VERSION ""

NS_ :

BS_:

BU_: IHU

BO_ 1537 NMm_Others: 8 Vector__XXX
 SG_ Nwmcommand1 : 7|1@0+ (1,0) [0|1] ""  IHU

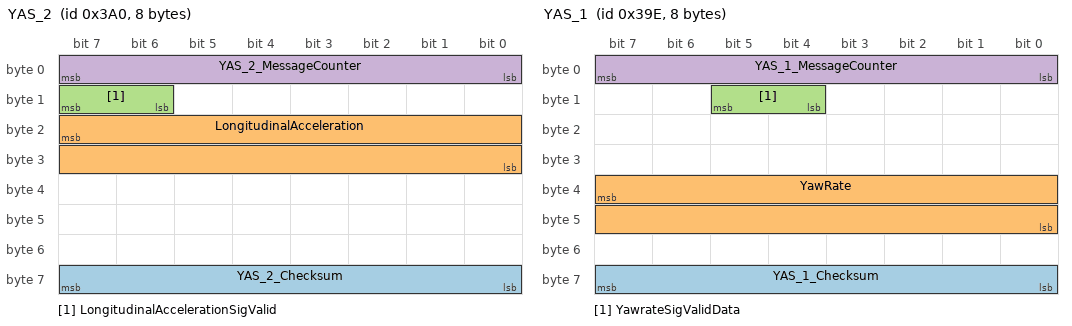
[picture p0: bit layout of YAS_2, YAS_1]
BO_ 928 YAS_2: 8 Vector__XXX
 SG_ YAS_2_Checksum : 63|8@0+ (1,0) [0|255] ""  IHU
 SG_ LongitudinalAcceleration : 23|16@0+ (0.001,-2) [-2|2] "g"  IHU
 SG_ LongitudinalAccelerationSigValid : 15|2@0+ (1,0) [0|3] ""  IHU
 SG_ YAS_2_MessageCounter : 7|8@0+ (1,0) [0|255] ""  IHU

BO_ 926 YAS_1: 8 Vector__XXX
 SG_ YAS_1_Checksum : 63|8@0+ (1,0) [0|255] ""  IHU
 SG_ YawRate : 39|16@0+ (0.01,-180) [-180|180] "deg/sec"  IHU
 SG_ YawrateSigValidData : 13|2@0+ (1,0) [0|3] ""  IHU
 SG_ YAS_1_MessageCounter : 7|8@0+ (1,0) [0|255] ""  IHU

BO_ 1206 SHU2R_1: 8 Vector__XXX
 SG_ SHU2R_RSeatVentnSts : 5|3@0+ (1,0) [0|7] ""  IHU
 SG_ SHU2R_RSeatHeatSts : 2|3@0+ (1,0) [0|7] ""  IHU

BO_ 1202 SHU2M_1: 8 Vector__XXX
 SG_ SHU2M_MSeatVentnSts : 5|3@0+ (1,0) [0|7] ""  IHU
 SG_ SHU2M_MSeatHeatSts : 2|3@0+ (1,0) [0|7] ""  IHU

BO_ 1194 SHU2L_1: 8 Vector__XXX
 SG_ SHU2L_LSeatVentnSts : 5|3@0+ (1,0) [0|7] ""  IHU
 SG_ SHU2L_LSeatHeatSts : 2|3@0+ (1,0) [0|7] ""  IHU

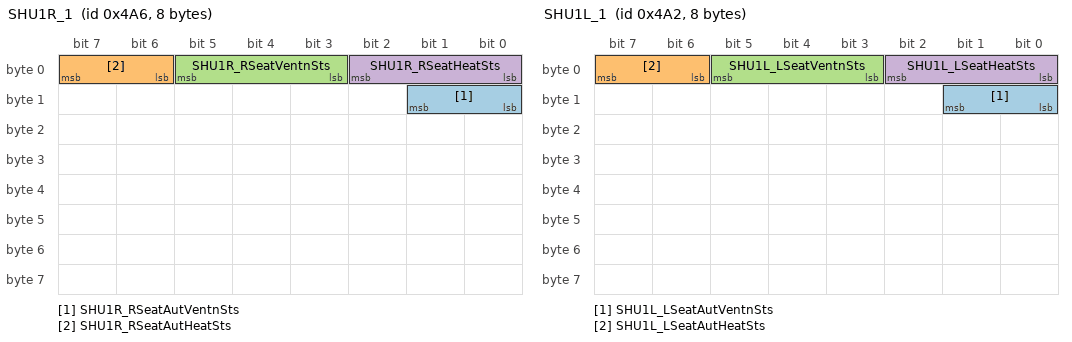
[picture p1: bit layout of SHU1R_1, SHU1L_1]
BO_ 1190 SHU1R_1: 8 Vector__XXX
 SG_ SHU1R_RSeatAutVentnSts : 9|2@0+ (1,0) [0|3] ""  IHU
 SG_ SHU1R_RSeatAutHeatSts : 7|2@0+ (1,0) [0|3] ""  IHU
 SG_ SHU1R_RSeatVentnSts : 5|3@0+ (1,0) [0|7] ""  IHU
 SG_ SHU1R_RSeatHeatSts : 2|3@0+ (1,0) [0|7] ""  IHU

BO_ 1186 SHU1L_1: 8 Vector__XXX
 SG_ SHU1L_LSeatAutVentnSts : 9|2@0+ (1,0) [0|3] ""  IHU
 SG_ SHU1L_LSeatAutHeatSts : 7|2@0+ (1,0) [0|3] ""  IHU
 SG_ SHU1L_LSeatVentnSts : 5|3@0+ (1,0) [0|7] ""  IHU
 SG_ SHU1L_LSeatHeatSts : 2|3@0+ (1,0) [0|7] ""  IHU

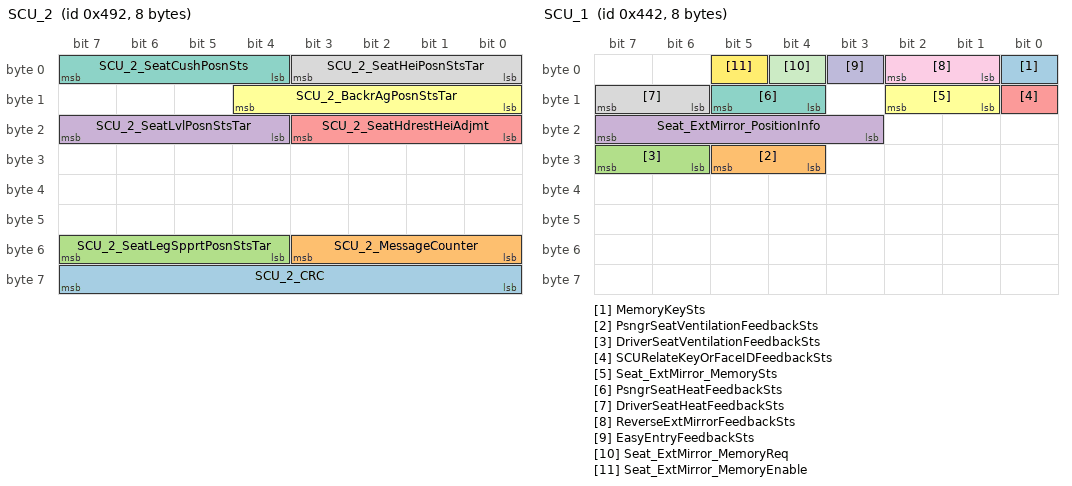
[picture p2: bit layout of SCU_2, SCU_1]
BO_ 1170 SCU_2: 8 Vector__XXX
 SG_ SCU_2_CRC : 63|8@0+ (1,0) [0|255] ""  IHU
 SG_ SCU_2_MessageCounter : 51|4@0+ (1,0) [0|15] ""  IHU
 SG_ SCU_2_SeatLegSpprtPosnStsTar : 55|4@0+ (10,0) [0|100] "%"  IHU
 SG_ SCU_2_SeatLvlPosnStsTar : 23|4@0+ (10,0) [0|100] "%"  IHU
 SG_ SCU_2_SeatHdrestHeiAdjmt : 19|4@0+ (10,0) [0|100] "%"  IHU
 SG_ SCU_2_BackrAgPosnStsTar : 12|5@0+ (5,0) [0|100] "%"  IHU
 SG_ SCU_2_SeatCushPosnSts : 7|4@0+ (10,0) [0|100] "%"  IHU
 SG_ SCU_2_SeatHeiPosnStsTar : 3|4@0+ (10,0) [0|100] "%"  IHU

BO_ 1090 SCU_1: 8 Vector__XXX
 SG_ MemoryKeySts : 0|1@0+ (1,0) [0|1] ""  IHU
 SG_ PsngrSeatVentilationFeedbackSts : 29|2@0+ (1,0) [0|3] ""  IHU
 SG_ DriverSeatVentilationFeedbackSts : 31|2@0+ (1,0) [0|3] ""  IHU
 SG_ Seat_ExtMirror_PositionInfo : 23|5@0+ (1,0) [0|31] ""  IHU
 SG_ SCURelateKeyOrFaceIDFeedbackSts : 8|1@0+ (1,0) [0|1] ""  IHU
 SG_ Seat_ExtMirror_MemorySts : 10|2@0+ (1,0) [0|3] ""  IHU
 SG_ PsngrSeatHeatFeedbackSts : 13|2@0+ (1,0) [0|3] ""  IHU
 SG_ DriverSeatHeatFeedbackSts : 15|2@0+ (1,0) [0|3] ""  IHU
 SG_ ReverseExtMirrorFeedbackSts : 2|2@0+ (1,0) [0|3] ""  IHU
 SG_ EasyEntryFeedbackSts : 3|1@0+ (1,0) [0|1] ""  IHU
 SG_ Seat_ExtMirror_MemoryReq : 4|1@0+ (1,0) [0|1] ""  IHU
 SG_ Seat_ExtMirror_MemoryEnable : 5|1@0+ (1,0) [0|1] ""  IHU

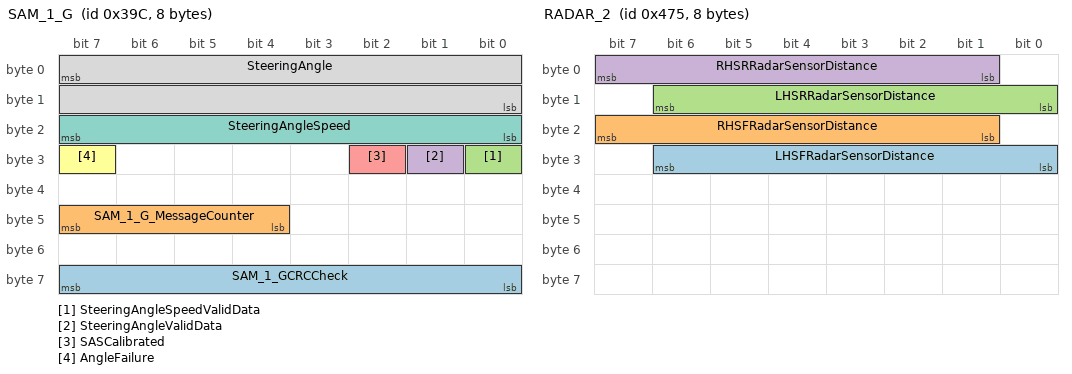
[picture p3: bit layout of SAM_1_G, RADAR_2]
BO_ 924 SAM_1_G: 8 Vector__XXX
 SG_ SAM_1_GCRCCheck : 63|8@0+ (1,0) [0|255] ""  IHU
 SG_ SAM_1_G_MessageCounter : 47|4@0+ (1,0) [0|15] ""  IHU
 SG_ SteeringAngleSpeedValidData : 24|1@0+ (1,0) [0|1] ""  IHU
 SG_ SteeringAngleValidData : 25|1@0+ (1,0) [0|1] ""  IHU
 SG_ SASCalibrated : 26|1@0+ (1,0) [0|1] ""  IHU
 SG_ AngleFailure : 31|1@0+ (1,0) [0|1] ""  IHU
 SG_ SteeringAngleSpeed : 23|8@0+ (4,0) [0|1016] "deg/Sec"  IHU
 SG_ SteeringAngle : 7|16@0+ (0.0625,-2048) [-2048|2047.875] "deg"  IHU

BO_ 498 RLCR_2: 8 Vector__XXX
 SG_ RLCR_2_RCTBONOFFSts : 5|2@0+ (1,0) [0|3] ""  IHU
 SG_ RLCR_2_RAEBONOFFSts : 3|2@0+ (1,0) [0|3] ""  IHU

BO_ 1141 RADAR_2: 8 Vector__XXX
 SG_ LHSFRadarSensorDistance : 30|7@0+ (5,30) [30|500] "cm"  IHU
 SG_ RHSFRadarSensorDistance : 23|7@0+ (5,30) [30|500] "cm"  IHU
 SG_ LHSRRadarSensorDistance : 14|7@0+ (5,30) [30|500] "cm"  IHU
 SG_ RHSRRadarSensorDistance : 7|7@0+ (5,30) [30|500] "cm"  IHU

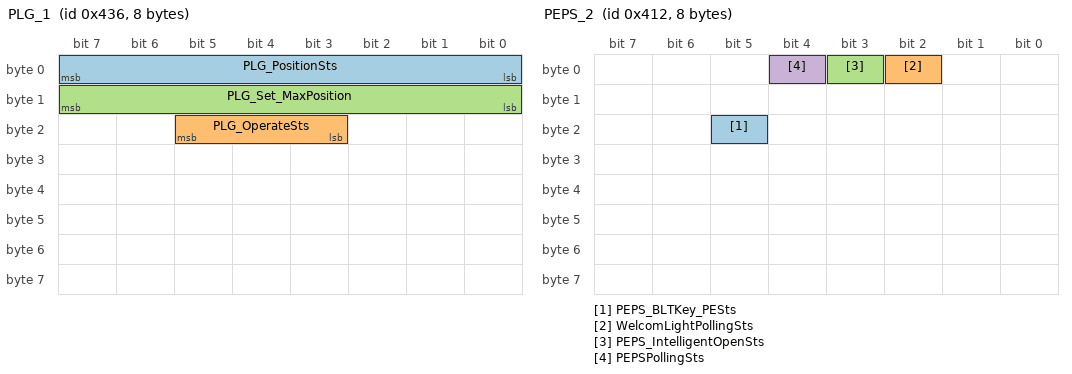
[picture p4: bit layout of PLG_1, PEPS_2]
BO_ 1078 PLG_1: 8 Vector__XXX
 SG_ PLG_PositionSts : 7|8@0+ (1,0) [0|100] "%"  IHU
 SG_ PLG_OperateSts : 21|3@0+ (1,0) [0|7] ""  IHU
 SG_ PLG_Set_MaxPosition : 15|8@0+ (1,0) [0|100] "%"  IHU

BO_ 1042 PEPS_2: 8 Vector__XXX
 SG_ PEPS_BLTKey_PESts : 21|1@0+ (1,0) [0|1] ""  IHU
 SG_ WelcomLightPollingSts : 2|1@0+ (1,0) [0|1] ""  IHU
 SG_ PEPS_IntelligentOpenSts : 3|1@0+ (1,0) [0|1] ""  IHU
 SG_ PEPSPollingSts : 4|1@0+ (1,0) [0|1] ""  IHU

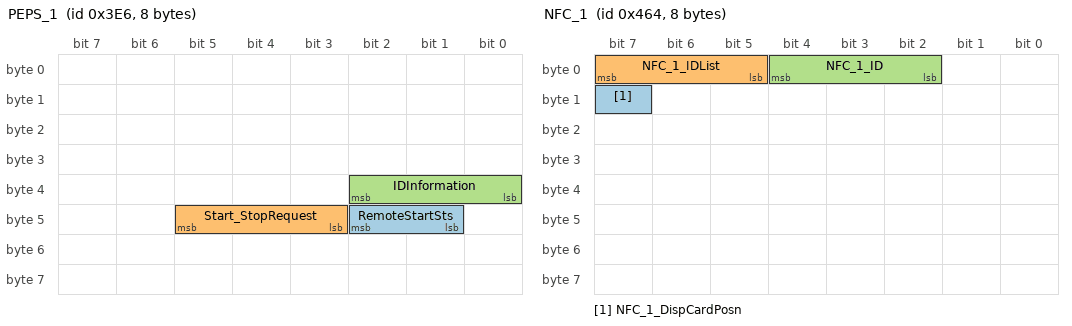
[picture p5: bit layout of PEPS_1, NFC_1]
BO_ 998 PEPS_1: 8 Vector__XXX
 SG_ RemoteStartSts : 42|2@0+ (1,0) [0|3] ""  IHU
 SG_ Start_StopRequest : 45|3@0+ (1,0) [0|7] ""  IHU
 SG_ IDInformation : 34|3@0+ (1,0) [0|7] ""  IHU

BO_ 1124 NFC_1: 8 Vector__XXX
 SG_ NFC_1_DispCardPosn : 15|1@0+ (1,0) [0|1] ""  IHU
 SG_ NFC_1_IDList : 7|3@0+ (1,0) [0|7] ""  IHU
 SG_ NFC_1_ID : 4|3@0+ (1,0) [0|7] ""  IHU

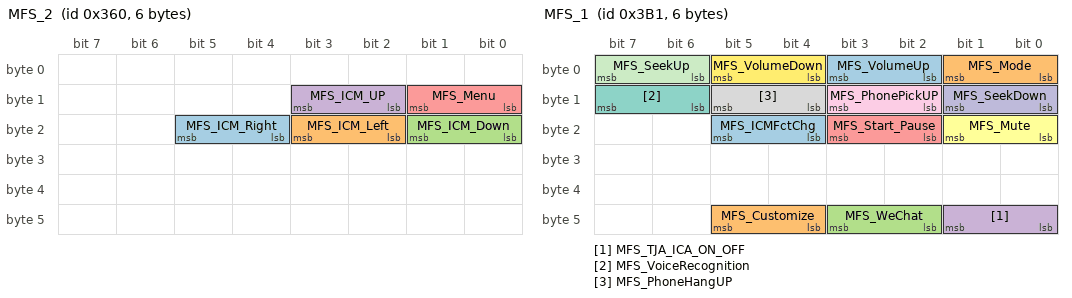
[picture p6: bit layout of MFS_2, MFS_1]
BO_ 864 MFS_2: 6 Vector__XXX
 SG_ MFS_ICM_Right : 21|2@0+ (1,0) [0|3] ""  IHU
 SG_ MFS_ICM_Left : 19|2@0+ (1,0) [0|3] ""  IHU
 SG_ MFS_ICM_Down : 17|2@0+ (1,0) [0|3] ""  IHU
 SG_ MFS_ICM_UP : 11|2@0+ (1,0) [0|3] ""  IHU
 SG_ MFS_Menu : 9|2@0+ (1,0) [0|3] ""  IHU

BO_ 945 MFS_1: 6 Vector__XXX
 SG_ MFS_ICMFctChg : 21|2@0+ (1,0) [0|3] "" Vector__XXX
 SG_ MFS_Customize : 45|2@0+ (1,0) [0|3] ""  IHU
 SG_ MFS_WeChat : 43|2@0+ (1,0) [0|3] ""  IHU
 SG_ MFS_TJA_ICA_ON_OFF : 41|2@0+ (1,0) [0|3] ""  IHU
 SG_ MFS_Start_Pause : 19|2@0+ (1,0) [0|3] ""  IHU
 SG_ MFS_Mute : 17|2@0+ (1,0) [0|3] ""  IHU
 SG_ MFS_VoiceRecognition : 15|2@0+ (1,0) [0|3] ""  IHU
 SG_ MFS_PhoneHangUP : 13|2@0+ (1,0) [0|3] ""  IHU
 SG_ MFS_PhonePickUP : 11|2@0+ (1,0) [0|3] ""  IHU
 SG_ MFS_SeekDown : 9|2@0+ (1,0) [0|3] ""  IHU
 SG_ MFS_SeekUp : 7|2@0+ (1,0) [0|3] ""  IHU
 SG_ MFS_VolumeDown : 5|2@0+ (1,0) [0|3] ""  IHU
 SG_ MFS_VolumeUp : 3|2@0+ (1,0) [0|3] ""  IHU
 SG_ MFS_Mode : 1|2@0+ (1,0) [0|3] ""  IHU

BO_ 1149 IMMO_12: 8 Vector__XXX
 SG_ IMMO_Teach : 7|64@0+ (1,0) [0|0] ""  IHU

BO_ 1110 IMMO_11: 8 Vector__XXX
 SG_ IMMO_Chall : 7|64@0+ (1,0) [0|0] ""  IHU

BO_ 1508 ICM_IHU_Interaction: 8 Vector__XXX
 SG_ ICM_4_InteractiveDisplayInfo : 7|64@0+ (1,0) [0|0] ""  IHU

BO_ 1248 IDCU_11: 8 Vector__XXX
 SG_ IDCU_11_DrvAssiStylests : 8|2@0+ (1,0) [0|3] ""  IHU
 SG_ IDCU_11_DCLCONOFFsts : 10|2@0+ (1,0) [0|3] ""  IHU

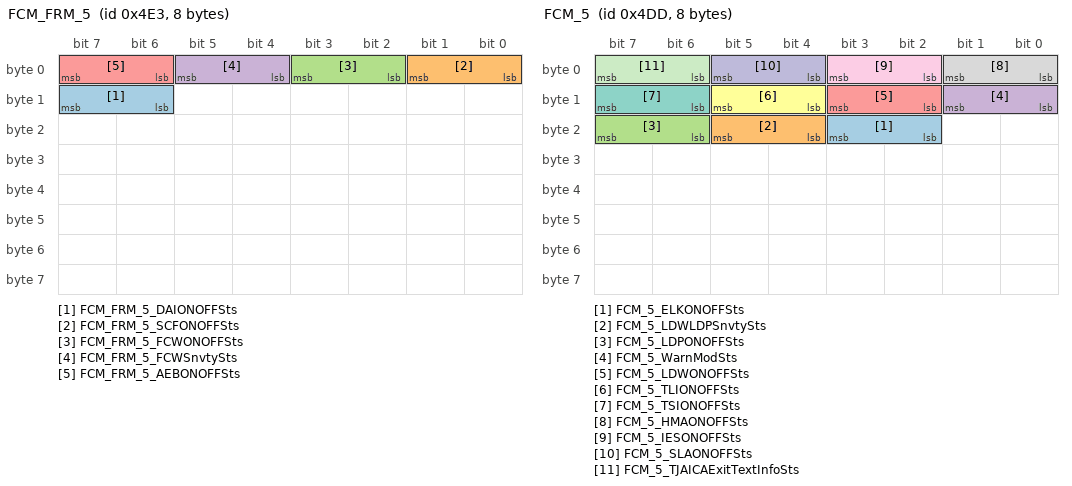
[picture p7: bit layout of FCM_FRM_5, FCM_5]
BO_ 1251 FCM_FRM_5: 8 Vector__XXX
 SG_ FCM_FRM_5_DAIONOFFSts : 15|2@0+ (1,0) [0|3] ""  IHU
 SG_ FCM_FRM_5_SCFONOFFSts : 1|2@0+ (1,0) [0|3] ""  IHU
 SG_ FCM_FRM_5_FCWONOFFSts : 3|2@0+ (1,0) [0|3] ""  IHU
 SG_ FCM_FRM_5_FCWSnvtySts : 5|2@0+ (1,0) [0|3] ""  IHU
 SG_ FCM_FRM_5_AEBONOFFSts : 7|2@0+ (1,0) [0|3] ""  IHU

BO_ 1245 FCM_5: 8 Vector__XXX
 SG_ FCM_5_ELKONOFFSts : 19|2@0+ (1,0) [0|3] ""  IHU
 SG_ FCM_5_LDWLDPSnvtySts : 21|2@0+ (1,0) [0|3] ""  IHU
 SG_ FCM_5_LDPONOFFSts : 23|2@0+ (1,0) [0|3] ""  IHU
 SG_ FCM_5_WarnModSts : 9|2@0+ (1,0) [0|3] ""  IHU
 SG_ FCM_5_LDWONOFFSts : 11|2@0+ (1,0) [0|3] ""  IHU
 SG_ FCM_5_TLIONOFFSts : 13|2@0+ (1,0) [0|3] ""  IHU
 SG_ FCM_5_TSIONOFFSts : 15|2@0+ (1,0) [0|3] ""  IHU
 SG_ FCM_5_HMAONOFFSts : 1|2@0+ (1,0) [0|3] ""  IHU
 SG_ FCM_5_IESONOFFSts : 3|2@0+ (1,0) [0|3] ""  IHU
 SG_ FCM_5_SLAONOFFSts : 5|2@0+ (1,0) [0|3] ""  IHU
 SG_ FCM_5_TJAICAExitTextInfoSts : 7|2@0+ (1,0) [0|3] ""  IHU

BO_ 1240 EMS_3_G: 8 Vector__XXX
 SG_ EMS_BoostP : 39|16@0+ (0.078125,0) [0|5119] "hPa"  IHU

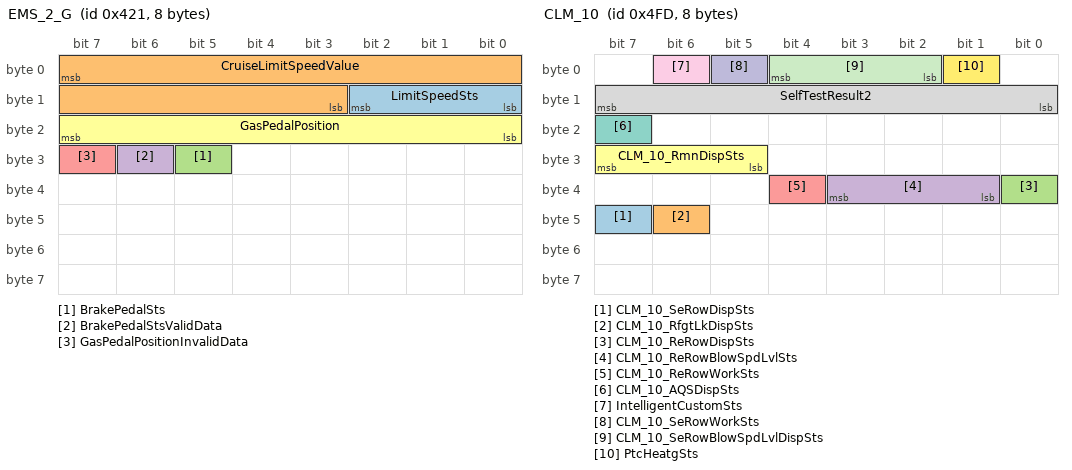
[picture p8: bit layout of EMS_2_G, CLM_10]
BO_ 1057 EMS_2_G: 8 Vector__XXX
 SG_ LimitSpeedSts : 10|3@0+ (1,0) [0|7] ""  IHU
 SG_ CruiseLimitSpeedValue : 7|13@0+ (0.0625,0) [0|511.875] "km/h"  IHU
 SG_ BrakePedalSts : 29|1@0+ (1,0) [0|1] ""  IHU
 SG_ BrakePedalStsValidData : 30|1@0+ (1,0) [0|1] ""  IHU
 SG_ GasPedalPositionInvalidData : 31|1@0+ (1,0) [0|1] ""  IHU
 SG_ GasPedalPosition : 23|8@0+ (0.392,0) [0|99.568] "%"  IHU

BO_ 1277 CLM_10: 8 Vector__XXX
 SG_ CLM_10_SeRowDispSts : 47|1@0+ (1,0) [0|1] ""  IHU
 SG_ CLM_10_RfgtLkDispSts : 46|1@0+ (1,0) [0|1] ""  IHU
 SG_ CLM_10_ReRowDispSts : 32|1@0+ (1,0) [0|1] ""  IHU
 SG_ CLM_10_ReRowBlowSpdLvlSts : 35|3@0+ (1,0) [0|7] ""  IHU
 SG_ CLM_10_ReRowWorkSts : 36|1@0+ (1,0) [0|1] ""  IHU
 SG_ CLM_10_RmnDispSts : 31|3@0+ (1,0) [0|7] ""  IHU
 SG_ CLM_10_AQSDispSts : 23|1@0+ (1,0) [0|1] ""  IHU
 SG_ SelfTestResult2 : 15|8@0+ (1,0) [0|255] ""  IHU
 SG_ IntelligentCustomSts : 6|1@0+ (1,0) [0|1] ""  IHU
 SG_ CLM_10_SeRowWorkSts : 5|1@0+ (1,0) [0|1] ""  IHU
 SG_ CLM_10_SeRowBlowSpdLvlDispSts : 4|3@0+ (1,0) [0|7] ""  IHU
 SG_ PtcHeatgSts : 1|1@0+ (1,0) [0|1] ""  IHU

BO_ 1334 CLM_3: 8 Vector__XXX
 SG_ FragranCeconsistenceLevelSts : 58|3@0+ (1,0) [0|7] ""  IHU
 SG_ Pos3_FragranceTypesSts : 49|3@0+ (1,0) [0|7] ""  IHU
 SG_ Pos2_FragranceTypesSts : 62|3@0+ (1,0) [0|7] ""  IHU
 SG_ PM2_5AutoRunSetSts : 59|1@0+ (1,0) [0|1] ""  IHU
 SG_ PM2_5_Incar_Level : 52|3@0+ (1,0) [0|7] ""  IHU
 SG_ PM2_5_Outcar_Level : 55|3@0+ (1,0) [0|7] ""  IHU
 SG_ FragranceDisplaysts : 40|1@0+ (1,0) [0|1] ""  IHU
 SG_ FragrancePositionSwt : 24|2@0+ (1,0) [0|3] ""  IHU
 SG_ ACModeCustomSts : 42|2@0+ (1,0) [0|3] ""  IHU
 SG_ FragranceWelcomeModeSts : 44|1@0+ (1,0) [0|1] ""  IHU
 SG_ RefreshFunctionSts : 43|1@0+ (1,0) [0|1] ""  IHU
 SG_ Pos1_FragranceTypesSts : 47|3@0+ (1,0) [0|7] ""  IHU
 SG_ PM2_5AutoRunSts : 33|1@0+ (1,0) [0|1] ""  IHU
 SG_ FragranceSWSts : 36|2@0+ (1,0) [0|3] ""  IHU
 SG_ AutoBltCalllowBlowSpeedSts : 37|1@0+ (1,0) [0|1] ""  IHU
 SG_ AutoParkInnerCirculationSts : 38|1@0+ (1,0) [0|1] ""  IHU
 SG_ PM2_5_IncarSts : 26|1@0+ (1,0) [0|1] ""  IHU
 SG_ PM2_5_ExtSts : 27|1@0+ (1,0) [0|1] ""  IHU
 SG_ PM2_5_ext : 23|10@0+ (1,0) [0|1000] "ug/m3"  IHU
 SG_ FragranceShortageWarning : 6|3@0+ (1,0) [0|7] ""  IHU
 SG_ ION_Function_Sts : 3|2@0+ (1,0) [0|3] ""  IHU
 SG_ PM2_5_incar : 1|10@0+ (1,0) [0|1000] "ug/m3"  IHU

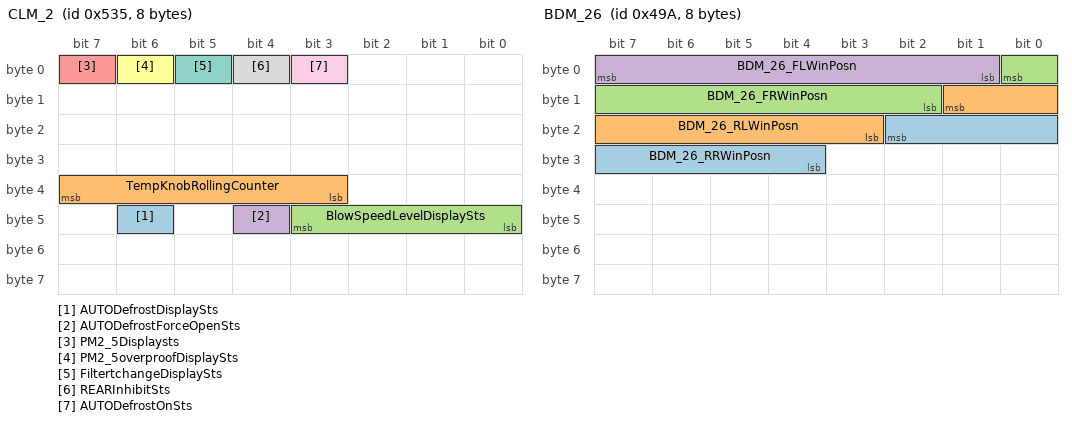
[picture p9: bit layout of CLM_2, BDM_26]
BO_ 1333 CLM_2: 8 Vector__XXX
 SG_ AUTODefrostDisplaySts : 46|1@0+ (1,0) [0|1] ""  IHU
 SG_ TempKnobRollingCounter : 39|5@0+ (1,0) [0|31] ""  IHU
 SG_ BlowSpeedLevelDisplaySts : 43|4@0+ (1,0) [0|15] ""  IHU
 SG_ AUTODefrostForceOpenSts : 44|1@0+ (1,0) [0|1] ""  IHU
 SG_ PM2_5Displaysts : 7|1@0+ (1,0) [0|1] ""  IHU
 SG_ PM2_5overproofDisplaySts : 6|1@0+ (1,0) [0|1] ""  IHU
 SG_ FiltertchangeDisplaySts : 5|1@0+ (1,0) [0|1] ""  IHU
 SG_ REARInhibitSts : 4|1@0+ (1,0) [0|1] ""  IHU
 SG_ AUTODefrostOnSts : 3|1@0+ (1,0) [0|1] ""  IHU

BO_ 1306 CLM_1: 8 Vector__XXX
 SG_ SetTemperature_R_F : 61|5@0+ (2,58) [58|90] "℉"  IHU
 SG_ SetTemperature_L_F : 50|5@0+ (2,58) [58|90] "℉"  IHU
 SG_ SelfTestResult : 55|5@0+ (1,0) [0|31] ""  IHU
 SG_ TemperatureUnit : 40|1@0+ (1,0) [0|1] ""  IHU
 SG_ ZoneSelectionDisplaySts : 41|1@0+ (1,0) [0|1] ""  IHU
 SG_ CirculationModeDisplaySts : 42|1@0+ (1,0) [0|1] ""  IHU
 SG_ SetTemperature_R_C : 47|5@0+ (1,15) [15|31] "℃"  IHU
 SG_ SetTemperature_L_C : 39|5@0+ (1,15) [15|31] "℃"  IHU
 SG_ BlowDelayOffSts : 34|1@0+ (1,0) [0|1] ""  IHU
 SG_ BlowAdvanceOnSts : 33|1@0+ (1,0) [0|1] ""  IHU
 SG_ DisplayActive : 32|1@0+ (1,0) [0|1] ""  IHU
 SG_ SelfTestActive : 27|1@0+ (1,0) [0|1] ""  IHU
 SG_ PM2_5Sts : 26|1@0+ (1,0) [0|1] ""  IHU
 SG_ WorkingSts : 25|1@0+ (1,0) [0|1] ""  IHU
 SG_ ModeAdjustDisplaySts : 30|3@0+ (1,0) [0|7] ""  IHU
 SG_ FrontDeforest_MaxDisplaySts : 31|1@0+ (1,0) [0|1] ""  IHU
 SG_ ACRequestDisplaySts : 19|1@0+ (1,0) [0|1] ""  IHU
 SG_ AutoDisplaySts : 20|1@0+ (1,0) [0|1] ""  IHU
 SG_ Reserved_AC_MaxSts : 22|1@0+ (1,0) [0|1] ""  IHU
 SG_ ExternalTemperatureFailSts : 23|1@0+ (1,0) [0|1] ""  IHU
 SG_ ExternalTemperature_C : 15|8@0+ (0.5,-55) [-55|70] "°C"  IHU
 SG_ ExternalTemperature_F : 7|8@0+ (1,-67) [-67|158] "°F"  IHU

BO_ 1104 CGW_1: 8 Vector__XXX
 SG_ OBDDiagnosisReqInd : 7|1@0+ (1,0) [0|1] ""  IHU

BO_ 1178 BDM_26: 8 Vector__XXX
 SG_ BDM_26_RRWinPosn : 18|7@0+ (1,0) [0|100] "%"  IHU
 SG_ BDM_26_RLWinPosn : 9|7@0+ (1,0) [0|100] "%"  IHU
 SG_ BDM_26_FRWinPosn : 0|7@0+ (1,0) [0|100] "%"  IHU
 SG_ BDM_26_FLWinPosn : 7|7@0+ (1,0) [0|100] "%"  IHU

BO_ 1007 BDM_25: 8 Vector__XXX
 SG_ BDM_25_AmbBrightness : 23|12@0+ (20,0) [0|81880] "Lux"  IHU
 SG_ BDM_25_FWBrightness : 1|10@0+ (6,0) [0|6126] "Lux"  IHU

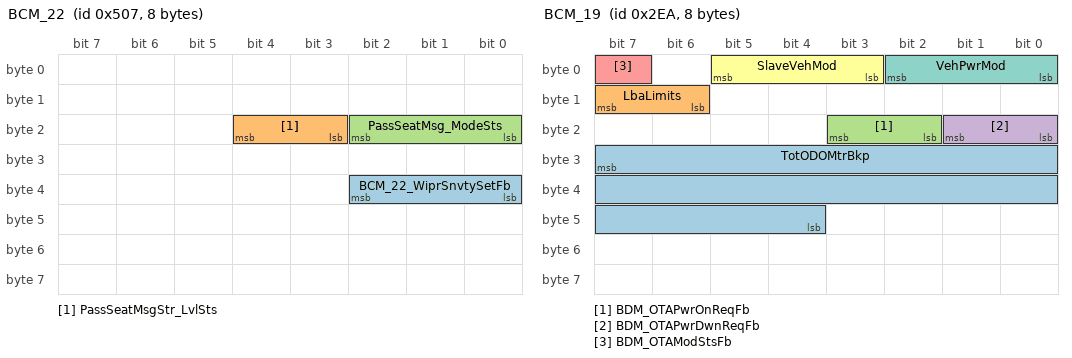
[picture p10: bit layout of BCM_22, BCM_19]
BO_ 1287 BCM_22: 8 Vector__XXX
 SG_ BCM_22_WiprSnvtySetFb : 34|3@0+ (1,0) [0|7] ""  IHU
 SG_ PassSeatMsgStr_LvlSts : 20|2@0+ (1,0) [0|3] ""  IHU
 SG_ PassSeatMsg_ModeSts : 18|3@0+ (1,0) [0|7] ""  IHU

BO_ 746 BCM_19: 8 Vector__XXX
 SG_ TotODOMtrBkp : 31|20@0+ (1,0) [0|999999] "km"  IHU
 SG_ LbaLimits : 15|2@0+ (1,0) [0|3] ""  IHU
 SG_ BDM_OTAPwrOnReqFb : 19|2@0+ (1,0) [0|3] ""  IHU
 SG_ BDM_OTAPwrDwnReqFb : 17|2@0+ (1,0) [0|3] ""  IHU
 SG_ BDM_OTAModStsFb : 7|1@0+ (1,0) [0|1] ""  IHU
 SG_ SlaveVehMod : 5|3@0+ (1,0) [0|7] ""  IHU
 SG_ VehPwrMod : 2|3@0+ (1,0) [0|7] ""  IHU

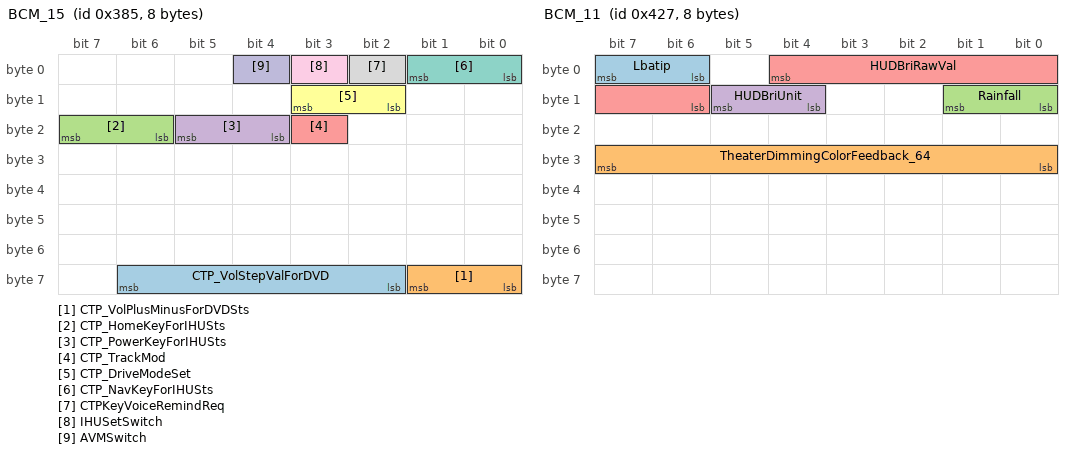
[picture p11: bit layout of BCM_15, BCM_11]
BO_ 901 BCM_15: 8 Vector__XXX
 SG_ CTP_VolStepValForDVD : 62|5@0+ (1,0) [0|31] "Grid"  IHU
 SG_ CTP_VolPlusMinusForDVDSts : 57|2@0+ (1,0) [0|3] ""  IHU
 SG_ CTP_HomeKeyForIHUSts : 23|2@0+ (1,0) [0|3] ""  IHU
 SG_ CTP_PowerKeyForIHUSts : 21|2@0+ (1,0) [0|3] ""  IHU
 SG_ CTP_TrackMod : 19|1@0+ (1,0) [0|1] ""  IHU
 SG_ CTP_DriveModeSet : 11|2@0+ (1,0) [0|3] ""  IHU
 SG_ CTP_NavKeyForIHUSts : 1|2@0+ (1,0) [0|3] ""  IHU
 SG_ CTPKeyVoiceRemindReq : 2|1@0+ (1,0) [0|1] ""  IHU
 SG_ IHUSetSwitch : 3|1@0+ (1,0) [0|1] ""  IHU
 SG_ AVMSwitch : 4|1@0+ (1,0) [0|1] ""  IHU

BO_ 936 BCM_13: 8 Vector__XXX
 SG_ IBS_SOH : 55|8@0+ (1,0) [0|255] "%"  IHU
 SG_ IBS_SOC : 23|8@0+ (1,0) [0|255] "%"  IHU

BO_ 934 BCM_12: 8 Vector__XXX
 SG_ IBS_Current : 39|16@0+ (1,0) [0|0] "A"  IHU
 SG_ IBS_Voltage : 21|14@0+ (0.000976563,3) [3|18] "V"  IHU

BO_ 1063 BCM_11: 8 Vector__XXX
 SG_ Lbatip : 7|2@0+ (1,0) [0|3] ""  IHU
 SG_ TheaterDimmingColorFeedback_64 : 31|8@0+ (1,0) [0|255] ""  IHU
 SG_ Rainfall : 9|2@0+ (1,0) [0|3] ""  IHU
 SG_ HUDBriUnit : 13|2@0+ (1,0) [0|3] ""  IHU
 SG_ HUDBriRawVal : 4|7@0+ (1,0) [0|126] ""  IHU

BO_ 1520 BCM_10: 8 Vector__XXX
 SG_ MessageCounter10 m10 : 59|4@0+ (1,0) [0|15] ""  IHU
 SG_ MessageCounter9 m9 : 59|4@0+ (1,0) [0|15] ""  IHU
 SG_ MessageCounter8 m8 : 59|4@0+ (1,0) [0|15] ""  IHU
 SG_ Secondintervalmaintainmileage3 m9 : 29|3@0+ (1,0) [0|7] ""  IHU
 SG_ MaintainMileage3 m9 : 26|3@0+ (1,0) [0|7] ""  IHU
 SG_ Brand m9 : 23|4@0+ (1,0) [0|15] ""  IHU
 SG_ MessageCounter7 m7 : 59|4@0+ (1,0) [0|15] ""  IHU
 SG_ InitialFuelConsumption2 m8 : 15|8@0+ (1,0) [0|127] ""  IHU
 SG_ MessageCounter6 m6 : 59|4@0+ (1,0) [0|15] ""  IHU
 SG_ RRCR m6 : 62|1@0+ (1,0) [0|1] ""  IHU
 SG_ RLCR m6 : 61|1@0+ (1,0) [0|1] ""  IHU
 SG_ TrafficJamAssist m6 : 50|1@0+ (1,0) [0|1] ""  IHU
 SG_ LaneDeparturePrevention m6 : 49|1@0+ (1,0) [0|1] ""  IHU
 SG_ EmergencyLaneKeeping m6 : 48|1@0+ (1,0) [0|1] ""  IHU
 SG_ fueltankcapacity m6 : 10|3@0+ (1,0) [0|7] ""  IHU
 SG_ MessageCounter5 m5 : 59|4@0+ (1,0) [0|15] ""  IHU
 SG_ ModelCode m5 : 12|5@0+ (1,0) [0|31] ""  IHU
 SG_ MessageCounter4 m4 : 59|4@0+ (1,0) [0|15] ""  IHU
 SG_ NumberofDriveMode2_IHU_TIHU_ m4 : 51|3@0+ (1,0) [0|7] ""  IHU
 SG_ Facestyle m4 : 40|1@0+ (1,0) [0|1] ""  IHU
 SG_ SpeedLimit m4 : 33|1@0+ (1,0) [0|1] ""  IHU
 SG_ Secondintervalmaintainmileage2 m4 : 31|2@0+ (1,0) [0|3] ""  IHU
 SG_ MaintainMileage2 m4 : 29|2@0+ (1,0) [0|3] ""  IHU
 SG_ Defaultdrivemode m4 : 27|2@0+ (1,0) [0|3] ""  IHU
 SG_ NumberofDriveMode m4 : 25|2@0+ (1,0) [0|3] ""  IHU
 SG_ ICMVehicleType m4 : 15|4@0+ (1,0) [0|15] ""  IHU
 SG_ MessageCounter3 m3 : 59|4@0+ (1,0) [0|15] ""  IHU
 SG_ RearRadarsNumber m3 : 63|2@0+ (1,0) [0|3] ""  IHU
 SG_ EPBWorkLogic m3 : 55|1@0+ (1,0) [0|1] ""  IHU
 SG_ EGSType m3 : 53|1@0+ (1,0) [0|1] ""  IHU
 SG_ ThrdRowSBRandBucSwt m3 : 43|1@0+ (1,0) [0|1] ""  IHU
 SG_ SecRowSBRandBucSwt m3 : 41|1@0+ (1,0) [0|1] ""  IHU
 SG_ APA m3 : 8|1@0+ (1,0) [0|1] ""  IHU
 SG_ MessageCounter2 m2 : 59|4@0+ (1,0) [0|15] ""  IHU
 SG_ LKA m2 : 47|1@0+ (1,0) [0|1] ""  IHU
 SG_ MessageCounter1 m1 : 59|4@0+ (1,0) [0|15] ""  IHU
 SG_ EBS m1 : 23|1@0+ (1,0) [0|1] ""  IHU
 SG_ EGS m1 : 8|1@0+ (1,0) [0|1] ""  IHU
 SG_ SN M : 3|4@0+ (1,0) [0|15] ""  IHU

BO_ 1077 BCM_9: 8 Vector__XXX
 SG_ RvsExtMirrFbSts : 57|2@0+ (1,0) [0|3] ""  IHU
 SG_ Reserved_RainingWarning : 49|1@0+ (1,0) [0|0] ""  IHU
 SG_ SRF_Hall2SensorError : 47|1@0+ (1,0) [0|1] ""  IHU
 SG_ SRF_Hall1SensorError : 46|1@0+ (1,0) [0|1] ""  IHU
 SG_ SRF_SunroofOverVolt : 45|1@0+ (1,0) [0|1] ""  IHU
 SG_ SRF_SunroofUnderVolt : 44|1@0+ (1,0) [0|1] ""  IHU
 SG_ SRF_LINCommunicationERROR : 43|1@0+ (1,0) [0|1] ""  IHU
 SG_ SRF_SwitchError : 42|1@0+ (1,0) [0|1] ""  IHU
 SG_ SRF_OverHeatProtect : 41|1@0+ (1,0) [0|1] ""  IHU
 SG_ SRF_MotorRelayError : 40|1@0+ (1,0) [0|1] ""  IHU
 SG_ AssociatedWithDriverModeFeedback : 32|1@0+ (1,0) [0|1] ""  IHU
 SG_ TheaterDimmingBrightnessFeedback : 35|3@0+ (1,0) [0|7] ""  IHU
 SG_ TheaterDimmingColorFeedback : 38|3@0+ (1,0) [0|7] ""  IHU
 SG_ SRF_Sunshade_OperateSts : 25|3@0+ (1,0) [0|7] ""  IHU
 SG_ RRWindowSts : 28|3@0+ (1,0) [0|7] ""  IHU
 SG_ RLWindowSts : 31|3@0+ (1,0) [0|7] ""  IHU
 SG_ WindowInhibitSts : 17|1@0+ (1,0) [0|1] ""  IHU
 SG_ FRWindow_Sts : 20|3@0+ (1,0) [0|7] ""  IHU
 SG_ FLWindow_Sts : 23|3@0+ (1,0) [0|7] ""  IHU
 SG_ Window_OperateSts : 11|2@0+ (1,0) [0|3] ""  IHU
 SG_ Reserved_SRF_Error : 15|4@0+ (1,0) [0|15] ""  IHU
 SG_ SRF_InitStatus : 7|1@0+ (1,0) [0|1] ""  IHU
 SG_ AssociatedWithMusicModeFeedback : 9|1@0+ (1,0) [0|1] ""  IHU
 SG_ TheaterDimmingStatusFeedback : 8|1@0+ (1,0) [0|1] ""  IHU
 SG_ SRF_PositionSts : 6|4@0+ (1,0) [0|15] ""  IHU
 SG_ SRF_OperateSts : 2|3@0+ (1,0) [0|7] ""  IHU

BO_ 1505 BCM_6: 8 Vector__XXX
 SG_ ESCL_CAN : 35|1@0+ (1,0) [0|1] ""  IHU
 SG_ BMS : 23|1@0+ (1,0) [0|1] ""  IHU
 SG_ RRM : 13|1@0+ (1,0) [0|1] ""  IHU
 SG_ PEPSType : 61|2@0+ (1,0) [0|3] ""  IHU
 SG_ EmissionType : 52|1@0+ (1,0) [0|1] ""  IHU
 SG_ TCU3_CVT25_CVT18 : 39|1@0+ (1,0) [0|1] ""  IHU
 SG_ CGW : 38|1@0+ (1,0) [0|1] ""  IHU
 SG_ MFS_LIN : 36|1@0+ (1,0) [0|1] ""  IHU
 SG_ PLG : 34|1@0+ (1,0) [0|1] ""  IHU
 SG_ FRM : 33|1@0+ (1,0) [0|1] ""  IHU
 SG_ FCM : 32|1@0+ (1,0) [0|1] ""  IHU
 SG_ TCU4_7DCT_DHT : 31|1@0+ (1,0) [0|1] ""  IHU
 SG_ EIPM_ONCAN : 30|1@0+ (1,0) [0|1] ""  IHU
 SG_ BSD : 29|1@0+ (1,0) [0|1] ""  IHU
 SG_ EPB : 28|1@0+ (1,0) [0|1] ""  IHU
 SG_ AVM : 25|1@0+ (1,0) [0|1] ""  IHU
 SG_ RADAR : 24|1@0+ (1,0) [0|1] ""  IHU
 SG_ SAS : 17|1@0+ (1,0) [0|1] ""  IHU
 SG_ TPMS : 16|1@0+ (1,0) [0|1] ""  IHU
 SG_ APM : 15|1@0+ (1,0) [0|1] ""  IHU
 SG_ PEPS : 12|1@0+ (1,0) [0|1] ""  IHU
 SG_ EPS : 11|1@0+ (1,0) [0|1] ""  IHU
 SG_ CLM : 10|1@0+ (1,0) [0|1] ""  IHU
 SG_ TCU2_6DCT : 9|1@0+ (1,0) [0|1] ""  IHU
 SG_ TCU1_CVT19 : 8|1@0+ (1,0) [0|1] ""  IHU
 SG_ IMMO : 7|2@0+ (1,0) [0|3] ""  IHU
 SG_ ESP : 5|1@0+ (1,0) [0|1] ""  IHU
 SG_ ABS : 4|1@0+ (1,0) [0|1] ""  IHU
 SG_ ABM : 3|1@0+ (1,0) [0|1] ""  IHU
 SG_ ICM : 2|1@0+ (1,0) [0|1] ""  IHU
 SG_ BCM : 1|1@0+ (1,0) [0|1] ""  IHU
 SG_ EMS : 0|1@0+ (1,0) [0|1] ""  IHU

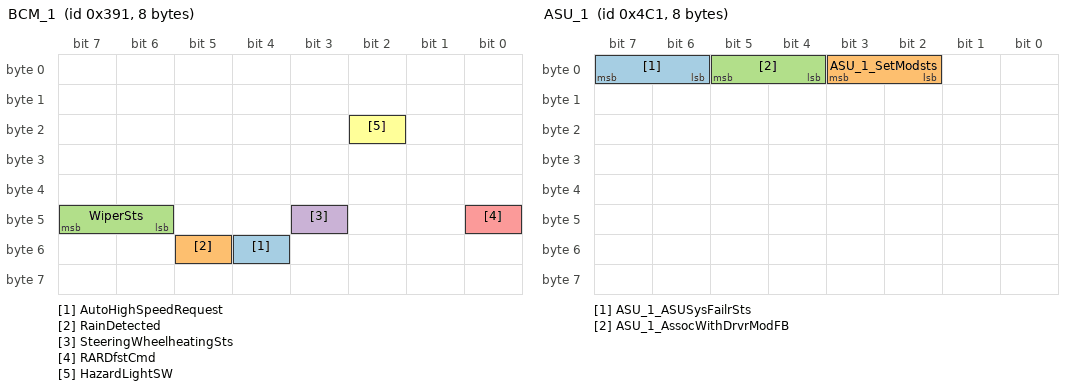
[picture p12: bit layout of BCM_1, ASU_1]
BO_ 913 BCM_1: 8 Vector__XXX
 SG_ AutoHighSpeedRequest : 52|1@0+ (1,0) [0|1] ""  IHU
 SG_ RainDetected : 53|1@0+ (1,0) [0|1] ""  IHU
 SG_ WiperSts : 47|2@0+ (1,0) [0|3] ""  IHU
 SG_ SteeringWheelheatingSts : 43|1@0+ (1,0) [0|1] ""  IHU
 SG_ RARDfstCmd : 40|1@0+ (1,0) [0|1] ""  IHU
 SG_ HazardLightSW : 18|1@0+ (1,0) [0|1] ""  IHU

BO_ 1217 ASU_1: 8 Vector__XXX
 SG_ ASU_1_ASUSysFailrSts : 7|2@0+ (1,0) [0|3] ""  IHU
 SG_ ASU_1_SetModsts : 3|2@0+ (1,0) [0|3] ""  IHU
 SG_ ASU_1_AssocWithDrvrModFB : 5|2@0+ (1,0) [0|3] ""  IHU

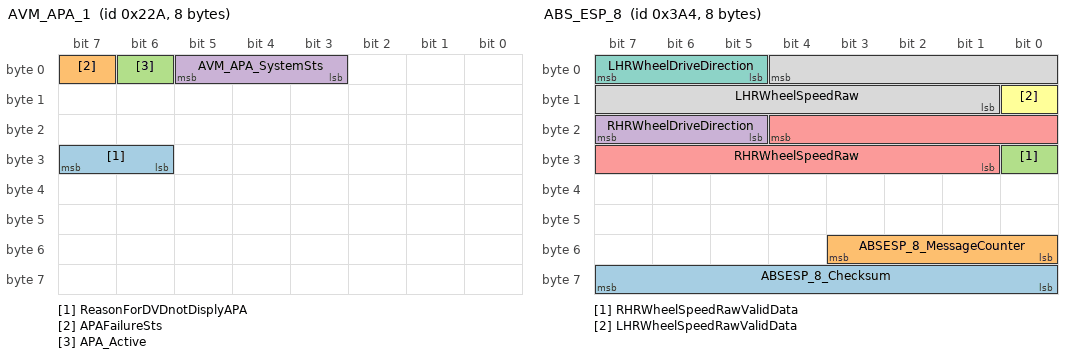
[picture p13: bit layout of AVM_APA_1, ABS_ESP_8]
BO_ 554 AVM_APA_1: 8 Vector__XXX
 SG_ ReasonForDVDnotDisplyAPA : 31|2@0+ (1,0) [0|3] ""  IHU
 SG_ APAFailureSts : 7|1@0+ (1,0) [0|1] ""  IHU
 SG_ APA_Active : 6|1@0+ (1,0) [0|1] ""  IHU
 SG_ AVM_APA_SystemSts : 5|3@0+ (1,0) [0|7] ""  IHU

BO_ 1267 AIPM_2: 8 Vector__XXX
 SG_ AIPM_2_DriveModeSet : 35|2@0+ (1,0) [0|3] ""  IHU

BO_ 1265 AIPM_1: 8 Vector__XXX
 SG_ PanelKeyVoiceRemindReq : 8|1@0+ (1,0) [0|1] ""  IHU

BO_ 932 ABS_ESP_8: 8 Vector__XXX
 SG_ ABSESP_8_Checksum : 63|8@0+ (1,0) [0|255] ""  IHU
 SG_ ABSESP_8_MessageCounter : 51|4@0+ (1,0) [0|15] ""  IHU
 SG_ RHRWheelSpeedRawValidData : 24|1@0+ (1,0) [0|1] ""  IHU
 SG_ RHRWheelDriveDirection : 23|3@0+ (1,0) [0|7] ""  IHU
 SG_ RHRWheelSpeedRaw : 20|12@0+ (0.05,-30) [-30|80] "m/s"  IHU
 SG_ LHRWheelSpeedRawValidData : 8|1@0+ (1,0) [0|1] ""  IHU
 SG_ LHRWheelDriveDirection : 7|3@0+ (1,0) [0|7] ""  IHU
 SG_ LHRWheelSpeedRaw : 4|12@0+ (0.05,-30) [-30|80] "m/s"  IHU

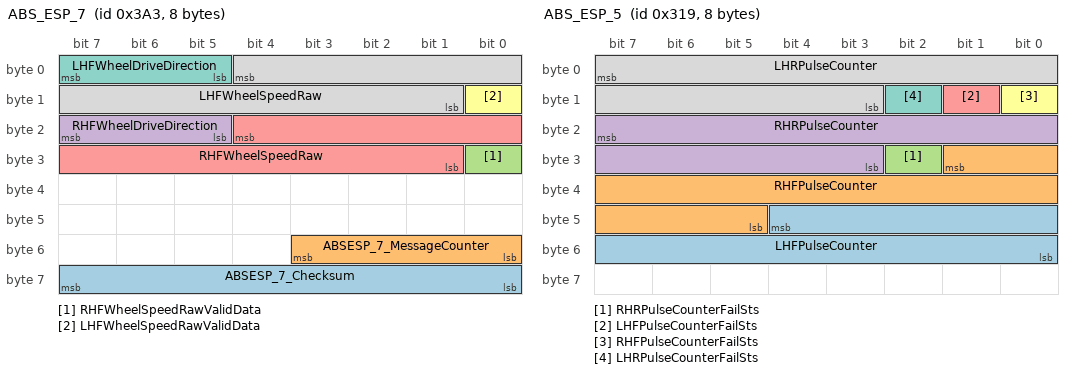
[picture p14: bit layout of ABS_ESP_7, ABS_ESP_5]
BO_ 931 ABS_ESP_7: 8 Vector__XXX
 SG_ ABSESP_7_Checksum : 63|8@0+ (1,0) [0|255] ""  IHU
 SG_ ABSESP_7_MessageCounter : 51|4@0+ (1,0) [0|15] ""  IHU
 SG_ RHFWheelSpeedRawValidData : 24|1@0+ (1,0) [0|1] ""  IHU
 SG_ RHFWheelDriveDirection : 23|3@0+ (1,0) [0|7] ""  IHU
 SG_ RHFWheelSpeedRaw : 20|12@0+ (0.05,-30) [-30|80] "m/s"  IHU
 SG_ LHFWheelSpeedRawValidData : 8|1@0+ (1,0) [0|1] ""  IHU
 SG_ LHFWheelDriveDirection : 7|3@0+ (1,0) [0|7] ""  IHU
 SG_ LHFWheelSpeedRaw : 4|12@0+ (0.05,-30) [-30|80] "m/s"  IHU

BO_ 793 ABS_ESP_5: 8 Vector__XXX
 SG_ LHFPulseCounter : 44|13@0+ (1,0) [0|8191] "pulse"  IHU
 SG_ RHFPulseCounter : 25|13@0+ (1,0) [0|8191] "pulse"  IHU
 SG_ RHRPulseCounterFailSts : 26|1@0+ (1,0) [0|1] ""  IHU
 SG_ RHRPulseCounter : 23|13@0+ (1,0) [0|8191] "pulse"  IHU
 SG_ LHFPulseCounterFailSts : 9|1@0+ (1,0) [0|1] ""  IHU
 SG_ RHFPulseCounterFailSts : 8|1@0+ (1,0) [0|1] ""  IHU
 SG_ LHRPulseCounterFailSts : 10|1@0+ (1,0) [0|1] ""  IHU
 SG_ LHRPulseCounter : 7|13@0+ (1,0) [0|8191] "pulse"  IHU

BO_ 787 ABS_ESP_3: 8 Vector__XXX
 SG_ ABS_ESP_3_AVHSts : 53|2@0+ (1,0) [0|3] ""  IHU
 SG_ ABS_ESP_3_AVHFailSts : 39|1@0+ (1,0) [0|1] ""  IHU

BO_ 1913 DMC_BCM_EBS_RES: 8 Vector__XXX
 SG_ DMC_BCM_EBS_RES : 7|64@0+ (1,0) [0|0] ""  IHU

BO_ 2041 DMC_ACU_RES_EDR: 8 Vector__XXX
 SG_ DMC_ACU_RES_EDR : 7|64@0+ (1,0) [0|0] ""  IHU

BO_ 2030 DMC_DCDC_RES: 8 Vector__XXX
 SG_ DMC_DCDC_RES : 7|64@0+ (1,0) [0|0] ""  IHU

BO_ 2029 DMC_BMS_RES: 8 Vector__XXX
 SG_ DMC_BMS_RES : 7|64@0+ (1,0) [0|0] ""  IHU

BO_ 2027 DMC_BSGF_RES: 8 Vector__XXX
 SG_ DMC_BSG1_RES : 7|64@0+ (1,0) [0|0] ""  IHU

BO_ 2025 DMC_OBD_RES_TCU: 8 Vector__XXX
 SG_ DMC_OBD_RESP_TCU : 7|64@0+ (1,0) [0|0] ""  IHU

BO_ 2024 DMC_OBD_EMS_RES: 8 Vector__XXX
 SG_ DMC_OBD_EMS_RES : 7|64@0+ (1,0) [0|0] ""  IHU

BO_ 2014 DMC_SHU3L_RES: 8 Vector__XXX
 SG_ DMC_SHU3L_RES : 7|64@0+ (1,0) [0|0] ""  IHU

BO_ 2009 DMC_SHU2R_RES: 8 Vector__XXX
 SG_ DMC_SHU2R_RES : 7|64@0+ (1,0) [0|0] ""  IHU

BO_ 2008 DMC_SHU2M_RES: 8 Vector__XXX
 SG_ DMC_SHU2M_RES : 7|64@0+ (1,0) [0|0] ""  IHU

BO_ 2007 DMC_SHU2L_RES: 8 Vector__XXX
 SG_ DMC_SHU2L_RES : 7|64@0+ (1,0) [0|0] ""  IHU

BO_ 2006 DMC_SHU3R_RES: 8 Vector__XXX
 SG_ DMC_SHU3R_RES : 7|64@0+ (1,0) [0|0] ""  IHU

BO_ 1982 DMC_SRFR_RES: 8 Vector__XXX
 SG_ DMC_SRFR_RES : 7|64@0+ (1,0) [0|0] ""  IHU

BO_ 1981 DMC_SRFG_RES: 8 Vector__XXX
 SG_ DMC_SRFG_RES : 7|64@0+ (1,0) [0|0] ""  IHU

BO_ 1980 DMC_SAUR_RES: 8 Vector__XXX
 SG_ DMC_SAUR_RES : 7|64@0+ (1,0) [0|0] ""  IHU

BO_ 1979 DMC_RRPLM_RES: 8 Vector__XXX
 SG_ DMC_RRPLM_RES : 7|64@0+ (1,0) [0|0] ""  IHU

BO_ 1978 DMC_RRFLM_RES: 8 Vector__XXX
 SG_ DMC_RRFLM_RES : 7|64@0+ (1,0) [0|0] ""  IHU

BO_ 1977 DMC_RLPLM_RES: 8 Vector__XXX
 SG_ DMC_RLPLM_RES : 7|64@0+ (1,0) [0|0] ""  IHU

BO_ 1976 DMC_RLFLM_RES: 8 Vector__XXX
 SG_ DMC_RLFLM_RES : 7|64@0+ (1,0) [0|0] ""  IHU

BO_ 1975 DMC_SAUP_RES: 8 Vector__XXX
 SG_ DMC_SAUP_RES : 7|64@0+ (1,0) [0|0] ""  IHU

BO_ 1974 DMC_SHU1P_RES: 8 Vector__XXX
 SG_ DMC_SHU1P_RES : 7|64@0+ (1,0) [0|0] ""  IHU

BO_ 1951 DMC_SAUD_RES: 8 Vector__XXX
 SG_ DMC_SAUD_RES : 7|64@0+ (1,0) [0|0] ""  IHU

BO_ 1949 DMC_NFC_RES: 8 Vector__XXX
 SG_ DMC_NFC_RES : 7|64@0+ (1,0) [0|0] ""  IHU

BO_ 1946 DMC_AIPMR_RES: 8 Vector__XXX
 SG_ DMC__AIPMR_RES : 7|64@0+ (1,0) [0|0] ""  IHU

BO_ 1945 DMC_AIPM_RES: 8 Vector__XXX
 SG_ DMC__AIPM_RES : 7|64@0+ (1,0) [0|0] ""  IHU

BO_ 1938 DMC_SHU1D_RES: 8 Vector__XXX
 SG_ DMC_SHU1D_RES : 7|64@0+ (1,0) [0|0] ""  IHU

BO_ 1936 DMC_SCU_RES: 8 Vector__XXX
 SG_ DMC_SCU_RES : 7|64@0+ (1,0) [0|0] ""  IHU

BO_ 1919 DMC_RHM_RES: 8 Vector__XXX
 SG_ DMC_RHM_RES : 7|64@0+ (1,0) [0|0] ""  IHU

BO_ 1918 DMC_LHM_RES: 8 Vector__XXX
 SG_ DMC_LHM_RES : 7|64@0+ (1,0) [0|0] ""  IHU

BO_ 1917 DMC_ESCL_RES: 8 Vector__XXX
 SG_ DMC_ESCL_RES : 7|64@0+ (1,0) [0|0] ""  IHU

BO_ 1916 DMC_PLG_RES: 8 Vector__XXX
 SG_ DMC_PLG_RES : 7|64@0+ (1,0) [0|0] ""  IHU

BO_ 1910 DMC_AVM_RES: 8 Vector__XXX
 SG_ DMC_AVM_RES : 7|64@0+ (1,0) [0|0] ""  IHU

BO_ 1907 DMC_RADAR_RES: 8 Vector__XXX
 SG_ DMC_RADAR_RES : 7|64@0+ (1,0) [0|0] ""  IHU

BO_ 1906 DMC_CGW_RES: 8 Vector__XXX
 SG_ DMC_CGW_RES : 7|64@0+ (1,0) [0|0] ""  IHU

BO_ 1904 DMC_BDM_RES: 8 Vector__XXX
 SG_ DMC_BDM_RES : 7|64@0+ (1,0) [0|0] ""  IHU

BO_ 1885 DMC_IMMO_RES: 8 Vector__XXX
 SG_ DMC_IMMO_RES : 7|64@0+ (1,0) [0|0] ""  IHU

BO_ 1883 DMC_CLM_RES: 8 Vector__XXX
 SG_ DMC_CLM_RES : 7|64@0+ (1,0) [0|0] ""  IHU

BO_ 1880 DMC_DBL_RES: 8 Vector__XXX
 SG_ DMC_DBL_RES : 7|64@0+ (1,0) [0|0] ""  IHU

BO_ 1879 DMC_ICM_RES: 8 Vector__XXX
 SG_ DMC_ICM_RES : 7|64@0+ (1,0) [0|0] ""  IHU

BO_ 1878 DMC_ACU_RES: 8 Vector__XXX
 SG_ DMC_ACU_RES : 7|64@0+ (1,0) [0|0] ""  IHU

BO_ 1855 DMC_FRM_RES: 8 Vector__XXX
 SG_ DMC_FRM_RES : 7|64@0+ (1,0) [0|0] ""  IHU

BO_ 1854 DMC_FCM_RES: 8 Vector__XXX
 SG_ DMC_FCM_RES : 7|64@0+ (1,0) [0|0] ""  IHU

BO_ 1851 DMC_EGS_RES: 8 Vector__XXX
 SG_ DMC_EGS_RES : 7|64@0+ (1,0) [0|0] ""  IHU

BO_ 1848 DMC_TPMS_RES: 8 Vector__XXX
 SG_ DMC_TPMS_RES : 7|64@0+ (1,0) [0|0] ""  IHU

BO_ 1844 DMC_EPS_RES: 8 Vector__XXX
 SG_ DMC_EPS_RES : 7|64@0+ (1,0) [0|0] ""  IHU

BO_ 1840 DMC_ESP_RES: 8 Vector__XXX
 SG_ DMC_ESP_RES : 7|64@0+ (1,0) [0|0] ""  IHU

BO_ 1823 DMC_GSI_RES: 8 Vector__XXX
 SG_ DMC_GSI_RES : 7|64@0+ (1,0) [0|0] ""  IHU

BO_ 1811 DMC_TCU_RES: 8 Vector__XXX
 SG_ DMC_TCU_RES : 7|64@0+ (1,0) [0|0] ""  IHU

BO_ 1810 DMC_AWD_RES: 8 Vector__XXX
 SG_ DMC_AWD_RES : 7|64@0+ (1,0) [0|0] ""  IHU

BO_ 1809 DMC_FPC_RES: 8 Vector__XXX
 SG_ DMC_FPC_RES : 7|64@0+ (1,0) [0|0] ""  IHU

BO_ 1808 DMC_EMS_RES: 8 Vector__XXX
 SG_ DMC_EMS_RES : 7|64@0+ (1,0) [0|0] ""  IHU

BO_ 2005 DMC_CVBOX_RES: 8 Vector__XXX
 SG_ DMC_CVBOX_RES : 7|64@0+ (1,0) [0|0] ""  IHU

BO_ 1948 DMC_HUD_RES: 8 Vector__XXX
 SG_ DMC_HUD_RES : 7|64@0+ (1,0) [0|0] ""  IHU

BO_ 1874 DMC_DCM_RES: 8 Vector__XXX
 SG_ DMC_DCM_RES : 7|64@0+ (1,0) [0|0] ""  IHU

BO_ 1843 DMC_PPMI_RES: 8 Vector__XXX
 SG_ DMC_PPMI_RES : 7|64@0+ (1,0) [0|0] ""  IHU

BO_ 1905 DMC_SAM_RES: 8 Vector__XXX
 SG_ DMC_SAM_RES : 7|64@0+ (1,0) [0|0] ""  IHU

BO_ 2028 DMC_MCUR_RES: 8 Vector__XXX
 SG_ DMC_MCUR_RES : 7|64@0+ (1,0) [0|0] ""  IHU

BO_ 2026 DMC_HCU_RES: 8 Vector__XXX
 SG_ DMC_HCU_RES : 7|64@0+ (1,0) [0|0] ""  IHU

BO_ 1847 DMC_ASU_RES: 8 Vector__XXX
 SG_ DMC_ASU_RES : 7|64@0+ (1,0) [0|0] ""  IHU

BO_ 2004 DMC_RRCR_RES: 8 Vector__XXX
 SG_ DMC_RRCR_RES : 7|64@0+ (1,0) [0|0] ""  IHU

BO_ 2003 DMC_RLCR_RES: 8 Vector__XXX
 SG_ DMC_RLCR_RES : 7|64@0+ (1,0) [0|0] ""  IHU

BO_ 2002 DMC_FRCR_RES: 8 Vector__XXX
 SG_ DMC_FRCR_RES : 7|64@0+ (1,0) [0|0] ""  IHU

BO_ 2001 DMC_FLCR_RES: 8 Vector__XXX
 SG_ DMC_FLCR_RES : 7|64@0+ (1,0) [0|0] ""  IHU

BO_ 2000 DMC_IDCU_RES: 8 Vector__XXX
 SG_ DMC_IDCU_RES : 7|64@0+ (1,0) [0|0] ""  IHU

BO_ 1897 DMC_BCM_EBS_REQ: 8 IHU
 SG_ DMC_BCM_EBS_REQ : 7|64@0+ (1,0) [0|0] "" Vector__XXX

BO_ 1999 DMC_REQ_Broadcast: 8 IHU
 SG_ DMC_REQ_Broadcast : 7|64@0+ (1,0) [0|0] "" Vector__XXX

BO_ 2033 DMC_ACU_REQ_EDR: 8 IHU
 SG_ DMC_ACU_REQ_EDR : 7|64@0+ (1,0) [0|0] "" Vector__XXX

BO_ 2019 DMC_BSGF_REQ: 8 IHU
 SG_ DMC_BSG1_REQ : 7|64@0+ (1,0) [0|0] "" Vector__XXX

BO_ 2017 DMC_OBD_REQ_TCU: 8 IHU
 SG_ DMC_OBD_REQ_TCU : 7|64@0+ (1,0) [0|0] "" Vector__XXX

BO_ 2016 DMC_OBD_EMS_REQ: 8 IHU
 SG_ DMC_OBD_EMS_REQ : 7|64@0+ (1,0) [0|0] "" Vector__XXX

BO_ 1998 DMC_SHU3L_REQ: 8 IHU
 SG_ DMC_SHU3L_REQ : 7|64@0+ (1,0) [0|0] "" Vector__XXX

BO_ 1993 DMC_SHU2R_REQ: 8 IHU
 SG_ DMC_SHU2R_REQ : 7|64@0+ (1,0) [0|0] "" Vector__XXX

BO_ 1992 DMC_SHU2M_REQ: 8 IHU
 SG_ DMC_SHU2M_REQ : 7|64@0+ (1,0) [0|0] "" Vector__XXX

BO_ 1991 DMC_SHU2L_REQ: 8 IHU
 SG_ DMC_SHU2L_REQ : 7|64@0+ (1,0) [0|0] "" Vector__XXX

BO_ 1990 DMC_SHU3R_REQ: 8 IHU
 SG_ DMC_SHU3R_REQ : 7|64@0+ (1,0) [0|0] "" Vector__XXX

BO_ 1966 DMC_SRFR_REQ: 8 IHU
 SG_ DMC_SRFR_REQ : 7|64@0+ (1,0) [0|0] "" Vector__XXX

BO_ 1965 DMC_SRFG_REQ: 8 IHU
 SG_ DMC_SRFG_REQ : 7|64@0+ (1,0) [0|0] "" Vector__XXX

BO_ 1964 DMC_SAUR_REQ: 8 IHU
 SG_ DMC_SAUR_REQ : 7|64@0+ (1,0) [0|0] "" Vector__XXX

BO_ 1963 DMC_RRPLM_REQ: 8 IHU
 SG_ DMC_RRPLM_REQ : 7|64@0+ (1,0) [0|0] "" Vector__XXX

BO_ 1962 DMC_RRFLM_REQ: 8 IHU
 SG_ DMC_RRFLM_REQ : 7|64@0+ (1,0) [0|0] "" Vector__XXX

BO_ 1961 DMC_RLPLM_REQ: 8 IHU
 SG_ DMC_RLPLM_REQ : 7|64@0+ (1,0) [0|0] "" Vector__XXX

BO_ 1960 DMC_RLFLM_REQ: 8 IHU
 SG_ DMC_RLFLM_REQ : 7|64@0+ (1,0) [0|0] "" Vector__XXX

BO_ 1959 DMC_SAUP_REQ: 8 IHU
 SG_ DMC_SAUP_REQ : 7|64@0+ (1,0) [0|0] "" Vector__XXX

BO_ 1958 DMC_SHU1P_REQ: 8 IHU
 SG_ DMC_SHU1P_REQ : 7|64@0+ (1,0) [0|0] "" Vector__XXX

BO_ 1943 DMC_EAMP_RES: 8 Vector__XXX
 SG_ DMC_EAMP_RES : 7|64@0+ (1,0) [0|0] ""  IHU

BO_ 1942 DMC_ACP_RES: 8 Vector__XXX
 SG_ DMC__ACP_RES : 7|64@0+ (1,0) [0|0] ""  IHU

BO_ 1941 DMC_DVR_RES: 8 Vector__XXX
 SG_ DMC_DVR_RES : 7|64@0+ (1,0) [0|0] ""  IHU

BO_ 1939 DMC_CWC_RES: 8 Vector__XXX
 SG_ DMC_CWC_RES : 7|64@0+ (1,0) [0|0] ""  IHU

BO_ 1935 DMC_SAUD_REQ: 8 IHU
 SG_ DMC_SAUD_REQ : 7|64@0+ (1,0) [0|0] "" Vector__XXX

BO_ 1933 DMC_NFC_REQ: 8 IHU
 SG_ DMC_NFC_REQ : 7|64@0+ (1,0) [0|0] "" Vector__XXX

BO_ 1930 DMC_AIPMR_REQ: 8 IHU
 SG_ DMC_AIPMR_REQ : 7|64@0+ (1,0) [0|0] "" Vector__XXX

BO_ 1929 DMC_AIPM_REQ: 8 IHU
 SG_ DMC_AIPM_REQ : 7|64@0+ (1,0) [0|0] "" Vector__XXX

BO_ 1927 DMC_EAMP_REQ: 8 IHU
 SG_ DMC_EAMP_REQ : 7|64@0+ (1,0) [0|0] "" Vector__XXX

BO_ 1926 DMC_ACP_REQ: 8 IHU
 SG_ DMC__ACP_REQ : 7|64@0+ (1,0) [0|0] "" Vector__XXX

BO_ 1925 DMC_DVR_REQ: 8 IHU
 SG_ DMC_DVR_REQ : 7|64@0+ (1,0) [0|0] "" Vector__XXX

BO_ 1923 DMC_CWC_REQ: 8 IHU
 SG_ DMC_CWC_REQ : 7|64@0+ (1,0) [0|0] "" Vector__XXX

BO_ 1922 DMC_SHU1D_REQ: 8 IHU
 SG_ DMC_SHU1D_REQ : 7|64@0+ (1,0) [0|0] "" Vector__XXX

BO_ 1920 DMC_SCU_REQ: 8 IHU
 SG_ DMC_SCU_REQ : 7|64@0+ (1,0) [0|0] "" Vector__XXX

BO_ 1903 DMC_RHM_REQ: 8 IHU
 SG_ DMC_RHM_REQ : 7|64@0+ (1,0) [0|0] "" Vector__XXX

BO_ 1902 DMC_LHM_REQ: 8 IHU
 SG_ DMC_LHM_REQ : 7|64@0+ (1,0) [0|0] "" Vector__XXX

BO_ 1901 DMC_ESCL_REQ: 8 IHU
 SG_ DMC_ESCL_REQ : 7|64@0+ (1,0) [0|0] "" Vector__XXX

BO_ 1900 DMC_PLG_REQ: 8 IHU
 SG_ DMC_PLG_REQ : 7|64@0+ (1,0) [0|0] "" Vector__XXX

BO_ 1894 DMC_AVM_REQ: 8 IHU
 SG_ DMC_AVM_REQ : 7|64@0+ (1,0) [0|0] "" Vector__XXX

BO_ 1891 DMC_RADAR_REQ: 8 IHU
 SG_ DMC_RADAR_REQ : 7|64@0+ (1,0) [0|0] "" Vector__XXX

BO_ 1890 DMC_CGW_REQ: 8 IHU
 SG_ DMC_CGW_REQ : 7|64@0+ (1,0) [0|0] "" Vector__XXX

BO_ 1888 DMC_BDM_REQ: 8 IHU
 SG_ DMC_BDM_REQ : 7|64@0+ (1,0) [0|0] "" Vector__XXX

BO_ 1869 DMC_IMMO_REQ: 8 IHU
 SG_ DMC_IMMO_REQ : 7|64@0+ (1,0) [0|0] "" Vector__XXX

BO_ 1867 DMC_CLM_REQ: 8 IHU
 SG_ DMC_CLM_REQ : 7|64@0+ (1,0) [0|0] "" Vector__XXX

BO_ 1864 DMC_DBL_REQ: 8 IHU
 SG_ DMC_DBL_REQ : 7|64@0+ (1,0) [0|0] "" Vector__XXX

BO_ 1863 DMC_ICM_REQ: 8 IHU
 SG_ DMC_ICM_REQ : 7|64@0+ (1,0) [0|0] "" Vector__XXX

BO_ 1862 DMC_ACU_REQ: 8 IHU
 SG_ DMC_ACU_REQ : 7|64@0+ (1,0) [0|0] "" Vector__XXX

BO_ 1839 DMC_FRM_REQ: 8 IHU
 SG_ DMC_FRM_REQ : 7|64@0+ (1,0) [0|0] "" Vector__XXX

BO_ 1838 DMC_FCM_REQ: 8 IHU
 SG_ DMC_FCM_REQ : 7|64@0+ (1,0) [0|0] "" Vector__XXX

BO_ 1835 DMC_EGS_REQ: 8 IHU
 SG_ DMC_EGS_REQ : 7|64@0+ (1,0) [0|0] "" Vector__XXX

BO_ 1832 DMC_TPMS_REQ: 8 IHU
 SG_ DMC_TPMS_REQ : 7|64@0+ (1,0) [0|0] "" Vector__XXX

BO_ 1828 DMC_EPS_REQ: 8 IHU
 SG_ DMC_EPS_REQ : 7|64@0+ (1,0) [0|0] "" Vector__XXX

BO_ 1824 DMC_ESP_REQ: 8 IHU
 SG_ DMC_ESP_REQ : 7|64@0+ (1,0) [0|0] "" Vector__XXX

BO_ 1807 DMC_GSI_REQ: 8 IHU
 SG_ DMC_GSI_REQ : 7|64@0+ (1,0) [0|0] "" Vector__XXX

BO_ 1795 DMC_TCU_REQ: 8 IHU
 SG_ DMC_TCU_REQ : 7|64@0+ (1,0) [0|0] "" Vector__XXX

BO_ 1794 DMC_AWD_REQ: 8 IHU
 SG_ DMC_AWD_REQ : 7|64@0+ (1,0) [0|0] "" Vector__XXX

BO_ 1793 DMC_FPC_REQ: 8 IHU
 SG_ DMC_FPC_REQ : 7|64@0+ (1,0) [0|0] "" Vector__XXX

BO_ 1792 DMC_EMS_REQ: 8 IHU
 SG_ DMC_EMS_REQ : 7|64@0+ (1,0) [0|0] "" Vector__XXX

BO_ 1989 DMC_CVBOX_REQ: 8 IHU
 SG_ DMC_CVBOX_REQ : 7|64@0+ (1,0) [0|0] "" Vector__XXX

BO_ 1932 DMC_HUD_REQ: 8 IHU
 SG_ DMC_HUD_REQ : 7|64@0+ (1,0) [0|0] "" Vector__XXX

BO_ 1858 DMC_DCM_REQ: 8 IHU
 SG_ DMC_DCM_REQ : 7|64@0+ (1,0) [0|0] "" Vector__XXX

BO_ 1827 DMC_PPMI_REQ: 8 IHU
 SG_ DMC_PPMI_REQ : 7|64@0+ (1,0) [0|0] "" Vector__XXX

BO_ 1889 DMC_SAM_REQ: 8 IHU
 SG_ DMC_SAM_REQ : 7|64@0+ (1,0) [0|0] "" Vector__XXX

BO_ 2020 DMC_MCUR_REQ: 8 IHU
 SG_ DMC_MCUR_REQ : 7|64@0+ (1,0) [0|0] "" Vector__XXX

BO_ 2022 DMC_DCDC_REQ: 8 IHU
 SG_ DMC_DCDC_REQ : 7|64@0+ (1,0) [0|0] "" Vector__XXX

BO_ 2021 DMC_BMS_REQ: 8 IHU
 SG_ DMC_BMS_REQ : 7|64@0+ (1,0) [0|0] "" Vector__XXX

BO_ 2018 DMC_HCU_REQ: 8 IHU
 SG_ DMC_HCU_REQ : 7|64@0+ (1,0) [0|0] "" Vector__XXX

BO_ 1831 DMC_ASU_REQ: 8 IHU
 SG_ DMC_ASU_REQ : 7|64@0+ (1,0) [0|0] "" Vector__XXX

BO_ 1988 DMC_RRCR_REQ: 8 IHU
 SG_ DMC_RRCR_REQ : 7|64@0+ (1,0) [0|0] "" Vector__XXX

BO_ 1987 DMC_RLCR_REQ: 8 IHU
 SG_ DMC_RLCR_REQ : 7|64@0+ (1,0) [0|0] "" Vector__XXX

BO_ 1986 DMC_FRCR_REQ: 8 IHU
 SG_ DMC_FRCR_REQ : 7|64@0+ (1,0) [0|0] "" Vector__XXX

BO_ 1985 DMC_FLCR_REQ: 8 IHU
 SG_ DMC_FLCR_REQ : 7|64@0+ (1,0) [0|0] "" Vector__XXX

BO_ 1984 DMC_IDCU_REQ: 8 IHU
 SG_ DMC_IDCU_REQ : 7|64@0+ (1,0) [0|0] "" Vector__XXX

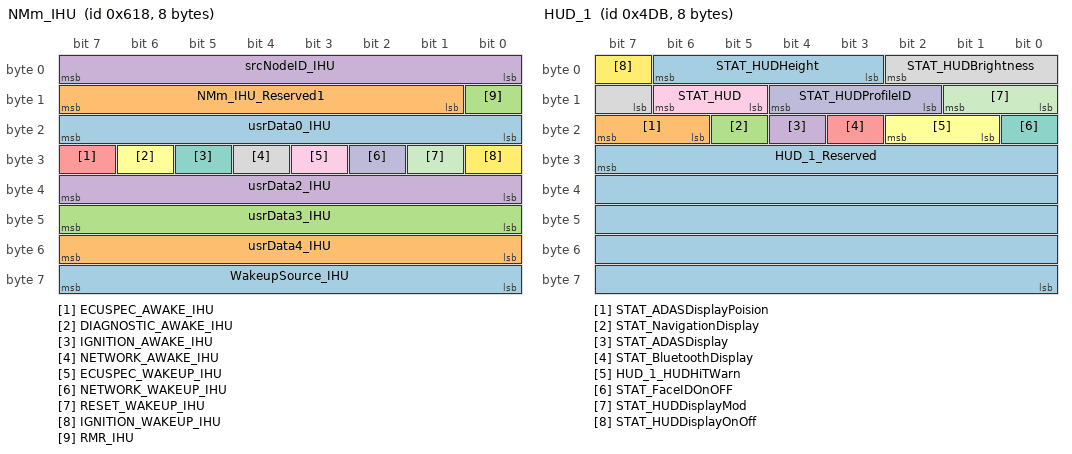
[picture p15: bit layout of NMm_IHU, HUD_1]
BO_ 1560 NMm_IHU: 8 IHU
 SG_ WakeupSource_IHU : 63|8@0+ (1,0) [0|255] "" Vector__XXX
 SG_ usrData4_IHU : 55|8@0+ (1,0) [0|255] "" Vector__XXX
 SG_ usrData3_IHU : 47|8@0+ (1,0) [0|255] "" Vector__XXX
 SG_ usrData2_IHU : 39|8@0+ (1,0) [0|255] "" Vector__XXX
 SG_ ECUSPEC_AWAKE_IHU : 31|1@0+ (1,0) [0|1] "" Vector__XXX
 SG_ DIAGNOSTIC_AWAKE_IHU : 30|1@0+ (1,0) [0|1] "" Vector__XXX
 SG_ IGNITION_AWAKE_IHU : 29|1@0+ (1,0) [0|1] "" Vector__XXX
 SG_ NETWORK_AWAKE_IHU : 28|1@0+ (1,0) [0|1] "" Vector__XXX
 SG_ ECUSPEC_WAKEUP_IHU : 27|1@0+ (1,0) [0|1] "" Vector__XXX
 SG_ NETWORK_WAKEUP_IHU : 26|1@0+ (1,0) [0|1] "" Vector__XXX
 SG_ RESET_WAKEUP_IHU : 25|1@0+ (1,0) [0|1] "" Vector__XXX
 SG_ IGNITION_WAKEUP_IHU : 24|1@0+ (1,0) [0|1] "" Vector__XXX
 SG_ usrData0_IHU : 23|8@0+ (1,0) [0|255] "" Vector__XXX
 SG_ NMm_IHU_Reserved1 : 15|7@0+ (1,0) [0|127] "" Vector__XXX
 SG_ RMR_IHU : 8|1@0+ (1,0) [0|1] "" Vector__XXX
 SG_ srcNodeID_IHU : 7|8@0+ (1,0) [0|255] "" Vector__XXX

BO_ 1266 TBOX_2: 8 Vector__XXX
 SG_ TBOX_SetAVMVeiw : 34|3@0+ (1,0) [0|7] ""  IHU
 SG_ TBOX_SetAVMOnReq : 36|2@0+ (1,0) [0|3] ""  IHU

BO_ 1312 TBOX_1: 4 Vector__XXX
 SG_ TBOX_1_RemDiagSts : 23|2@0+ (1,0) [0|3] ""  IHU

BO_ 1243 HUD_1: 8 Vector__XXX
 SG_ HUD_1_Reserved : 31|40@0+ (1,0) [0|0] ""  IHU
 SG_ STAT_ADASDisplayPoision : 23|2@0+ (1,0) [0|3] ""  IHU
 SG_ STAT_NavigationDisplay : 21|1@0+ (1,0) [0|1] ""  IHU
 SG_ STAT_ADASDisplay : 20|1@0+ (1,0) [0|1] ""  IHU
 SG_ STAT_BluetoothDisplay : 19|1@0+ (1,0) [0|1] ""  IHU
 SG_ HUD_1_HUDHiTWarn : 18|2@0+ (1,0) [0|3] ""  IHU
 SG_ STAT_FaceIDOnOFF : 16|1@0+ (1,0) [0|1] ""  IHU
 SG_ STAT_HUDBrightness : 2|4@0+ (1,0) [0|15] ""  IHU
 SG_ STAT_HUD : 14|2@0+ (1,0) [0|3] ""  IHU
 SG_ STAT_HUDProfileID : 12|3@0+ (1,0) [0|7] ""  IHU
 SG_ STAT_HUDDisplayMod : 9|2@0+ (1,0) [0|3] ""  IHU
 SG_ STAT_HUDDisplayOnOff : 7|1@0+ (1,0) [0|1] ""  IHU
 SG_ STAT_HUDHeight : 6|4@0+ (1,0) [0|15] ""  IHU

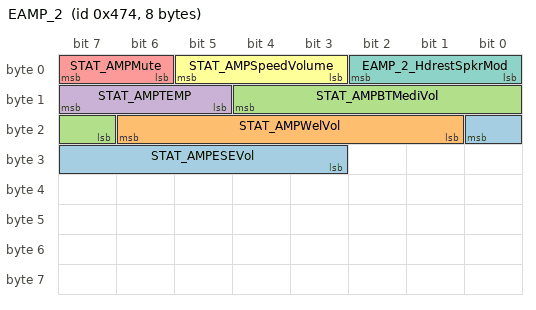
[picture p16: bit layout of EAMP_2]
BO_ 1140 EAMP_2: 8 Vector__XXX
 SG_ STAT_AMPESEVol : 16|6@0+ (1,0) [0|63] ""  IHU
 SG_ STAT_AMPWelVol : 22|6@0+ (1,0) [0|63] ""  IHU
 SG_ STAT_AMPBTMediVol : 12|6@0+ (1,0) [0|63] ""  IHU
 SG_ STAT_AMPTEMP : 15|3@0+ (1,0) [0|7] ""  IHU
 SG_ STAT_AMPMute : 7|2@0+ (1,0) [0|3] ""  IHU
 SG_ STAT_AMPSpeedVolume : 5|3@0+ (1,0) [0|7] ""  IHU
 SG_ EAMP_2_HdrestSpkrMod : 2|3@0+ (1,0) [0|7] ""  IHU

BO_ 1121 EAMP_1: 8 Vector__XXX
 SG_ STAT_AMPAlarmVolume : 63|4@0+ (1,0) [1|15] ""  IHU
 SG_ STAT_AMPLoudness : 59|2@0+ (1,0) [0|3] ""  IHU
 SG_ STAT_AMPLiveAcoustics : 57|2@0+ (1,0) [0|3] ""  IHU
 SG_ STAT_AMPSoundFieldFader : 55|4@0+ (1,0) [0|15] ""  IHU
 SG_ STAT_AMPSoundFieldBalance : 51|4@0+ (1,0) [0|15] ""  IHU
 SG_ STAT_AMPSoundEffectTreble : 47|4@0+ (1,0) [0|15] ""  IHU
 SG_ STAT_AMPSoundEffectMidrange : 43|4@0+ (1,0) [0|15] ""  IHU
 SG_ STAT_AMPSoundEffectBass : 39|4@0+ (1,0) [0|15] ""  IHU
 SG_ STAT_AMPSoundEffect : 35|4@0+ (1,0) [0|15] ""  IHU
 SG_ STAT_AMPRestoreDefaults : 31|2@0+ (1,0) [0|3] ""  IHU
 SG_ STAT_AMPDefaultVolume : 29|6@0+ (1,0) [0|63] ""  IHU
 SG_ STAT_AMPSoundFocus : 23|3@0+ (1,0) [0|15] ""  IHU
 SG_ STAT_AMPPhoneVolume : 20|5@0+ (1,0) [0|31] ""  IHU
 SG_ STAT_AMPMediaVolume : 15|6@0+ (1,0) [0|63] ""  IHU
 SG_ STAT_AMPKeyTone : 9|2@0+ (1,0) [0|3] ""  IHU
 SG_ STAT_AMPVRVolume : 7|4@0+ (1,0) [0|15] ""  IHU
 SG_ STAT_AMPNaviVolume : 3|4@0+ (1,0) [0|15] ""  IHU

BO_ 1517 HUD_IHU_Interaction: 8 Vector__XXX
 SG_ HUD_IHU_Interaction : 7|64@0+ (1,0) [0|0] ""  IHU

BO_ 1515 IHU_HUD_Interaction: 8 IHU
 SG_ IHU_HUD_Interaction : 7|64@0+ (1,0) [0|0] "" Vector__XXX

BO_ 1298 IHU_CVBOX_Interaction: 8 IHU
 SG_ IHU_CVBOX_Interaction : 7|64@0+ (1,0) [0|0] "" Vector__XXX

BO_ 1289 CVBOX_IHU_Interaction: 8 Vector__XXX
 SG_ CVBOX_IHU_Interaction : 7|64@0+ (1,0) [0|0] ""  IHU

BO_ 759 DVR_TIHU_Interaction: 8 Vector__XXX
 SG_ DVR_TIHU_Interaction : 7|64@0+ (1,0) [0|0] ""  IHU

BO_ 755 TIHU_DVR_Interaction: 8 IHU
 SG_ IHU_DVR_Interaction : 7|64@0+ (1,0) [0|0] "" Vector__XXX

BO_ 1151 TIHU_IMMO_12: 8 IHU
 SG_ TIHU_Teach_IMMO : 7|64@0+ (1,0) [0|0] "" Vector__XXX

BO_ 1116 TIHU_IMMO_11: 8 IHU
 SG_ TIHU_Auth : 7|64@0+ (1,0) [0|0] "" Vector__XXX

BO_ 1177 IHU_26: 8 IHU
 SG_ IHU_26_RRWinCmd : 62|7@0+ (1,0) [0|127] "" Vector__XXX
 SG_ IHU_26_Reserved2 : 48|2@0+ (1,0) [0|0] "" Vector__XXX
 SG_ IHU_26_WiprSnvty : 51|3@0+ (1,0) [0|7] "" Vector__XXX
 SG_ IHU_26_SeatLegSpprtPosnCmd : 55|4@0+ (1,0) [0|15] "" Vector__XXX
 SG_ IHU_26_RLWinCmd : 46|7@0+ (1,0) [0|127] "" Vector__XXX
 SG_ IHU_26_FRWinCmd : 37|7@0+ (1,0) [0|127] "" Vector__XXX
 SG_ IHU_26_FLWinCmd : 28|7@0+ (1,0) [0|127] "" Vector__XXX
 SG_ IHU_26_Reserved1 : 29|1@0+ (1,0) [0|0] "" Vector__XXX
 SG_ IHU_26_CenterLockSwt : 31|2@0+ (1,0) [0|3] "" Vector__XXX
 SG_ IHU_26_SeatLvlPosnCmd : 23|4@0+ (1,0) [0|15] "" Vector__XXX
 SG_ IHU_26_SeatHdrestHeiAdjmtCmd : 19|4@0+ (1,0) [0|15] "" Vector__XXX
 SG_ IHU_26_WinInhbSwt : 15|1@0+ (1,0) [0|1] "" Vector__XXX
 SG_ IHU_26_ReWinDefrstSwt : 14|1@0+ (1,0) [0|1] "" Vector__XXX
 SG_ IHU_26_SteerWhlHeatgSwt : 13|1@0+ (1,0) [0|1] "" Vector__XXX
 SG_ IHU_26_BackrAgPosnCmd : 12|5@0+ (1,0) [0|31] "" Vector__XXX
 SG_ IHU_26_SeatCushPosnCmd : 7|4@0+ (1,0) [0|15] "" Vector__XXX
 SG_ IHU_26_SeatHeiPosnCmd : 3|4@0+ (1,0) [0|15] "" Vector__XXX

CM_ BO_ 928 "Source network message is \"Cyclic, 20ms\".
If no messages are received on source network, no messages are sent on the destination network.";
CM_ SG_ 928 YAS_2_Checksum "0x01 XOR 0x28 XOR Byte0 XOR Byte1 XOR Byte2 XOR Byte3 XOR Byte4 XOR Byte5 XOR Byte6";
CM_ SG_ 928 LongitudinalAcceleration "???????????
??????????!mao!0.0027680342857143 g";
CM_ SG_ 928 LongitudinalAccelerationSigValid "If hasn??t been calibrated, after initialization, this signal ??s value is always10(invalid)";
CM_ BO_ 926 "Source network message is \"Cyclic, 20ms\".
If no messages are received on source network, no messages are sent on the destination network.";
CM_ SG_ 926 YAS_1_Checksum "0x01 XOR 0x27 XOR Byte0 XOR Byte1 XOR Byte2 XOR Byte3 XOR Byte4 XOR Byte5 XOR Byte6";
CM_ SG_ 926 YawRate "???????????                ??????????：0.122189236 deg/s";
CM_ SG_ 926 YawrateSigValidData "Signal state for yawrate";
CM_ BO_ 1206 "Source network message is \"Cyclic, 100ms\".
If no messages are received on source network, no messages are sent on the destination network.";
CM_ SG_ 1206 SHU2R_RSeatVentnSts "Seat Ventilation Status
????????????????";
CM_ SG_ 1206 SHU2R_RSeatHeatSts "Seat Heat Status
??????????μ?????";
CM_ BO_ 1202 "Source network message is \"Cyclic, 100ms\".
If no messages are received on source network, no messages are sent on the destination network.";
CM_ SG_ 1202 SHU2M_MSeatVentnSts "Seat Ventilation Status
?????м??????????";
CM_ SG_ 1202 SHU2M_MSeatHeatSts "Seat Heat Status
?????м????μ?????";
CM_ BO_ 1194 "Source network message is \"Cyclic, 100ms\".
If no messages are received on source network, no messages are sent on the destination network.";
CM_ SG_ 1194 SHU2L_LSeatVentnSts "Seat Ventilation Status
????????????????";
CM_ SG_ 1194 SHU2L_LSeatHeatSts "Seat Heat Status
??????????μ?????";
CM_ BO_ 1190 "Source network message is \"Cyclic, 100ms\".
If no messages are received on source network, no messages are sent on the destination network.";
CM_ SG_ 1190 SHU1R_RSeatAutVentnSts "Passenger Seat Automatic Ventilation Status";
CM_ SG_ 1190 SHU1R_RSeatAutHeatSts "Passenger Seat Automatic Heat Status";
CM_ SG_ 1190 SHU1R_RSeatVentnSts "Passenger Seat Ventilation Status
???????????????";
CM_ SG_ 1190 SHU1R_RSeatHeatSts "Passenger Seat Heat Status
?????????μ?????";
CM_ BO_ 1186 "Source network message is \"Cyclic, 100ms\".
If no messages are received on source network, no messages are sent on the destination network.";
CM_ SG_ 1186 SHU1L_LSeatAutVentnSts "Driver Seat Automatic Ventilation Status";
CM_ SG_ 1186 SHU1L_LSeatAutHeatSts "Driver Seat Automatic Heat Status";
CM_ SG_ 1186 SHU1L_LSeatVentnSts "Driver Seat Ventilation Status
????????????????";
CM_ SG_ 1186 SHU1L_LSeatHeatSts "Driver Seat Heat Status
??????????μ?????";
CM_ SG_ 1170 SCU_2_CRC "CRC (SAE J1850 CRC-8)
Note: Details Please refer to specification??Standard Specification for CAN Data Link Layer_v1.1??section 2.3.2";
CM_ SG_ 1170 SCU_2_MessageCounter "Rolling message counter(the maximum value of Alive counter is 15)
Note: Details Please refer to specification??Standard Specification for CAN Data Link Layer_v1.1??section 2.3.1";
CM_ SG_ 1170 SCU_2_SeatLegSpprtPosnStsTar "Seat leg support position status";
CM_ SG_ 1170 SCU_2_SeatLvlPosnStsTar "Seat level position status";
CM_ SG_ 1170 SCU_2_SeatHdrestHeiAdjmt "Seat headrest height adjustment";
CM_ SG_ 1170 SCU_2_BackrAgPosnStsTar "Seat back angle position status";
CM_ SG_ 1170 SCU_2_SeatCushPosnSts "Seat cushion position status";
CM_ SG_ 1170 SCU_2_SeatHeiPosnStsTar "Seat height position status";
CM_ BO_ 1090 "Source network message is \"Cyclic, 100ms\".
If no messages are received on source network, no messages are sent on the destination network.";
CM_ SG_ 1090 PsngrSeatVentilationFeedbackSts "0x3: Seat Ventilation Level3 is only for EEA4.0 project
?????????????";
CM_ SG_ 1090 DriverSeatVentilationFeedbackSts "0x3: Seat Ventilation Level3 is only for EEA4.0 project
?????????????";
CM_ SG_ 1090 Seat_ExtMirror_PositionInfo "???η?????DVD??????λ????????";
CM_ SG_ 1090 SCURelateKeyOrFaceIDFeedbackSts "???μ??书???????????ID?????????????
??????????????!mao!?????????μ??书????????????????????
????????????????!mao!?????????μ??书???????????ID????????";
CM_ SG_ 1090 Seat_ExtMirror_MemorySts "????/????????????
0x0!mao!??д???????/??????λ?ü??书???!dou!??????0x0
0x1!mao!??????
0x2!mao!???????
???????!dou!???????????0x1!mao!success!dou!???0x0!mao!Not active";
CM_ SG_ 1090 PsngrSeatHeatFeedbackSts "0x3: Seat heating Level3 is only for EEA4.0 project
???????μ?????";
CM_ SG_ 1090 DriverSeatHeatFeedbackSts "0x3: Seat heating Level3 is only for EEA4.0 project
???????μ?????";
CM_ SG_ 1090 ReverseExtMirrorFeedbackSts "???????????·???????";
CM_ SG_ 1090 EasyEntryFeedbackSts "EasyEntry??????";
CM_ SG_ 1090 Seat_ExtMirror_MemoryReq "???μ???/??????????????
Note:???????????????????λ???????!dou!???????????3s????в??????????,???????????????????????!dou!????????????0x1!mao!Reuqest!dou!???0x0!mao!Not Request";
CM_ SG_ 1090 Seat_ExtMirror_MemoryEnable "???μ???/????????????????????
Note!mao!??????????????!dou!????????0x1??";
CM_ BO_ 924 "Source network message is \"Cyclic, 10ms\".
If no messages are received on source network, no messages are sent on the destination network.";
CM_ SG_ 924 SAM_1_GCRCCheck "CRC (SAE J1850 CRC-8)
Note: Details Please refer to specification??Standard Specification for CAN Data Link Layer_v1.1??section 2.3.2";
CM_ SG_ 924 SAM_1_G_MessageCounter "Rolling message counter(the maximum value of Alive counter is 15)
Note: Details Please refer to specification??Standard Specification for CAN Data Link Layer_v1.1??section 2.3.1";
CM_ SG_ 924 AngleFailure "????????????????SAS????????????
SASδ????б?????????????Χ???1-failure";
CM_ SG_ 924 SteeringAngle "The actual range is from -720 deg to +720 deg.";
CM_ BO_ 498 "Source network message is \"Cyclic, 10ms\".
If no messages are received on source network, no messages are sent on the destination network.";
CM_ SG_ 498 RLCR_2_RCTBONOFFSts "RCTB Switch status";
CM_ SG_ 498 RLCR_2_RAEBONOFFSts "RAEB Switch status";
CM_ BO_ 1141 "Source network message is \"Cyclic, 100ms\".
If no messages are received on source network, no messages are sent on the destination network.";
CM_ SG_ 1141 LHSFRadarSensorDistance "??????????
??????Sensor err!mao!????0x7F
???????????????!mao!????0x7E

???????!mao!????=(D)*5+30
???????!mao!????0x7E
0x5F~0x7D!mao!??Ч????";
CM_ SG_ 1141 RHSFRadarSensorDistance "??????????
??????Sensor err!mao!????0x7F
???????????????!mao!????0x7E

???????!mao!????=(D)*5+30
???????!mao!????0x7E
0x5F~0x7D!mao!??Ч????";
CM_ SG_ 1141 LHSRRadarSensorDistance "?????????
??????Sensor err!mao!????0x7F
???????????????!mao!????0x7E

???????!mao!????=(D)*5+30
???????!mao!????0x7E
0x5F~0x7D!mao!??Ч????";
CM_ SG_ 1141 RHSRRadarSensorDistance "?????????
??????Sensor err!mao!????0x7F
???????????????!mao!????0x7E

???????!mao!????=(D)*5+30
???????!mao!????0x7E
0x5F~0x7D!mao!??Ч????";
CM_ BO_ 1078 "Source network message is \"Cyclic, 100ms\".
If no messages are received on source network, no messages are sent on the destination network.";
CM_ SG_ 1078 PLG_OperateSts "β????????";
CM_ SG_ 1078 PLG_Set_MaxPosition "β????????????λ??";
CM_ BO_ 1042 "Source network message is \"Cyclic, 100ms\".
If no messages are received on source network, no messages are sent on the destination network.";
CM_ SG_ 1042 PEPS_BLTKey_PESts "????????PE??????????????";
CM_ BO_ 998 "Source network message is \"Cyclic, 50ms\".
If no messages are received on source network, no messages are sent on the destination network.";
CM_ SG_ 998 RemoteStartSts "????????";
CM_ SG_ 998 Start_StopRequest "???,???????";
CM_ SG_ 998 IDInformation "To show which ID is sending the signal.";
CM_ BO_ 1124 "Source network message is \"Cyclic, 100ms\".
If no messages are received on source network, no messages are sent on the destination network.";
CM_ SG_ 1124 NFC_1_DispCardPosn "Display card position";
CM_ BO_ 864 "Source network message is \"Cyclic, 50ms\".
If no messages are received on source network, no messages are sent on the destination network.";
CM_ BO_ 945 "Source network message is \"Cyclic, 50ms\".
If no messages are received on source network, no messages are sent on the destination network.";
CM_ SG_ 945 MFS_TJA_ICA_ON_OFF "IHU???MFS?????TJA_ICA_ON_OFF?????????????0?，?????????????????，??IHU_7?а???Not Active??????????????1????2?，??????????，IHU????????ε??????????η???switch off，??仯??η???switch on;??????";
CM_ BO_ 1149 "Source network message is \"NoMsgSendType, /\".
If no messages are received on source network, no messages are sent on the destination network.";
CM_ BO_ 1110 "Source network message is \"NoMsgSendType, /\".
If no messages are received on source network, no messages are sent on the destination network.";
CM_ BO_ 1508 "Source network message is \"NoMsgSendType, /\".
If no messages are received on source network, no messages are sent on the destination network.";
CM_ SG_ 1508 ICM_4_InteractiveDisplayInfo "Refer to ??T15 RRM and ICM Interactive Display Communication Specification??";
CM_ SG_ 1248 IDCU_11_DrvAssiStylests "Assist driver's default style selection Settings
???????????????????????!dou!IDCU??????";
CM_ SG_ 1248 IDCU_11_DCLCONOFFsts "Dial lever control lane change setting item switch state
???????????????????!dou!IDCU??????";
CM_ BO_ 1251 "Source network message is \"Cyclic, 100ms\".
If no messages are received on source network, no messages are sent on the destination network.";
CM_ SG_ 1251 FCM_FRM_5_DAIONOFFSts "DAI status";
CM_ SG_ 1251 FCM_FRM_5_SCFONOFFSts "SCF status";
CM_ SG_ 1251 FCM_FRM_5_FCWONOFFSts "FCW status";
CM_ SG_ 1251 FCM_FRM_5_FCWSnvtySts "FCW Sensitivity status";
CM_ SG_ 1251 FCM_FRM_5_AEBONOFFSts "AEB status";
CM_ BO_ 1245 "Source network message is \"Cyclic, 100ms\".
If no messages are received on source network, no messages are sent on the destination network.";
CM_ SG_ 1245 FCM_5_ELKONOFFSts "ELK status";
CM_ SG_ 1245 FCM_5_LDWLDPSnvtySts "LDW LDP Senstitivity status";
CM_ SG_ 1245 FCM_5_LDPONOFFSts "LDP status";
CM_ SG_ 1245 FCM_5_WarnModSts "Warning Mode status";
CM_ SG_ 1245 FCM_5_LDWONOFFSts "LDW status";
CM_ SG_ 1245 FCM_5_TLIONOFFSts "TLI status";
CM_ SG_ 1245 FCM_5_TSIONOFFSts "TSI status";
CM_ SG_ 1245 FCM_5_HMAONOFFSts "HMA status";
CM_ SG_ 1245 FCM_5_IESONOFFSts "IES status";
CM_ SG_ 1245 FCM_5_SLAONOFFSts "SLA ON/OFF status";
CM_ SG_ 1245 FCM_5_TJAICAExitTextInfoSts "TJAICA Exit Text Information status";
CM_ BO_ 1240 "Source network message is \"Cyclic, 100ms\".
If no messages are received on source network, no messages are sent on the destination network.";
CM_ SG_ 1240 EMS_BoostP "boost pressure";
CM_ BO_ 1057 "Source network message is \"Cyclic, 100ms\".
If no messages are received on source network, no messages are sent on the destination network.";
CM_ SG_ 1057 GasPedalPosition "Driver/Cruise control
This signal including compositive informations which are actual gas pedal position and dummy Cruise control gas pedal position";
CM_ SG_ 1277 CLM_10_SeRowDispSts "Second Row display Status";
CM_ SG_ 1277 CLM_10_RfgtLkDispSts "Refrigerant Leakage Display Status";
CM_ SG_ 1277 CLM_10_ReRowDispSts "Rear Row display  Status";
CM_ SG_ 1277 CLM_10_ReRowBlowSpdLvlSts "Rear Row Blow speed level Status";
CM_ SG_ 1277 CLM_10_ReRowWorkSts "Rear Row Work  Status";
CM_ SG_ 1277 CLM_10_RmnDispSts "Reminder Display Status";
CM_ SG_ 1277 CLM_10_AQSDispSts "AQS Display Status";
CM_ SG_ 1277 SelfTestResult2 "fault display on DVD with SelfTestActive
????????????????DVD????????!dou!DVD?????????????????SelfTestActive?????";
CM_ SG_ 1277 IntelligentCustomSts "ON:?????????????
OFF!mao!????????????";
CM_ SG_ 1277 CLM_10_SeRowWorkSts "Second Row Working status
??????????";
CM_ SG_ 1277 CLM_10_SeRowBlowSpdLvlDispSts "Second Row Blow speed level display status
??????????λ";
CM_ SG_ 1277 PtcHeatgSts "Ptc Heating Status
ON:??????????????
OFF!mao!?????????????";
CM_ BO_ 1334 "Source network message is \"Cyclic, 500ms\".
If no messages are received on source network, no messages are sent on the destination network.";
CM_ SG_ 1334 FragranCeconsistenceLevelSts "??????????????";
CM_ SG_ 1334 Pos3_FragranceTypesSts "λ??3???????????????:
Type1,Type2 ??Type3?????????????????
Unfilled ???λ??δ??κ?????";
CM_ SG_ 1334 Pos2_FragranceTypesSts "λ??2???????????????:
Type1,Type2 ??Type3?????????????????
Unfilled ???λ??δ??κ?????";
CM_ SG_ 1334 PM2_5AutoRunSetSts "?????????????????????";
CM_ SG_ 1334 PM2_5_Incar_Level "???????PM2.5???????????????????????";
CM_ SG_ 1334 PM2_5_Outcar_Level "???????PM2.5???????????????????????";
CM_ SG_ 1334 FragranceDisplaysts "???????????????";
CM_ SG_ 1334 ACModeCustomSts "????????????????";
CM_ SG_ 1334 FragranceWelcomeModeSts "???????????";
CM_ SG_ 1334 RefreshFunctionSts "?????????????????";
CM_ SG_ 1334 Pos1_FragranceTypesSts "λ??1???????????????:
Type1,Type2 ??Type3?????????????????
Unfilled ???λ??δ??κ?????";
CM_ SG_ 1334 PM2_5AutoRunSts "?????????????，????????????????????????????????
???????????????????????!dou!????????";
CM_ SG_ 1334 FragranceSWSts "????????????";
CM_ SG_ 1334 AutoBltCalllowBlowSpeedSts "???????????????????????";
CM_ SG_ 1334 AutoParkInnerCirculationSts "???????????????????";
CM_ SG_ 1334 PM2_5_IncarSts "PM2.5_IncarSts????PM2.5?????????????，??0X1????????·?????·????";
CM_ SG_ 1334 PM2_5_ExtSts "PM2.5_ExtSts????PM2.5?????????????，??0X1????????·?????·????";
CM_ SG_ 1334 PM2_5_ext "????PM2.5?";
CM_ SG_ 1334 FragranceShortageWarning "?????????????
??????bitλ???????λ???
????!mao!111!dou!??λ??1!dou!???λ??3?????????м?λ??1!dou!???λ??2??????????λ??1!dou!???λ??1??????????????1!dou!??????????!dou!??????";
CM_ SG_ 1334 ION_Function_Sts "???????????????,???????????????：
0x0 ??????????????
0x1 ?????????
0x2 ????????";
CM_ SG_ 1334 PM2_5_incar "????PM2.5?";
CM_ BO_ 1333 "Source network message is \"Cyclic, 100ms\".
If no messages are received on source network, no messages are sent on the destination network.";
CM_ SG_ 1333 AUTODefrostDisplaySts "????????????????，??????????????????(???????????????，??????????????，????????)";
CM_ SG_ 1333 TempKnobRollingCounter "?????/??????????
???!mao!????????????????16!dou!?????????????10000??

?綯????!dou!IPM????RRM???????????";
CM_ SG_ 1333 AUTODefrostForceOpenSts "???????????????????，??????????????????(?????????????，?????????????????????，????????)";
CM_ SG_ 1333 PM2_5Displaysts "?????????DVD，?????????????????????";
CM_ SG_ 1333 PM2_5overproofDisplaySts "????????δ??????????，????PM2.5????????，DVD?????????????????????????";
CM_ SG_ 1333 FiltertchangeDisplaySts "?????о????????DVD?????????????????";
CM_ SG_ 1333 REARInhibitSts "???????????????ж????????";
CM_ SG_ 1333 AUTODefrostOnSts "???????????????";
CM_ BO_ 1306 "Source network message is \"Cyclic, 100ms\".
If no messages are received on source network, no messages are sent on the destination network.";
CM_ SG_ 1306 SelfTestResult "????????????????DVD????????，DVD?????????????????SelfTestActive?????";
CM_ SG_ 1306 TemperatureUnit "???????????Startup??
??????!deg!";
CM_ SG_ 1306 SetTemperature_L_C "?????????，????????????????趨?????????????趨???????????，??????趨???????，??????趨????????
DVDδ????趨????!dou!???????趨????startup ?????1F?!dou!DVD???????????????????????";
CM_ SG_ 1306 BlowDelayOffSts "DelayOff：??????????
Not DelayOff!mao!??????????????";
CM_ SG_ 1306 BlowAdvanceOnSts "AdvanceOn：???????????
Not AdvanceOn!mao!???????????????";
CM_ SG_ 1306 DisplayActive "???????????
CLM?????????????DVD????????!dou!????active-1!dou!DVD??????????????????10????м????????????!dou!????? not active-0!dou!DVD?????????????";
CM_ SG_ 1306 SelfTestActive "???????????????????5S????，?????????????Ч???， ????????????????DVD????????5s??，??????????????Ч";
CM_ SG_ 1306 PM2_5Sts "PM2.5??????";
CM_ SG_ 1306 WorkingSts "Not active-?????
Active--?????";
CM_ SG_ 1306 FrontDeforest_MaxDisplaySts "?????????????";
CM_ SG_ 1306 ACRequestDisplaySts "AC??????
?????????????,?????EMS??AC??????????????";
CM_ SG_ 1306 Reserved_AC_MaxSts "MAX AC??????";
CM_ SG_ 1104 OBDDiagnosisReqInd "?????????
1!mao!CGW???Diag CAN????????????1(??????CAN???Diag CAN????????????????)
0!mao!CGW 10s??????Diag CAN????????????0(??????CAN???Diag CAN????????????????)
TBOX!mao!???1???????????????????????";
CM_ BO_ 1178 "Source network message is \"Cyclic, 100ms\".
If no messages are received on source network, no messages are sent on the destination network.";
CM_ SG_ 1178 BDM_26_RRWinPosn "Rear Right Window Position";
CM_ SG_ 1178 BDM_26_RLWinPosn "Rear Left Window Position";
CM_ SG_ 1178 BDM_26_FRWinPosn "Front Right Window Position";
CM_ SG_ 1178 BDM_26_FLWinPosn "Front Left Window Position";
CM_ SG_ 1007 BDM_25_AmbBrightness "?????";
CM_ SG_ 1007 BDM_25_FWBrightness "????";
CM_ BO_ 1287 "Source network message is \"Cyclic, 100ms\".
If no messages are received on source network, no messages are sent on the destination network.";
CM_ SG_ 1287 BCM_22_WiprSnvtySetFb "Wiper Sensitivity Set feedback";
CM_ SG_ 1287 PassSeatMsg_ModeSts "0x0:????
0x1:??????
0x2:è????
0x3:??????
0x4:?滺??
0x5:?????";
CM_ BO_ 746 "Source network message is \"Cyclic, 20ms\".
If no messages are received on source network, no messages are sent on the destination network.";
CM_ SG_ 746 BDM_OTAPwrOnReqFb "OTA Power On Request FeedBack";
CM_ SG_ 746 BDM_OTAPwrDwnReqFb "OTA Power Down Request FeedBack";
CM_ SG_ 746 BDM_OTAModStsFb "Mode Status FeedBack";
CM_ SG_ 746 SlaveVehMod "?????????????";
CM_ SG_ 746 VehPwrMod "?????????";
CM_ SG_ 901 CTP_VolStepValForDVD "Volume Step Value For DVD of Roller";
CM_ SG_ 901 CTP_VolPlusMinusForDVDSts "Volume Plus Minus For DVD Status of Roller";
CM_ SG_ 901 CTP_HomeKeyForIHUSts "DVD???????";
CM_ SG_ 901 CTP_PowerKeyForIHUSts "DVD???????
??e??????????д????e????!dou!??????0x0";
CM_ SG_ 901 CTP_TrackMod "track mode
???????!dou!??3?? Active!dou!????? Not Active";
CM_ SG_ 901 CTP_NavKeyForIHUSts "CTP_NavigationKeyForIHUSts
???????!dou!??3?? Active!dou!????? Not Active
????????!dou!???????????";
CM_ BO_ 936 "Source network message is \"Cyclic, 100ms\".
If no messages are received on source network, no messages are sent on the destination network.";
CM_ SG_ 936 IBS_SOH "The maximum possible amount of a fully charged battery (aged), relative to the nominal battery capacity; 101-254 reserved.Invalid Raw Value:255.";
CM_ SG_ 936 IBS_SOC "Battery state of charge calculated from IBS; 101-254 reserved;Invalid Raw Value:255.";
CM_ BO_ 934 "Source network message is \"Cyclic, 100ms\".
If no messages are received on source network, no messages are sent on the destination network.";
CM_ SG_ 934 IBS_Current "Current measured battery current.
Initial value:
65535/1024-32,
65535/128-256,
65535/16-2048.
Factor:
1/1024,
1/128,
1/16.
Offset:
-32,
-256,
-2048.
Minimum:
-1,
-200,
-1500.
Maximum:
1,
200,
1500.";
CM_ SG_ 934 IBS_Voltage "Current measured battery voltage, max value is 18V.Invalid Raw Value:16383.";
CM_ BO_ 1063 "Source network message is \"Cyclic, 100ms\".
If no messages are received on source network, no messages are sent on the destination network.";
CM_ SG_ 1063 TheaterDimmingColorFeedback_64 "64???Χ???????????";
CM_ SG_ 1063 HUDBriUnit "HUD brightness unit.
In case brightness <= 120lux, the HUDBrightnessUnit=0x0 ; in case the brightness > 120lux andbrightness<= 1200lux, the HUDBrightnessUnit=0x1; 
in case thbrightness > 1200lux and brightness<= 12000lux, theHUDBrightnessUnit=0x2;
otherwise the HUDBrightnessUnit=0x3.";
CM_ SG_ 1063 HUDBriRawVal "HUDBrightnessRawValue
HUD brightness automatic adjustment raw value for HUD.
0x7F:Invalid. HUDbrightness=HUDBrightnessRawValue*HUDBrightnessUnit";
CM_ BO_ 1520 "Source network message is \"NoMsgSendType, /\".???????????????
If no messages are received on source network, no messages are sent on the destination network.";
CM_ SG_ 1520 SN "1、Message ID????.??BCM?????д??????????，BCM??100ms?????????????BCM_10，Message ID??????1??10??????????Message ID?????2?，ESP????????е?ESP?????????
Note!mao!?????????ο????????ESP??????ù淶??Chery XX Project ESP Diagnostic Parameter Configuration Specification??
2!dun!SequenceNumber????.??BCM?????д??????????!dou!BCM??100ms?????????????BCM_10!dou!SequenceNumber??????1??10??????????SequenceNumber?????3?!dou!DVR????????е?DVR?????????
Note!mao!?????????ο????????DVR??????ù淶??Chery XX Project DVR Diagnostic Parameter Configuration Specification??
3!dun!SequenceNumber????.??BCM?????д??????????!dou!BCM??100ms?????????????BCM_10!dou!SequenceNumber??????1??10????????
Note!mao!?????????ο????????ABM??????ù淶??Chery XX Project ABM Diagnostic Parameter Configuration Specification??";
CM_ BO_ 1077 "Source network message is \"Cyclic, 100ms\".
If no messages are received on source network, no messages are sent on the destination network.";
CM_ SG_ 1077 RvsExtMirrFbSts "?????????????·???????";
CM_ SG_ 1077 SRF_Hall2SensorError "HALL2??????????";
CM_ SG_ 1077 SRF_Hall1SensorError "HALL1??????????";
CM_ SG_ 1077 SRF_SunroofOverVolt "?????????";
CM_ SG_ 1077 SRF_SunroofUnderVolt "???????????";
CM_ SG_ 1077 SRF_LINCommunicationERROR "LIN??????";
CM_ SG_ 1077 SRF_SwitchError "??????";
CM_ SG_ 1077 SRF_OverHeatProtect "?????????????";
CM_ SG_ 1077 SRF_MotorRelayError "????????????";
CM_ SG_ 1077 AssociatedWithDriverModeFeedback "Associated With Driver Mode Feedback";
CM_ SG_ 1077 TheaterDimmingBrightnessFeedback "Theater Dimming Brightness Feedback";
CM_ SG_ 1077 TheaterDimmingColorFeedback "Theater Dimming Color Feedback";
CM_ SG_ 1077 SRF_Sunshade_OperateSts "???????????";
CM_ SG_ 1077 RRWindowSts "??????：
???????????????????6????!mao!comfort!dou!close ,open ,stop , closing , opening!dou!????????!dun!???!dun!???!dun!???!dun!???????к????????С?
???APP???startup???????????????????";
CM_ SG_ 1077 RLWindowSts "??????：
???????????????????6????!mao!comfort!dou!close ,open ,stop , closing , opening!dou!????????!dun!???!dun!???!dun!???!dun!???????к????????С?
???APP???startup???????????????????";
CM_ SG_ 1077 WindowInhibitSts "?????????";
CM_ SG_ 1077 FRWindow_Sts "??????：
???????????????????6????!mao!comfort!dou!close ,open ,stop , closing , opening!dou!????????!dun!???!dun!???!dun!???!dun!???????к????????С?
???APP???startup???????????????????";
CM_ SG_ 1077 FLWindow_Sts "??????：
???????????????????6????!mao!comfort!dou!close ,open ,stop , closing , opening!dou!????????!dun!???!dun!???!dun!???!dun!???????к????????С?
???APP???startup???????????????????";
CM_ SG_ 1077 Window_OperateSts "??????：
Window_OperateSts????2????!mao!active ,not active !dou!???????ж????????ж???";
CM_ SG_ 1077 Reserved_SRF_Error "?????????????????????，??0x0?????????????????????";
CM_ SG_ 1077 SRF_InitStatus "?????????λ";
CM_ SG_ 1077 AssociatedWithMusicModeFeedback "Associated With Music Mode Feedback";
CM_ SG_ 1077 TheaterDimmingStatusFeedback "Theater Dimming Status Feedback";
CM_ SG_ 1077 SRF_PositionSts "??????λ??
SRF_PostionSts???????????λ??!dou!0??????!dou!100%??????!dou!tilt?????!dou!?????????12????!mao!0!dun!10%!dun!20%......100%!dun!tilt!dou!???????????!dou!???統?????λ???????????!dou!????0-10%???!dou!??????10%!dou!???????.";
CM_ SG_ 1077 SRF_OperateSts "????
SRF_OperateSts??????7????!mao!tilt,close,opening,stop,closing,open, comfort open!mao!?????????!dun!???!dun!????!dun!???!dun!?????!dun!???!dun!???????????.";
CM_ BO_ 1505 "Source network message is \"NoMsgSendType, /\".???????????????
If no messages are received on source network, no messages are sent on the destination network.";
CM_ BO_ 913 "Source network message is \"Cyclic, 20ms\".
If no messages are received on source network, no messages are sent on the destination network.";
CM_ SG_ 913 AutoHighSpeedRequest "Auto high speed request
???????ε??????";
CM_ SG_ 913 RainDetected "Rain detected
???????????";
CM_ SG_ 913 HazardLightSW "???????????，????Σ???????????????????????，????Σ?????";
CM_ SG_ 1217 ASU_1_SetModsts "Set mode status";
CM_ SG_ 1217 ASU_1_AssocWithDrvrModFB "associate with driver mode feedback";
CM_ BO_ 554 "Source network message is \"Cyclic, 20ms\".
If no messages are received on source network, no messages are sent on the destination network.";
CM_ SG_ 554 APAFailureSts "APA????????";
CM_ SG_ 554 APA_Active "APA?????????";
CM_ SG_ 554 AVM_APA_SystemSts "APA?????????
0x0: ??????????п???APA?????!dou!??????0x0
0x1: standby??
0x2: ?????????
0x3: ??????????
0x4: ?????????????????λ???!dou!??????0x4
0x5: APA????
0x6: APA?ж?
???!mao!APA????????????
BCM???0x3!dun!0x4!dun!0x6???????";
CM_ BO_ 1267 "Source network message is \"Cyclic, 100ms\".
If no messages are received on source network, no messages are sent on the destination network.";
CM_ SG_ 1267 AIPM_2_DriveModeSet "????????λ，??3?ε???，????? Not Active";
CM_ BO_ 1265 "?????????????????????????0
Source network message is \"NoMsgSendType, /\".
If no messages are received on source network, no messages are sent on the destination network.";
CM_ SG_ 1265 PanelKeyVoiceRemindReq "0x0：No action??DVD need not to respond to this signal 
0x1!mao! Request??DVD need to make an audible prompt??
Note!mao!When the panel detects that a button that requires an audible prompt is pressed, the signal is triggered to first send a frame 0x1:Request, and then send a frame 0x0:Not active.";
CM_ BO_ 932 "Source network message is \"Cyclic, 20ms\".
If no messages are received on source network, no messages are sent on the destination network.";
CM_ SG_ 932 ABSESP_8_Checksum "((Byte0+Byte1+ Byte2+Byte3+Byte4+Byte5+Byte6) AND 0xFF) XOR 0xFF
Note: Details Please refer to specification??Standard Specification for CAN Data Link Layer_v1.1??section 2.3.3";
CM_ SG_ 932 ABSESP_8_MessageCounter "Rolling message counter(the maximum value of Alive counter is 15)
Note: Details Please refer to specification??Standard Specification for CAN Data Link Layer_v1.1??section 2.3.1";
CM_ BO_ 931 "Source network message is \"Cyclic, 20ms\".
If no messages are received on source network, no messages are sent on the destination network.";
CM_ SG_ 931 ABSESP_7_Checksum "((Byte0+Byte1+ Byte2+Byte3+Byte4+Byte5+Byte6) AND 0xFF) XOR 0xFF
Note: Details Please refer to specification??Standard Specification for CAN Data Link Layer_v1.1??section 2.3.3";
CM_ SG_ 931 ABSESP_7_MessageCounter "Rolling message counter(the maximum value of Alive counter is 15)
Note: Details Please refer to specification??Standard Specification for CAN Data Link Layer_v1.1??section 2.3.1";
CM_ BO_ 793 "Source network message is \"Cyclic, 20ms\".
If no messages are received on source network, no messages are sent on the destination network.";
CM_ BO_ 787 "Source network message is \"Cyclic, 20ms\".
If no messages are received on source network, no messages are sent on the destination network.";
CM_ SG_ 787 ABS_ESP_3_AVHSts "Auto Hold??????";
CM_ SG_ 787 ABS_ESP_3_AVHFailSts "AutoHold?????Ч??";
CM_ BO_ 1913 "Source network message is \"NoMsgSendType, /\".
If no messages are received on source network, no messages are sent on the destination network.";
CM_ BO_ 2041 "Source network message is \"NoMsgSendType, /\".
If no messages are received on source network, no messages are sent on the destination network.";
CM_ BO_ 2030 "Source network message is \"NoMsgSendType, /\".
If no messages are received on source network, no messages are sent on the destination network.";
CM_ BO_ 2029 "Source network message is \"NoMsgSendType, /\".
If no messages are received on source network, no messages are sent on the destination network.";
CM_ BO_ 2027 "Source network message is \"NoMsgSendType, /\".
If no messages are received on source network, no messages are sent on the destination network.";
CM_ BO_ 2025 "Source network message is \"NoMsgSendType, /\".
If no messages are received on source network, no messages are sent on the destination network.";
CM_ BO_ 2024 "Source network message is \"NoMsgSendType, /\".
If no messages are received on source network, no messages are sent on the destination network.";
CM_ BO_ 2014 "Source network message is \"NoMsgSendType, /\".
If no messages are received on source network, no messages are sent on the destination network.";
CM_ BO_ 2009 "Source network message is \"NoMsgSendType, /\".
If no messages are received on source network, no messages are sent on the destination network.";
CM_ BO_ 2008 "Source network message is \"NoMsgSendType, /\".
If no messages are received on source network, no messages are sent on the destination network.";
CM_ BO_ 2007 "Source network message is \"NoMsgSendType, /\".
If no messages are received on source network, no messages are sent on the destination network.";
CM_ BO_ 2006 "Source network message is \"NoMsgSendType, /\".
If no messages are received on source network, no messages are sent on the destination network.";
CM_ BO_ 1982 "Source network message is \"NoMsgSendType, /\".
If no messages are received on source network, no messages are sent on the destination network.";
CM_ BO_ 1981 "Source network message is \"NoMsgSendType, /\".
If no messages are received on source network, no messages are sent on the destination network.";
CM_ BO_ 1980 "Source network message is \"NoMsgSendType, /\".
If no messages are received on source network, no messages are sent on the destination network.";
CM_ BO_ 1979 "Source network message is \"NoMsgSendType, /\".
If no messages are received on source network, no messages are sent on the destination network.";
CM_ BO_ 1978 "Source network message is \"NoMsgSendType, /\".
If no messages are received on source network, no messages are sent on the destination network.";
CM_ BO_ 1977 "Source network message is \"NoMsgSendType, /\".
If no messages are received on source network, no messages are sent on the destination network.";
CM_ BO_ 1976 "Source network message is \"NoMsgSendType, /\".
If no messages are received on source network, no messages are sent on the destination network.";
CM_ BO_ 1975 "Source network message is \"NoMsgSendType, /\".
If no messages are received on source network, no messages are sent on the destination network.";
CM_ BO_ 1974 "Source network message is \"NoMsgSendType, /\".
If no messages are received on source network, no messages are sent on the destination network.";
CM_ BO_ 1951 "Source network message is \"NoMsgSendType, /\".
If no messages are received on source network, no messages are sent on the destination network.";
CM_ BO_ 1949 "Source network message is \"NoMsgSendType,/\".
If no messages are received on source network, no messages are sent on the destination network.";
CM_ BO_ 1946 "Source network message is \"NoMsgSendType, /\".
If no messages are received on source network, no messages are sent on the destination network.";
CM_ BO_ 1945 "Source network message is \"NoMsgSendType, /\".
If no messages are received on source network, no messages are sent on the destination network.";
CM_ BO_ 1938 "Source network message is \"NoMsgSendType, /\".
If no messages are received on source network, no messages are sent on the destination network.";
CM_ BO_ 1936 "Source network message is \"NoMsgSendType, /\".
If no messages are received on source network, no messages are sent on the destination network.";
CM_ BO_ 1919 "Source network message is \"NoMsgSendType, /\".
If no messages are received on source network, no messages are sent on the destination network.";
CM_ BO_ 1918 "Source network message is \"NoMsgSendType, /\".
If no messages are received on source network, no messages are sent on the destination network.";
CM_ BO_ 1917 "Source network message is \"NoMsgSendType, /\".
If no messages are received on source network, no messages are sent on the destination network.";
CM_ BO_ 1916 "Source network message is \"NoMsgSendType, /\".
If no messages are received on source network, no messages are sent on the destination network.";
CM_ BO_ 1910 "Source network message is \"NoMsgSendType, /\".
If no messages are received on source network, no messages are sent on the destination network.";
CM_ BO_ 1907 "Source network message is \"NoMsgSendType, /\".
If no messages are received on source network, no messages are sent on the destination network.";
CM_ BO_ 1906 "Source network message is \"NoMsgSendType, /\".
If no messages are received on source network, no messages are sent on the destination network.";
CM_ BO_ 1904 "Source network message is \"NoMsgSendType, /\".
If no messages are received on source network, no messages are sent on the destination network.";
CM_ BO_ 1885 "Source network message is \"NoMsgSendType, /\".
If no messages are received on source network, no messages are sent on the destination network.";
CM_ BO_ 1883 "Source network message is \"NoMsgSendType, /\".
If no messages are received on source network, no messages are sent on the destination network.";
CM_ BO_ 1880 "Source network message is \"NoMsgSendType, /\".
If no messages are received on source network, no messages are sent on the destination network.";
CM_ BO_ 1879 "Source network message is \"NoMsgSendType, /\".
If no messages are received on source network, no messages are sent on the destination network.";
CM_ BO_ 1878 "Source network message is \"NoMsgSendType, /\".
If no messages are received on source network, no messages are sent on the destination network.";
CM_ BO_ 1855 "Source network message is \"NoMsgSendType, /\".
If no messages are received on source network, no messages are sent on the destination network.";
CM_ BO_ 1854 "Source network message is \"NoMsgSendType, /\".
If no messages are received on source network, no messages are sent on the destination network.";
CM_ BO_ 1851 "Source network message is \"NoMsgSendType, /\".
If no messages are received on source network, no messages are sent on the destination network.";
CM_ BO_ 1848 "Source network message is \"NoMsgSendType, /\".
If no messages are received on source network, no messages are sent on the destination network.";
CM_ BO_ 1844 "Source network message is \"NoMsgSendType, /\".
If no messages are received on source network, no messages are sent on the destination network.";
CM_ BO_ 1840 "Source network message is \"NoMsgSendType, /\".
If no messages are received on source network, no messages are sent on the destination network.";
CM_ BO_ 1823 "Source network message is \"NoMsgSendType, /\".
If no messages are received on source network, no messages are sent on the destination network.";
CM_ BO_ 1811 "Source network message is \"NoMsgSendType, /\".
If no messages are received on source network, no messages are sent on the destination network.";
CM_ BO_ 1810 "Source network message is \"NoMsgSendType, /\".
If no messages are received on source network, no messages are sent on the destination network.";
CM_ BO_ 1809 "Source network message is \"NoMsgSendType, /\".
If no messages are received on source network, no messages are sent on the destination network.";
CM_ BO_ 1808 "Source network message is \"NoMsgSendType, /\".
If no messages are received on source network, no messages are sent on the destination network.";
CM_ BO_ 2005 "Source network message is \"NoMsgSendType,/\".
If no messages are received on source network, no messages are sent on the destination network.";
CM_ BO_ 1948 "Source network message is \"NoMsgSendType,/\".
If no messages are received on source network, no messages are sent on the destination network.";
CM_ BO_ 1874 "Source network message is \"NoMsgSendType,/\".
If no messages are received on source network, no messages are sent on the destination network.";
CM_ BO_ 1843 "Source network message is \"NoMsgSendType,/\".
If no messages are received on source network, no messages are sent on the destination network.";
CM_ BO_ 1905 "Source network message is \"NoMsgSendType,/\".
If no messages are received on source network, no messages are sent on the destination network.";
CM_ BO_ 2028 "Source network message is \"NoMsgSendType,/\".
If no messages are received on source network, no messages are sent on the destination network.";
CM_ BO_ 2026 "Source network message is \"NoMsgSendType,/\".
If no messages are received on source network, no messages are sent on the destination network.";
CM_ BO_ 1847 "Source network message is \"NoMsgSendType,/\".
If no messages are received on source network, no messages are sent on the destination network.";
CM_ BO_ 2004 "Source network message is \"NoMsgSendType,/\".
If no messages are received on source network, no messages are sent on the destination network.";
CM_ BO_ 2003 "Source network message is \"NoMsgSendType,/\".
If no messages are received on source network, no messages are sent on the destination network.";
CM_ BO_ 2002 "Source network message is \"NoMsgSendType,/\".
If no messages are received on source network, no messages are sent on the destination network.";
CM_ BO_ 2001 "Source network message is \"NoMsgSendType,/\".
If no messages are received on source network, no messages are sent on the destination network.";
CM_ BO_ 2000 "Source network message is \"NoMsgSendType,/\".
If no messages are received on source network, no messages are sent on the destination network.";
CM_ BO_ 1999 "Source network message is \"NoMsgSendType, /\".
If no messages are received on source network, no messages are sent on the destination network.";
CM_ SG_ 1560 WakeupSource_IHU "Wakeup Source
Note: Details Please refer to specification??IF CAN IHU Network Management Specification ??section10.2 and ??IF CAN DMC Network Management Specification ??section10.2";
CM_ SG_ 1560 ECUSPEC_AWAKE_IHU "ECU keeps the network awake for ECU-define reasons for which communication is needed";
CM_ SG_ 1560 DIAGNOSTIC_AWAKE_IHU "ECU needs communication for diagnostic purpose and keeps network awake.";
CM_ SG_ 1560 IGNITION_AWAKE_IHU "ECU can?t release communication because ignition (KL15) is turn on, or KLR is turned on";
CM_ SG_ 1560 NETWORK_AWAKE_IHU "ECU keeps the network awake due to the CAN message received from the network";
CM_ SG_ 1560 ECUSPEC_WAKEUP_IHU "ECU was in ??power off??, ??Bus Sleep??, ??Pre-pare Bus Sleep?? or ??Ready Sleep?? mode or ??awake?? and re-started by ECU specific reason (e.g. pressed Button, timer, etc.)";
CM_ SG_ 1560 NETWORK_WAKEUP_IHU "ECU was in ??Power off??, ??Bus Sleep??, ??Pre-pare Bus Sleep?? or ??Ready Sleep?? Mode and then re-started by a network communication.";
CM_ SG_ 1560 RESET_WAKEUP_IHU "If ECU was already awake, in ??Prepare Bus Sleep?? or ??Ready Sleep?? mode and re-started by an internal or an external reset.";
CM_ SG_ 1560 IGNITION_WAKEUP_IHU "ECU was ??power off?? or ??Bus sleep?? mode and started by ignition switch";
CM_ SG_ 1560 RMR_IHU "If set to 1 to force the network management of all other nodes on the bus into the re-peat message state.";
CM_ SG_ 1560 srcNodeID_IHU "The srcNodeID of IHU is 0x18";
CM_ SG_ 1266 TBOX_SetAVMVeiw "???APP??????AVM???";
CM_ SG_ 1266 TBOX_SetAVMOnReq "???APP??????AVM??????";
CM_ SG_ 1312 TBOX_1_RemDiagSts "Remote Diagnostic Status";
CM_ SG_ 1243 STAT_ADASDisplayPoision "STAT_ADASDisplayPoision";
CM_ SG_ 1243 HUD_1_HUDHiTWarn "?HUD?high?temperature?warning";
CM_ SG_ 1243 STAT_HUDBrightness "STAT_HUDBrightness";
CM_ SG_ 1243 STAT_HUD "STAT_HUD";
CM_ SG_ 1243 STAT_HUDProfileID "STAT_HUDProfileID";
CM_ SG_ 1243 STAT_HUDDisplayMod "STAT_HUDDisplayMod";
CM_ SG_ 1243 STAT_HUDDisplayOnOff "STAT_HUDDisplayOnOff";
CM_ SG_ 1243 STAT_HUDHeight "STAT_HUDHeight";
CM_ BO_ 1140 "Not Active?????????????";
CM_ SG_ 1140 STAT_AMPESEVol "Volume
????,???31??0-31??";
CM_ SG_ 1140 STAT_AMPWelVol "Welcome Volume
??????,???31??0-31??";
CM_ SG_ 1140 STAT_AMPBTMediVol "Media Volume
e????????,???31??0-31??";
CM_ SG_ 1140 STAT_AMPTEMP "Temperature status of power amplifier
?????????";
CM_ SG_ 1140 STAT_AMPMute "????????????????
????????????lin??????????DVD!dou!DVD???CAN????
????";
CM_ SG_ 1140 STAT_AMPSpeedVolume "????????
????????????!mao!???!dun!??!dun!??!dun!??.
?????????????????!dou!??y???????Entertainment???????????????????????????????????????";
CM_ SG_ 1140 EAMP_2_HdrestSpkrMod "Set the headrest speaker mode using the host softkey
???????????????????????????????
0x0!mao!??????
0x1: ??????
0x2: ??????
0x3:?????
0x4:???
0x5:???
0x6:???
0x8:???";
CM_ BO_ 1121 "Not Active?????????????";
CM_ SG_ 1121 STAT_AMPAlarmVolume "??????，?????Χ?1~10";
CM_ SG_ 1121 STAT_AMPLoudness "???：???????????????y???????Entertainment?????，??????????????????????";
CM_ SG_ 1121 STAT_AMPLiveAcoustics "?????Ч?????????
EQ:equalizer";
CM_ SG_ 1121 STAT_AMPSoundFieldFader "???????/???????????Y_axis??";
CM_ SG_ 1121 STAT_AMPSoundFieldBalance "???????/??????????：???????????????????????X_axis??
?????????Χ?-7~+7";
CM_ SG_ 1121 STAT_AMPSoundEffectTreble "??Ч?????????????????????????";
CM_ SG_ 1121 STAT_AMPSoundEffectMidrange "??Ч??????????????????????????";
CM_ SG_ 1121 STAT_AMPSoundEffectBass "??Ч?????????????????????????'-7~+7，";
CM_ SG_ 1121 STAT_AMPSoundEffect "??Ч????
????!mao!?????!dun!???!dun!????!dun!???!dun!???!dun!???!dun!????!dun!???

0x1: Customer-defined mode?????
0x2: Standard mode ?????
0x3: Popular mode ??????
0x4: Jazz mode ?????
0x5: Classic mode ?????
0x6: Rock mode ?????
0x7: Vocals mode??????
0x8: Rural model(?????)";
CM_ SG_ 1121 STAT_AMPRestoreDefaults "??????????，????：????、??Ч、?????????????";
CM_ SG_ 1121 STAT_AMPDefaultVolume "???????????
0~ 31!dou!
?????y???????Entertainment???????????????????????!dou!
? ????????????????????A?!dou!??????y?????????С??A!dou!?????????????????????????????????????????y?????????????A!dou!??????????????????????A";
CM_ SG_ 1121 STAT_AMPSoundFocus "???????
0x1!mao!Customized(???Balance/Fader)
0x2!mao!All(Passenger)
0x3!mao!Driver
0x4!mao!Front
0x5!mao!Rear
0x6!mao!Sleep(Baby Mode)
0x7!mao!VIP(Boss)";
CM_ SG_ 1121 STAT_AMPPhoneVolume "?绰????,?????Χ?0~25";
CM_ SG_ 1121 STAT_AMPMediaVolume "y????,???31??0-31??";
CM_ SG_ 1121 STAT_AMPKeyTone "?????????";
CM_ SG_ 1121 STAT_AMPVRVolume "???????????，0~10，
VR!dou!????!mao!С?????!dou!EAMP?????????????";
CM_ SG_ 1121 STAT_AMPNaviVolume "??????,0~10";
CM_ SG_ 1177 IHU_26_RRWinCmd "???????????У????、????????";
CM_ SG_ 1177 IHU_26_WiprSnvty "WiperSensitivity????????";
CM_ SG_ 1177 IHU_26_SeatLegSpprtPosnCmd "Seat leg support position command";
CM_ SG_ 1177 IHU_26_RLWinCmd "???????????У????、????????";
CM_ SG_ 1177 IHU_26_FRWinCmd "???????????У????、??????????";
CM_ SG_ 1177 IHU_26_FLWinCmd "???????????У????、??????????";
CM_ SG_ 1177 IHU_26_CenterLockSwt "CenterLock?п???????";
CM_ SG_ 1177 IHU_26_SeatLvlPosnCmd "Seat level position command";
CM_ SG_ 1177 IHU_26_SeatHdrestHeiAdjmtCmd "Seat headrest height adjustment command";
CM_ SG_ 1177 IHU_26_WinInhbSwt "Window Inhibit ???????????";
CM_ SG_ 1177 IHU_26_ReWinDefrstSwt "Rear window defrost??細????";
CM_ SG_ 1177 IHU_26_SteerWhlHeatgSwt "Steering Wheel heating?????????";
CM_ SG_ 1177 IHU_26_BackrAgPosnCmd "Seat back angle position command";
CM_ SG_ 1177 IHU_26_SeatCushPosnCmd "Seat cushion position command";
CM_ SG_ 1177 IHU_26_SeatHeiPosnCmd "Seat height position command";
BA_DEF_  "NmAsrCanMsgCycleTime" INT 1000 1000;
BA_DEF_  "NmAsrRepeatMessageTime" INT 3000 3000;
BA_DEF_  "NmAsrWaitBusSleepTime" INT 1500 1500;
BA_DEF_  "NmAsrTimeoutTime" INT 2500 2500;
BA_DEF_  "NmAsrBaseAddress" HEX 0 2047;
BA_DEF_  "NmAsrMessageCount" INT 128 128;
BA_DEF_  "NmType" STRING ;
BA_DEF_  "ILTxTimeout" INT 0 65535;
BA_DEF_  "Manufacturer" STRING ;
BA_DEF_ SG_  "GenSigTimeoutValue" INT 0 2147483647;
BA_DEF_ SG_  "GenSigStartValue" INT 0 2147483647;
BA_DEF_ SG_  "GenSigInactiveValue" INT 0 2147483647;
BA_DEF_ BO_  "TpTxIndex" INT 0 255;
BA_DEF_ BO_  "DiagUudtResponse" ENUM  "False","True";
BA_DEF_ BO_  "DiagResponse" ENUM  "No","Yes";
BA_DEF_ BO_  "DiagRequest" ENUM  "No","Yes";
BA_DEF_ BO_  "DiagState" ENUM  "No","Yes";
BA_DEF_ BO_  "NmAsrMessage" ENUM  "No","Yes";
BA_DEF_ BO_  "GenMsgFastOnStart" INT 0 65535;
BA_DEF_ BO_  "GenMsgCycleTimeFast" INT 0 65535;
BA_DEF_ BO_  "GenMsgNrOfRepetition" INT 0 65535;
BA_DEF_ BO_  "GenMsgStartDelayTime" INT 0 65535;
BA_DEF_ BO_  "GenMsgCycleTime" INT 0 65535;
BA_DEF_ BO_  "GenMsgDelayTime" INT 0 65535;
BA_DEF_ SG_  "GenSigSendType" ENUM  "Cyclic","OnWrite","OnWriteWithRepetition","OnChange","OnChangeWithRepetition","IfActive","IfActiveWithRepetition","NoSigSendType","OnChangeAndIfActive","OnChangeAndIfActiveWithRepetition";
BA_DEF_ BO_  "GenMsgSendType" ENUM  "Cyclic","NotUsed","NotUsed","NotUsed","NotUsed","NotUsed","NotUsed","IfActive","NoMsgSendType";
BA_DEF_ BO_  "GenMsgILSupport" ENUM  "No","Yes";
BA_DEF_ BU_  "NmStationAddress" HEX 0 255;
BA_DEF_ BU_  "NmAsrCanMsgReducedTime" INT 500 818;
BA_DEF_ BU_  "NmAsrCanMsgCycleOffset" INT 0 635;
BA_DEF_ BU_  "NmAsrNodeIdentifier" HEX 0 255;
BA_DEF_ BU_  "NmAsrNode" ENUM  "No","Yes";
BA_DEF_ BU_  "ILUsed" ENUM  "No","Yes";
BA_DEF_REL_ BU_SG_REL_  "GenSigTimeoutTime" INT 0 65535;
BA_DEF_DEF_  "NmAsrCanMsgCycleTime" 1000;
BA_DEF_DEF_  "NmAsrRepeatMessageTime" 3000;
BA_DEF_DEF_  "NmAsrWaitBusSleepTime" 1500;
BA_DEF_DEF_  "NmAsrTimeoutTime" 2500;
BA_DEF_DEF_  "NmAsrBaseAddress" 1536;
BA_DEF_DEF_  "NmAsrMessageCount" 128;
BA_DEF_DEF_  "NmType" "NmAsr";
BA_DEF_DEF_  "ILTxTimeout" 0;
BA_DEF_DEF_  "Manufacturer" "Vector";
BA_DEF_DEF_  "GenSigTimeoutValue" 0;
BA_DEF_DEF_  "GenSigStartValue" 0;
BA_DEF_DEF_  "GenSigInactiveValue" 0;
BA_DEF_DEF_  "TpTxIndex" 0;
BA_DEF_DEF_  "DiagUudtResponse" "False";
BA_DEF_DEF_  "DiagResponse" "No";
BA_DEF_DEF_  "DiagRequest" "No";
BA_DEF_DEF_  "DiagState" "No";
BA_DEF_DEF_  "NmAsrMessage" "No";
BA_DEF_DEF_  "GenMsgFastOnStart" 0;
BA_DEF_DEF_  "GenMsgCycleTimeFast" 0;
BA_DEF_DEF_  "GenMsgNrOfRepetition" 3;
BA_DEF_DEF_  "GenMsgStartDelayTime" 0;
BA_DEF_DEF_  "GenMsgCycleTime" 0;
BA_DEF_DEF_  "GenMsgDelayTime" 0;
BA_DEF_DEF_  "GenSigSendType" "NoSigSendType";
BA_DEF_DEF_  "GenMsgSendType" "NoMsgSendType";
BA_DEF_DEF_  "GenMsgILSupport" "No";
BA_DEF_DEF_  "NmStationAddress" 255;
BA_DEF_DEF_  "NmAsrCanMsgReducedTime" 575;
BA_DEF_DEF_  "NmAsrCanMsgCycleOffset" 0;
BA_DEF_DEF_  "NmAsrNodeIdentifier" 255;
BA_DEF_DEF_  "NmAsrNode" "No";
BA_DEF_DEF_  "ILUsed" "No";
BA_DEF_DEF_REL_ "GenSigTimeoutTime" 0;
BA_ "ILUsed" BU_ IHU 1;
BA_ "NmAsrNode" BU_ IHU 1;
BA_ "NmAsrNodeIdentifier" BU_ IHU 24;
BA_ "NmStationAddress" BU_ IHU 24;
BA_ "GenMsgNrOfRepetition" BO_ 1537 0;
BA_ "GenMsgCycleTime" BO_ 1537 1000;
BA_ "NmAsrMessage" BO_ 1537 1;
BA_ "GenMsgSendType" BO_ 1537 0;
BA_ "GenMsgCycleTime" BO_ 928 20;
BA_ "GenMsgNrOfRepetition" BO_ 928 0;
BA_ "GenMsgSendType" BO_ 928 0;
BA_ "GenMsgILSupport" BO_ 928 1;
BA_ "GenMsgCycleTime" BO_ 926 20;
BA_ "GenMsgNrOfRepetition" BO_ 926 0;
BA_ "GenMsgSendType" BO_ 926 0;
BA_ "GenMsgILSupport" BO_ 926 1;
BA_ "GenMsgCycleTime" BO_ 1206 100;
BA_ "GenMsgNrOfRepetition" BO_ 1206 0;
BA_ "GenMsgSendType" BO_ 1206 0;
BA_ "GenMsgILSupport" BO_ 1206 1;
BA_ "GenMsgCycleTime" BO_ 1202 100;
BA_ "GenMsgNrOfRepetition" BO_ 1202 0;
BA_ "GenMsgSendType" BO_ 1202 0;
BA_ "GenMsgILSupport" BO_ 1202 1;
BA_ "GenMsgCycleTime" BO_ 1194 100;
BA_ "GenMsgNrOfRepetition" BO_ 1194 0;
BA_ "GenMsgSendType" BO_ 1194 0;
BA_ "GenMsgILSupport" BO_ 1194 1;
BA_ "GenMsgCycleTime" BO_ 1190 100;
BA_ "GenMsgNrOfRepetition" BO_ 1190 0;
BA_ "GenMsgSendType" BO_ 1190 0;
BA_ "GenMsgILSupport" BO_ 1190 1;
BA_ "GenMsgCycleTime" BO_ 1186 100;
BA_ "GenMsgNrOfRepetition" BO_ 1186 0;
BA_ "GenMsgSendType" BO_ 1186 0;
BA_ "GenMsgILSupport" BO_ 1186 1;
BA_ "GenMsgCycleTime" BO_ 1170 100;
BA_ "GenMsgNrOfRepetition" BO_ 1170 0;
BA_ "GenMsgSendType" BO_ 1170 0;
BA_ "GenMsgILSupport" BO_ 1170 1;
BA_ "GenMsgCycleTime" BO_ 1090 100;
BA_ "GenMsgNrOfRepetition" BO_ 1090 0;
BA_ "GenMsgSendType" BO_ 1090 0;
BA_ "GenMsgILSupport" BO_ 1090 1;
BA_ "GenMsgCycleTime" BO_ 924 10;
BA_ "GenMsgNrOfRepetition" BO_ 924 0;
BA_ "GenMsgSendType" BO_ 924 0;
BA_ "GenMsgILSupport" BO_ 924 1;
BA_ "GenMsgCycleTime" BO_ 498 10;
BA_ "GenMsgNrOfRepetition" BO_ 498 0;
BA_ "GenMsgSendType" BO_ 498 0;
BA_ "GenMsgILSupport" BO_ 498 1;
BA_ "GenMsgCycleTime" BO_ 1141 100;
BA_ "GenMsgNrOfRepetition" BO_ 1141 0;
BA_ "GenMsgSendType" BO_ 1141 0;
BA_ "GenMsgILSupport" BO_ 1141 1;
BA_ "GenMsgCycleTime" BO_ 1078 100;
BA_ "GenMsgNrOfRepetition" BO_ 1078 0;
BA_ "GenMsgSendType" BO_ 1078 0;
BA_ "GenMsgILSupport" BO_ 1078 1;
BA_ "GenMsgCycleTime" BO_ 1042 100;
BA_ "GenMsgNrOfRepetition" BO_ 1042 0;
BA_ "GenMsgSendType" BO_ 1042 0;
BA_ "GenMsgILSupport" BO_ 1042 1;
BA_ "GenMsgCycleTime" BO_ 998 50;
BA_ "GenMsgNrOfRepetition" BO_ 998 0;
BA_ "GenMsgSendType" BO_ 998 0;
BA_ "GenMsgILSupport" BO_ 998 1;
BA_ "GenMsgCycleTime" BO_ 1124 100;
BA_ "GenMsgNrOfRepetition" BO_ 1124 0;
BA_ "GenMsgSendType" BO_ 1124 0;
BA_ "GenMsgILSupport" BO_ 1124 1;
BA_ "GenMsgDelayTime" BO_ 864 5;
BA_ "GenMsgNrOfRepetition" BO_ 864 0;
BA_ "GenMsgILSupport" BO_ 864 1;
BA_ "GenMsgDelayTime" BO_ 945 5;
BA_ "GenMsgNrOfRepetition" BO_ 945 0;
BA_ "GenMsgILSupport" BO_ 945 1;
BA_ "GenMsgNrOfRepetition" BO_ 1149 0;
BA_ "GenMsgILSupport" BO_ 1149 1;
BA_ "GenMsgNrOfRepetition" BO_ 1110 0;
BA_ "GenMsgILSupport" BO_ 1110 1;
BA_ "GenMsgNrOfRepetition" BO_ 1508 0;
BA_ "GenMsgILSupport" BO_ 1508 1;
BA_ "GenMsgCycleTime" BO_ 1248 100;
BA_ "GenMsgNrOfRepetition" BO_ 1248 0;
BA_ "GenMsgSendType" BO_ 1248 0;
BA_ "GenMsgILSupport" BO_ 1248 1;
BA_ "GenMsgCycleTime" BO_ 1251 100;
BA_ "GenMsgNrOfRepetition" BO_ 1251 0;
BA_ "GenMsgSendType" BO_ 1251 0;
BA_ "GenMsgILSupport" BO_ 1251 1;
BA_ "GenMsgCycleTime" BO_ 1245 100;
BA_ "GenMsgNrOfRepetition" BO_ 1245 0;
BA_ "GenMsgSendType" BO_ 1245 0;
BA_ "GenMsgILSupport" BO_ 1245 1;
BA_ "GenMsgCycleTime" BO_ 1240 100;
BA_ "GenMsgNrOfRepetition" BO_ 1240 0;
BA_ "GenMsgSendType" BO_ 1240 0;
BA_ "GenMsgILSupport" BO_ 1240 1;
BA_ "GenMsgCycleTime" BO_ 1057 100;
BA_ "GenMsgNrOfRepetition" BO_ 1057 0;
BA_ "GenMsgSendType" BO_ 1057 0;
BA_ "GenMsgILSupport" BO_ 1057 1;
BA_ "GenMsgCycleTime" BO_ 1277 100;
BA_ "GenMsgDelayTime" BO_ 1277 5;
BA_ "GenMsgNrOfRepetition" BO_ 1277 0;
BA_ "GenMsgSendType" BO_ 1277 0;
BA_ "GenMsgILSupport" BO_ 1277 1;
BA_ "GenMsgCycleTime" BO_ 1334 500;
BA_ "GenMsgNrOfRepetition" BO_ 1334 0;
BA_ "GenMsgSendType" BO_ 1334 0;
BA_ "GenMsgILSupport" BO_ 1334 1;
BA_ "GenMsgCycleTime" BO_ 1333 100;
BA_ "GenMsgNrOfRepetition" BO_ 1333 0;
BA_ "GenMsgSendType" BO_ 1333 0;
BA_ "GenMsgILSupport" BO_ 1333 1;
BA_ "GenMsgCycleTime" BO_ 1306 100;
BA_ "GenMsgDelayTime" BO_ 1306 5;
BA_ "GenMsgNrOfRepetition" BO_ 1306 0;
BA_ "GenMsgSendType" BO_ 1306 0;
BA_ "GenMsgILSupport" BO_ 1306 1;
BA_ "GenMsgCycleTime" BO_ 1104 100;
BA_ "GenMsgNrOfRepetition" BO_ 1104 0;
BA_ "GenMsgSendType" BO_ 1104 0;
BA_ "GenMsgILSupport" BO_ 1104 1;
BA_ "GenMsgCycleTime" BO_ 1178 100;
BA_ "GenMsgNrOfRepetition" BO_ 1178 0;
BA_ "GenMsgSendType" BO_ 1178 0;
BA_ "GenMsgILSupport" BO_ 1178 1;
BA_ "GenMsgCycleTime" BO_ 1007 100;
BA_ "GenMsgNrOfRepetition" BO_ 1007 0;
BA_ "GenMsgSendType" BO_ 1007 0;
BA_ "GenMsgILSupport" BO_ 1007 1;
BA_ "GenMsgCycleTime" BO_ 1287 100;
BA_ "GenMsgNrOfRepetition" BO_ 1287 0;
BA_ "GenMsgSendType" BO_ 1287 0;
BA_ "GenMsgILSupport" BO_ 1287 1;
BA_ "GenMsgCycleTime" BO_ 746 20;
BA_ "GenMsgNrOfRepetition" BO_ 746 0;
BA_ "GenMsgSendType" BO_ 746 0;
BA_ "GenMsgILSupport" BO_ 746 1;
BA_ "GenMsgCycleTime" BO_ 901 50;
BA_ "GenMsgNrOfRepetition" BO_ 901 0;
BA_ "GenMsgSendType" BO_ 901 0;
BA_ "GenMsgILSupport" BO_ 901 1;
BA_ "GenMsgCycleTime" BO_ 936 100;
BA_ "GenMsgNrOfRepetition" BO_ 936 0;
BA_ "GenMsgSendType" BO_ 936 0;
BA_ "GenMsgILSupport" BO_ 936 1;
BA_ "GenMsgCycleTime" BO_ 934 100;
BA_ "GenMsgNrOfRepetition" BO_ 934 0;
BA_ "GenMsgSendType" BO_ 934 0;
BA_ "GenMsgILSupport" BO_ 934 1;
BA_ "GenMsgCycleTime" BO_ 1063 100;
BA_ "GenMsgNrOfRepetition" BO_ 1063 0;
BA_ "GenMsgSendType" BO_ 1063 0;
BA_ "GenMsgILSupport" BO_ 1063 1;
BA_ "GenMsgCycleTime" BO_ 1520 100;
BA_ "GenMsgCycleTimeFast" BO_ 1520 100;
BA_ "GenMsgNrOfRepetition" BO_ 1520 0;
BA_ "GenMsgILSupport" BO_ 1520 1;
BA_ "GenMsgCycleTime" BO_ 1077 100;
BA_ "GenMsgNrOfRepetition" BO_ 1077 0;
BA_ "GenMsgSendType" BO_ 1077 0;
BA_ "GenMsgILSupport" BO_ 1077 1;
BA_ "GenMsgCycleTime" BO_ 1505 100;
BA_ "GenMsgCycleTimeFast" BO_ 1505 1000;
BA_ "GenMsgNrOfRepetition" BO_ 1505 0;
BA_ "GenMsgILSupport" BO_ 1505 1;
BA_ "GenMsgCycleTime" BO_ 913 20;
BA_ "GenMsgNrOfRepetition" BO_ 913 0;
BA_ "GenMsgSendType" BO_ 913 0;
BA_ "GenMsgILSupport" BO_ 913 1;
BA_ "GenMsgCycleTime" BO_ 1217 100;
BA_ "GenMsgNrOfRepetition" BO_ 1217 0;
BA_ "GenMsgSendType" BO_ 1217 0;
BA_ "GenMsgILSupport" BO_ 1217 1;
BA_ "GenMsgCycleTime" BO_ 554 20;
BA_ "GenMsgNrOfRepetition" BO_ 554 0;
BA_ "GenMsgSendType" BO_ 554 0;
BA_ "GenMsgILSupport" BO_ 554 1;
BA_ "GenMsgCycleTime" BO_ 1267 100;
BA_ "GenMsgNrOfRepetition" BO_ 1267 0;
BA_ "GenMsgSendType" BO_ 1267 0;
BA_ "GenMsgILSupport" BO_ 1267 1;
BA_ "GenMsgDelayTime" BO_ 1265 5;
BA_ "GenMsgNrOfRepetition" BO_ 1265 0;
BA_ "GenMsgILSupport" BO_ 1265 1;
BA_ "GenMsgCycleTime" BO_ 932 20;
BA_ "GenMsgNrOfRepetition" BO_ 932 0;
BA_ "GenMsgSendType" BO_ 932 0;
BA_ "GenMsgILSupport" BO_ 932 1;
BA_ "GenMsgCycleTime" BO_ 931 20;
BA_ "GenMsgNrOfRepetition" BO_ 931 0;
BA_ "GenMsgSendType" BO_ 931 0;
BA_ "GenMsgILSupport" BO_ 931 1;
BA_ "GenMsgCycleTime" BO_ 793 20;
BA_ "GenMsgNrOfRepetition" BO_ 793 0;
BA_ "GenMsgSendType" BO_ 793 0;
BA_ "GenMsgILSupport" BO_ 793 1;
BA_ "GenMsgCycleTime" BO_ 787 20;
BA_ "GenMsgNrOfRepetition" BO_ 787 0;
BA_ "GenMsgSendType" BO_ 787 0;
BA_ "GenMsgILSupport" BO_ 787 1;
BA_ "GenMsgNrOfRepetition" BO_ 1913 0;
BA_ "DiagResponse" BO_ 1913 1;
BA_ "GenMsgNrOfRepetition" BO_ 2041 0;
BA_ "DiagResponse" BO_ 2041 1;
BA_ "GenMsgNrOfRepetition" BO_ 2030 0;
BA_ "DiagResponse" BO_ 2030 1;
BA_ "GenMsgNrOfRepetition" BO_ 2029 0;
BA_ "DiagResponse" BO_ 2029 1;
BA_ "GenMsgNrOfRepetition" BO_ 2027 0;
BA_ "DiagResponse" BO_ 2027 1;
BA_ "GenMsgNrOfRepetition" BO_ 2025 0;
BA_ "DiagResponse" BO_ 2025 1;
BA_ "GenMsgNrOfRepetition" BO_ 2024 0;
BA_ "DiagResponse" BO_ 2024 1;
BA_ "GenMsgNrOfRepetition" BO_ 2014 0;
BA_ "DiagResponse" BO_ 2014 1;
BA_ "GenMsgNrOfRepetition" BO_ 2009 0;
BA_ "DiagResponse" BO_ 2009 1;
BA_ "GenMsgNrOfRepetition" BO_ 2008 0;
BA_ "DiagResponse" BO_ 2008 1;
BA_ "GenMsgNrOfRepetition" BO_ 2007 0;
BA_ "DiagResponse" BO_ 2007 1;
BA_ "GenMsgNrOfRepetition" BO_ 2006 0;
BA_ "DiagResponse" BO_ 2006 1;
BA_ "GenMsgNrOfRepetition" BO_ 1982 0;
BA_ "DiagResponse" BO_ 1982 1;
BA_ "GenMsgNrOfRepetition" BO_ 1981 0;
BA_ "DiagResponse" BO_ 1981 1;
BA_ "GenMsgNrOfRepetition" BO_ 1980 0;
BA_ "DiagResponse" BO_ 1980 1;
BA_ "GenMsgNrOfRepetition" BO_ 1979 0;
BA_ "DiagResponse" BO_ 1979 1;
BA_ "GenMsgNrOfRepetition" BO_ 1978 0;
BA_ "DiagResponse" BO_ 1978 1;
BA_ "GenMsgNrOfRepetition" BO_ 1977 0;
BA_ "DiagResponse" BO_ 1977 1;
BA_ "GenMsgNrOfRepetition" BO_ 1976 0;
BA_ "DiagResponse" BO_ 1976 1;
BA_ "GenMsgNrOfRepetition" BO_ 1975 0;
BA_ "DiagResponse" BO_ 1975 1;
BA_ "GenMsgNrOfRepetition" BO_ 1974 0;
BA_ "DiagResponse" BO_ 1974 1;
BA_ "GenMsgNrOfRepetition" BO_ 1951 0;
BA_ "DiagResponse" BO_ 1951 1;
BA_ "GenMsgNrOfRepetition" BO_ 1949 0;
BA_ "DiagResponse" BO_ 1949 1;
BA_ "GenMsgNrOfRepetition" BO_ 1946 0;
BA_ "DiagResponse" BO_ 1946 1;
BA_ "GenMsgNrOfRepetition" BO_ 1945 0;
BA_ "DiagResponse" BO_ 1945 1;
BA_ "GenMsgNrOfRepetition" BO_ 1938 0;
BA_ "DiagResponse" BO_ 1938 1;
BA_ "GenMsgNrOfRepetition" BO_ 1936 0;
BA_ "DiagResponse" BO_ 1936 1;
BA_ "GenMsgNrOfRepetition" BO_ 1919 0;
BA_ "DiagResponse" BO_ 1919 1;
BA_ "GenMsgNrOfRepetition" BO_ 1918 0;
BA_ "DiagResponse" BO_ 1918 1;
BA_ "GenMsgNrOfRepetition" BO_ 1917 0;
BA_ "DiagResponse" BO_ 1917 1;
BA_ "GenMsgNrOfRepetition" BO_ 1916 0;
BA_ "DiagResponse" BO_ 1916 1;
BA_ "GenMsgNrOfRepetition" BO_ 1910 0;
BA_ "DiagResponse" BO_ 1910 1;
BA_ "GenMsgNrOfRepetition" BO_ 1907 0;
BA_ "DiagResponse" BO_ 1907 1;
BA_ "GenMsgNrOfRepetition" BO_ 1906 0;
BA_ "DiagResponse" BO_ 1906 1;
BA_ "GenMsgNrOfRepetition" BO_ 1904 0;
BA_ "DiagResponse" BO_ 1904 1;
BA_ "GenMsgNrOfRepetition" BO_ 1885 0;
BA_ "DiagResponse" BO_ 1885 1;
BA_ "GenMsgNrOfRepetition" BO_ 1883 0;
BA_ "DiagResponse" BO_ 1883 1;
BA_ "GenMsgNrOfRepetition" BO_ 1880 0;
BA_ "DiagResponse" BO_ 1880 1;
BA_ "GenMsgNrOfRepetition" BO_ 1879 0;
BA_ "DiagResponse" BO_ 1879 1;
BA_ "GenMsgNrOfRepetition" BO_ 1878 0;
BA_ "DiagResponse" BO_ 1878 1;
BA_ "GenMsgNrOfRepetition" BO_ 1855 0;
BA_ "DiagResponse" BO_ 1855 1;
BA_ "GenMsgNrOfRepetition" BO_ 1854 0;
BA_ "DiagResponse" BO_ 1854 1;
BA_ "GenMsgNrOfRepetition" BO_ 1851 0;
BA_ "DiagResponse" BO_ 1851 1;
BA_ "GenMsgNrOfRepetition" BO_ 1848 0;
BA_ "DiagResponse" BO_ 1848 1;
BA_ "GenMsgNrOfRepetition" BO_ 1844 0;
BA_ "DiagResponse" BO_ 1844 1;
BA_ "GenMsgNrOfRepetition" BO_ 1840 0;
BA_ "DiagResponse" BO_ 1840 1;
BA_ "GenMsgNrOfRepetition" BO_ 1823 0;
BA_ "DiagResponse" BO_ 1823 1;
BA_ "GenMsgNrOfRepetition" BO_ 1811 0;
BA_ "DiagResponse" BO_ 1811 1;
BA_ "GenMsgNrOfRepetition" BO_ 1810 0;
BA_ "DiagResponse" BO_ 1810 1;
BA_ "GenMsgNrOfRepetition" BO_ 1809 0;
BA_ "DiagResponse" BO_ 1809 1;
BA_ "GenMsgNrOfRepetition" BO_ 1808 0;
BA_ "DiagResponse" BO_ 1808 1;
BA_ "GenMsgNrOfRepetition" BO_ 2005 0;
BA_ "DiagResponse" BO_ 2005 1;
BA_ "GenMsgNrOfRepetition" BO_ 1948 0;
BA_ "DiagResponse" BO_ 1948 1;
BA_ "GenMsgNrOfRepetition" BO_ 1874 0;
BA_ "DiagResponse" BO_ 1874 1;
BA_ "GenMsgNrOfRepetition" BO_ 1843 0;
BA_ "DiagResponse" BO_ 1843 1;
BA_ "GenMsgNrOfRepetition" BO_ 1905 0;
BA_ "DiagResponse" BO_ 1905 1;
BA_ "GenMsgNrOfRepetition" BO_ 2028 0;
BA_ "DiagResponse" BO_ 2028 1;
BA_ "GenMsgNrOfRepetition" BO_ 2026 0;
BA_ "DiagResponse" BO_ 2026 1;
BA_ "GenMsgNrOfRepetition" BO_ 1847 0;
BA_ "DiagResponse" BO_ 1847 1;
BA_ "GenMsgNrOfRepetition" BO_ 2004 0;
BA_ "DiagResponse" BO_ 2004 1;
BA_ "GenMsgNrOfRepetition" BO_ 2003 0;
BA_ "DiagResponse" BO_ 2003 1;
BA_ "GenMsgNrOfRepetition" BO_ 2002 0;
BA_ "DiagResponse" BO_ 2002 1;
BA_ "GenMsgNrOfRepetition" BO_ 2001 0;
BA_ "DiagResponse" BO_ 2001 1;
BA_ "GenMsgNrOfRepetition" BO_ 2000 0;
BA_ "DiagResponse" BO_ 2000 1;
BA_ "GenMsgNrOfRepetition" BO_ 1897 0;
BA_ "DiagRequest" BO_ 1897 1;
BA_ "GenMsgNrOfRepetition" BO_ 1999 0;
BA_ "DiagState" BO_ 1999 1;
BA_ "GenMsgNrOfRepetition" BO_ 2033 0;
BA_ "DiagRequest" BO_ 2033 1;
BA_ "GenMsgNrOfRepetition" BO_ 2019 0;
BA_ "DiagRequest" BO_ 2019 1;
BA_ "GenMsgNrOfRepetition" BO_ 2017 0;
BA_ "DiagRequest" BO_ 2017 1;
BA_ "GenMsgNrOfRepetition" BO_ 2016 0;
BA_ "DiagRequest" BO_ 2016 1;
BA_ "GenMsgNrOfRepetition" BO_ 1998 0;
BA_ "DiagRequest" BO_ 1998 1;
BA_ "GenMsgNrOfRepetition" BO_ 1993 0;
BA_ "DiagRequest" BO_ 1993 1;
BA_ "GenMsgNrOfRepetition" BO_ 1992 0;
BA_ "DiagRequest" BO_ 1992 1;
BA_ "GenMsgNrOfRepetition" BO_ 1991 0;
BA_ "DiagRequest" BO_ 1991 1;
BA_ "GenMsgNrOfRepetition" BO_ 1990 0;
BA_ "DiagRequest" BO_ 1990 1;
BA_ "GenMsgNrOfRepetition" BO_ 1966 0;
BA_ "DiagRequest" BO_ 1966 1;
BA_ "GenMsgNrOfRepetition" BO_ 1965 0;
BA_ "DiagRequest" BO_ 1965 1;
BA_ "GenMsgNrOfRepetition" BO_ 1964 0;
BA_ "DiagRequest" BO_ 1964 1;
BA_ "GenMsgNrOfRepetition" BO_ 1963 0;
BA_ "DiagRequest" BO_ 1963 1;
BA_ "GenMsgNrOfRepetition" BO_ 1962 0;
BA_ "DiagRequest" BO_ 1962 1;
BA_ "GenMsgNrOfRepetition" BO_ 1961 0;
BA_ "DiagRequest" BO_ 1961 1;
BA_ "GenMsgNrOfRepetition" BO_ 1960 0;
BA_ "DiagRequest" BO_ 1960 1;
BA_ "GenMsgNrOfRepetition" BO_ 1959 0;
BA_ "DiagRequest" BO_ 1959 1;
BA_ "GenMsgNrOfRepetition" BO_ 1958 0;
BA_ "DiagRequest" BO_ 1958 1;
BA_ "GenMsgNrOfRepetition" BO_ 1943 0;
BA_ "DiagResponse" BO_ 1943 1;
BA_ "GenMsgNrOfRepetition" BO_ 1942 0;
BA_ "DiagResponse" BO_ 1942 1;
BA_ "GenMsgNrOfRepetition" BO_ 1941 0;
BA_ "DiagResponse" BO_ 1941 1;
BA_ "GenMsgNrOfRepetition" BO_ 1939 0;
BA_ "DiagResponse" BO_ 1939 1;
BA_ "GenMsgNrOfRepetition" BO_ 1935 0;
BA_ "DiagRequest" BO_ 1935 1;
BA_ "GenMsgNrOfRepetition" BO_ 1933 0;
BA_ "DiagRequest" BO_ 1933 1;
BA_ "GenMsgNrOfRepetition" BO_ 1930 0;
BA_ "DiagRequest" BO_ 1930 1;
BA_ "GenMsgNrOfRepetition" BO_ 1929 0;
BA_ "DiagRequest" BO_ 1929 1;
BA_ "GenMsgNrOfRepetition" BO_ 1927 0;
BA_ "DiagRequest" BO_ 1927 1;
BA_ "GenMsgNrOfRepetition" BO_ 1926 0;
BA_ "DiagRequest" BO_ 1926 1;
BA_ "GenMsgNrOfRepetition" BO_ 1925 0;
BA_ "DiagRequest" BO_ 1925 1;
BA_ "GenMsgNrOfRepetition" BO_ 1923 0;
BA_ "DiagRequest" BO_ 1923 1;
BA_ "GenMsgNrOfRepetition" BO_ 1922 0;
BA_ "DiagRequest" BO_ 1922 1;
BA_ "GenMsgNrOfRepetition" BO_ 1920 0;
BA_ "DiagRequest" BO_ 1920 1;
BA_ "GenMsgNrOfRepetition" BO_ 1903 0;
BA_ "DiagRequest" BO_ 1903 1;
BA_ "GenMsgNrOfRepetition" BO_ 1902 0;
BA_ "DiagRequest" BO_ 1902 1;
BA_ "GenMsgNrOfRepetition" BO_ 1901 0;
BA_ "DiagRequest" BO_ 1901 1;
BA_ "GenMsgNrOfRepetition" BO_ 1900 0;
BA_ "DiagRequest" BO_ 1900 1;
BA_ "GenMsgNrOfRepetition" BO_ 1894 0;
BA_ "DiagRequest" BO_ 1894 1;
BA_ "GenMsgNrOfRepetition" BO_ 1891 0;
BA_ "DiagRequest" BO_ 1891 1;
BA_ "GenMsgNrOfRepetition" BO_ 1890 0;
BA_ "DiagRequest" BO_ 1890 1;
BA_ "GenMsgNrOfRepetition" BO_ 1888 0;
BA_ "DiagRequest" BO_ 1888 1;
BA_ "GenMsgNrOfRepetition" BO_ 1869 0;
BA_ "DiagRequest" BO_ 1869 1;
BA_ "GenMsgNrOfRepetition" BO_ 1867 0;
BA_ "DiagRequest" BO_ 1867 1;
BA_ "GenMsgNrOfRepetition" BO_ 1864 0;
BA_ "DiagRequest" BO_ 1864 1;
BA_ "GenMsgNrOfRepetition" BO_ 1863 0;
BA_ "DiagRequest" BO_ 1863 1;
BA_ "GenMsgNrOfRepetition" BO_ 1862 0;
BA_ "DiagRequest" BO_ 1862 1;
BA_ "GenMsgNrOfRepetition" BO_ 1839 0;
BA_ "DiagRequest" BO_ 1839 1;
BA_ "GenMsgNrOfRepetition" BO_ 1838 0;
BA_ "DiagRequest" BO_ 1838 1;
BA_ "GenMsgNrOfRepetition" BO_ 1835 0;
BA_ "DiagRequest" BO_ 1835 1;
BA_ "GenMsgNrOfRepetition" BO_ 1832 0;
BA_ "DiagRequest" BO_ 1832 1;
BA_ "GenMsgNrOfRepetition" BO_ 1828 0;
BA_ "DiagRequest" BO_ 1828 1;
BA_ "GenMsgNrOfRepetition" BO_ 1824 0;
BA_ "DiagRequest" BO_ 1824 1;
BA_ "GenMsgNrOfRepetition" BO_ 1807 0;
BA_ "DiagRequest" BO_ 1807 1;
BA_ "GenMsgNrOfRepetition" BO_ 1795 0;
BA_ "DiagRequest" BO_ 1795 1;
BA_ "GenMsgNrOfRepetition" BO_ 1794 0;
BA_ "DiagRequest" BO_ 1794 1;
BA_ "GenMsgNrOfRepetition" BO_ 1793 0;
BA_ "DiagRequest" BO_ 1793 1;
BA_ "GenMsgNrOfRepetition" BO_ 1792 0;
BA_ "DiagRequest" BO_ 1792 1;
BA_ "GenMsgNrOfRepetition" BO_ 1989 0;
BA_ "DiagRequest" BO_ 1989 1;
BA_ "GenMsgNrOfRepetition" BO_ 1932 0;
BA_ "DiagRequest" BO_ 1932 1;
BA_ "GenMsgNrOfRepetition" BO_ 1858 0;
BA_ "DiagRequest" BO_ 1858 1;
BA_ "GenMsgNrOfRepetition" BO_ 1827 0;
BA_ "DiagRequest" BO_ 1827 1;
BA_ "GenMsgNrOfRepetition" BO_ 1889 0;
BA_ "DiagRequest" BO_ 1889 1;
BA_ "GenMsgNrOfRepetition" BO_ 2020 0;
BA_ "DiagRequest" BO_ 2020 1;
BA_ "GenMsgNrOfRepetition" BO_ 2022 0;
BA_ "DiagRequest" BO_ 2022 1;
BA_ "GenMsgNrOfRepetition" BO_ 2021 0;
BA_ "DiagRequest" BO_ 2021 1;
BA_ "GenMsgNrOfRepetition" BO_ 2018 0;
BA_ "DiagRequest" BO_ 2018 1;
BA_ "GenMsgNrOfRepetition" BO_ 1831 0;
BA_ "DiagRequest" BO_ 1831 1;
BA_ "GenMsgNrOfRepetition" BO_ 1988 0;
BA_ "DiagRequest" BO_ 1988 1;
BA_ "GenMsgNrOfRepetition" BO_ 1987 0;
BA_ "DiagRequest" BO_ 1987 1;
BA_ "GenMsgNrOfRepetition" BO_ 1986 0;
BA_ "DiagRequest" BO_ 1986 1;
BA_ "GenMsgNrOfRepetition" BO_ 1985 0;
BA_ "DiagRequest" BO_ 1985 1;
BA_ "GenMsgNrOfRepetition" BO_ 1984 0;
BA_ "DiagRequest" BO_ 1984 1;
BA_ "GenMsgCycleTime" BO_ 1560 1000;
BA_ "GenMsgNrOfRepetition" BO_ 1560 0;
BA_ "GenMsgSendType" BO_ 1560 0;
BA_ "NmAsrMessage" BO_ 1560 1;
BA_ "GenMsgCycleTime" BO_ 1266 100;
BA_ "GenMsgCycleTimeFast" BO_ 1266 100;
BA_ "GenMsgDelayTime" BO_ 1266 5;
BA_ "GenMsgILSupport" BO_ 1266 1;
BA_ "GenMsgCycleTime" BO_ 1312 50;
BA_ "GenMsgNrOfRepetition" BO_ 1312 0;
BA_ "GenMsgSendType" BO_ 1312 0;
BA_ "GenMsgILSupport" BO_ 1312 1;
BA_ "GenMsgCycleTime" BO_ 1243 100;
BA_ "GenMsgNrOfRepetition" BO_ 1243 0;
BA_ "GenMsgSendType" BO_ 1243 0;
BA_ "GenMsgILSupport" BO_ 1243 1;
BA_ "GenMsgCycleTime" BO_ 1140 100;
BA_ "GenMsgNrOfRepetition" BO_ 1140 0;
BA_ "GenMsgSendType" BO_ 1140 0;
BA_ "GenMsgILSupport" BO_ 1140 1;
BA_ "GenMsgCycleTime" BO_ 1121 100;
BA_ "GenMsgNrOfRepetition" BO_ 1121 0;
BA_ "GenMsgSendType" BO_ 1121 0;
BA_ "GenMsgILSupport" BO_ 1121 1;
BA_ "GenMsgNrOfRepetition" BO_ 1517 0;
BA_ "GenMsgILSupport" BO_ 1517 1;
BA_ "GenMsgNrOfRepetition" BO_ 1515 0;
BA_ "GenMsgILSupport" BO_ 1515 1;
BA_ "GenMsgNrOfRepetition" BO_ 1298 0;
BA_ "GenMsgILSupport" BO_ 1298 1;
BA_ "GenMsgNrOfRepetition" BO_ 1289 0;
BA_ "GenMsgILSupport" BO_ 1289 1;
BA_ "GenMsgNrOfRepetition" BO_ 759 0;
BA_ "GenMsgILSupport" BO_ 759 1;
BA_ "GenMsgNrOfRepetition" BO_ 755 0;
BA_ "GenMsgILSupport" BO_ 755 1;
BA_ "GenMsgDelayTime" BO_ 1151 5;
BA_ "GenMsgNrOfRepetition" BO_ 1151 0;
BA_ "GenMsgILSupport" BO_ 1151 1;
BA_ "GenMsgNrOfRepetition" BO_ 1116 0;
BA_ "GenMsgILSupport" BO_ 1116 1;
BA_ "GenMsgCycleTime" BO_ 1177 100;
BA_ "GenMsgCycleTimeFast" BO_ 1177 100;
BA_ "GenMsgDelayTime" BO_ 1177 5;
BA_ "GenMsgILSupport" BO_ 1177 1;
BA_ "GenSigSendType" SG_ 1537 Nwmcommand1 0;
BA_ "GenSigSendType" SG_ 928 YAS_2_Checksum 0;
BA_ "GenSigSendType" SG_ 928 LongitudinalAcceleration 0;
BA_ "GenSigStartValue" SG_ 928 LongitudinalAccelerationSigValid 3;
BA_ "GenSigSendType" SG_ 928 LongitudinalAccelerationSigValid 0;
BA_ "GenSigSendType" SG_ 928 YAS_2_MessageCounter 0;
BA_ "GenSigSendType" SG_ 926 YAS_1_Checksum 0;
BA_ "GenSigSendType" SG_ 926 YawRate 0;
BA_ "GenSigStartValue" SG_ 926 YawrateSigValidData 3;
BA_ "GenSigSendType" SG_ 926 YawrateSigValidData 0;
BA_ "GenSigSendType" SG_ 926 YAS_1_MessageCounter 0;
BA_ "GenSigSendType" SG_ 1206 SHU2R_RSeatVentnSts 0;
BA_ "GenSigSendType" SG_ 1206 SHU2R_RSeatHeatSts 0;
BA_ "GenSigSendType" SG_ 1202 SHU2M_MSeatVentnSts 0;
BA_ "GenSigSendType" SG_ 1202 SHU2M_MSeatHeatSts 0;
BA_ "GenSigSendType" SG_ 1194 SHU2L_LSeatVentnSts 0;
BA_ "GenSigSendType" SG_ 1194 SHU2L_LSeatHeatSts 0;
BA_ "GenSigSendType" SG_ 1190 SHU1R_RSeatAutVentnSts 0;
BA_ "GenSigSendType" SG_ 1190 SHU1R_RSeatAutHeatSts 0;
BA_ "GenSigSendType" SG_ 1190 SHU1R_RSeatVentnSts 0;
BA_ "GenSigSendType" SG_ 1190 SHU1R_RSeatHeatSts 0;
BA_ "GenSigSendType" SG_ 1186 SHU1L_LSeatAutVentnSts 0;
BA_ "GenSigSendType" SG_ 1186 SHU1L_LSeatAutHeatSts 0;
BA_ "GenSigSendType" SG_ 1186 SHU1L_LSeatVentnSts 0;
BA_ "GenSigSendType" SG_ 1186 SHU1L_LSeatHeatSts 0;
BA_ "GenSigSendType" SG_ 1170 SCU_2_CRC 0;
BA_ "GenSigSendType" SG_ 1170 SCU_2_MessageCounter 0;
BA_ "GenSigSendType" SG_ 1170 SCU_2_SeatLegSpprtPosnStsTar 0;
BA_ "GenSigSendType" SG_ 1170 SCU_2_SeatLvlPosnStsTar 0;
BA_ "GenSigSendType" SG_ 1170 SCU_2_SeatHdrestHeiAdjmt 0;
BA_ "GenSigSendType" SG_ 1170 SCU_2_BackrAgPosnStsTar 0;
BA_ "GenSigSendType" SG_ 1170 SCU_2_SeatCushPosnSts 0;
BA_ "GenSigSendType" SG_ 1170 SCU_2_SeatHeiPosnStsTar 0;
BA_ "GenSigSendType" SG_ 1090 MemoryKeySts 0;
BA_ "GenSigSendType" SG_ 1090 PsngrSeatVentilationFeedbackSts 0;
BA_ "GenSigSendType" SG_ 1090 DriverSeatVentilationFeedbackSts 0;
BA_ "GenSigSendType" SG_ 1090 Seat_ExtMirror_PositionInfo 0;
BA_ "GenSigSendType" SG_ 1090 SCURelateKeyOrFaceIDFeedbackSts 0;
BA_ "GenSigSendType" SG_ 1090 Seat_ExtMirror_MemorySts 0;
BA_ "GenSigSendType" SG_ 1090 PsngrSeatHeatFeedbackSts 0;
BA_ "GenSigSendType" SG_ 1090 DriverSeatHeatFeedbackSts 0;
BA_ "GenSigSendType" SG_ 1090 ReverseExtMirrorFeedbackSts 0;
BA_ "GenSigSendType" SG_ 1090 EasyEntryFeedbackSts 0;
BA_ "GenSigSendType" SG_ 1090 Seat_ExtMirror_MemoryReq 0;
BA_ "GenSigSendType" SG_ 1090 Seat_ExtMirror_MemoryEnable 0;
BA_ "GenSigSendType" SG_ 924 SAM_1_GCRCCheck 0;
BA_ "GenSigSendType" SG_ 924 SAM_1_G_MessageCounter 0;
BA_ "GenSigStartValue" SG_ 924 SteeringAngleSpeedValidData 1;
BA_ "GenSigSendType" SG_ 924 SteeringAngleSpeedValidData 0;
BA_ "GenSigStartValue" SG_ 924 SteeringAngleValidData 1;
BA_ "GenSigSendType" SG_ 924 SteeringAngleValidData 0;
BA_ "GenSigSendType" SG_ 924 SASCalibrated 0;
BA_ "GenSigSendType" SG_ 924 AngleFailure 0;
BA_ "GenSigStartValue" SG_ 924 SteeringAngleSpeed 255;
BA_ "GenSigSendType" SG_ 924 SteeringAngleSpeed 0;
BA_ "GenSigStartValue" SG_ 924 SteeringAngle 65535;
BA_ "GenSigSendType" SG_ 924 SteeringAngle 0;
BA_ "GenSigSendType" SG_ 498 RLCR_2_RCTBONOFFSts 0;
BA_ "GenSigSendType" SG_ 498 RLCR_2_RAEBONOFFSts 0;
BA_ "GenSigStartValue" SG_ 1141 LHSFRadarSensorDistance 126;
BA_ "GenSigSendType" SG_ 1141 LHSFRadarSensorDistance 0;
BA_ "GenSigStartValue" SG_ 1141 RHSFRadarSensorDistance 126;
BA_ "GenSigSendType" SG_ 1141 RHSFRadarSensorDistance 0;
BA_ "GenSigStartValue" SG_ 1141 LHSRRadarSensorDistance 126;
BA_ "GenSigSendType" SG_ 1141 LHSRRadarSensorDistance 0;
BA_ "GenSigStartValue" SG_ 1141 RHSRRadarSensorDistance 126;
BA_ "GenSigSendType" SG_ 1141 RHSRRadarSensorDistance 0;
BA_ "GenSigStartValue" SG_ 1078 PLG_PositionSts 100;
BA_ "GenSigSendType" SG_ 1078 PLG_PositionSts 0;
BA_ "GenSigSendType" SG_ 1078 PLG_OperateSts 0;
BA_ "GenSigStartValue" SG_ 1078 PLG_Set_MaxPosition 100;
BA_ "GenSigSendType" SG_ 1078 PLG_Set_MaxPosition 0;
BA_ "GenSigSendType" SG_ 1042 PEPS_BLTKey_PESts 0;
BA_ "GenSigSendType" SG_ 1042 WelcomLightPollingSts 0;
BA_ "GenSigSendType" SG_ 1042 PEPS_IntelligentOpenSts 0;
BA_ "GenSigSendType" SG_ 1042 PEPSPollingSts 0;
BA_ "GenSigSendType" SG_ 998 RemoteStartSts 0;
BA_ "GenSigSendType" SG_ 998 Start_StopRequest 0;
BA_ "GenSigStartValue" SG_ 998 IDInformation 1;
BA_ "GenSigSendType" SG_ 998 IDInformation 0;
BA_ "GenSigSendType" SG_ 1124 NFC_1_DispCardPosn 0;
BA_ "GenSigSendType" SG_ 1124 NFC_1_IDList 0;
BA_ "GenSigSendType" SG_ 1124 NFC_1_ID 0;
BA_ "GenSigSendType" SG_ 864 MFS_ICM_Right 1;
BA_ "GenSigSendType" SG_ 864 MFS_ICM_Left 1;
BA_ "GenSigSendType" SG_ 864 MFS_ICM_Down 1;
BA_ "GenSigSendType" SG_ 864 MFS_ICM_UP 1;
BA_ "GenSigSendType" SG_ 864 MFS_Menu 1;
BA_ "GenSigSendType" SG_ 945 MFS_ICMFctChg 1;
BA_ "GenSigSendType" SG_ 945 MFS_Customize 1;
BA_ "GenSigSendType" SG_ 945 MFS_WeChat 1;
BA_ "GenSigSendType" SG_ 945 MFS_TJA_ICA_ON_OFF 1;
BA_ "GenSigSendType" SG_ 945 MFS_Start_Pause 1;
BA_ "GenSigSendType" SG_ 945 MFS_Mute 1;
BA_ "GenSigSendType" SG_ 945 MFS_VoiceRecognition 1;
BA_ "GenSigSendType" SG_ 945 MFS_PhoneHangUP 1;
BA_ "GenSigSendType" SG_ 945 MFS_PhonePickUP 1;
BA_ "GenSigSendType" SG_ 945 MFS_SeekDown 1;
BA_ "GenSigSendType" SG_ 945 MFS_SeekUp 1;
BA_ "GenSigSendType" SG_ 945 MFS_VolumeDown 1;
BA_ "GenSigSendType" SG_ 945 MFS_VolumeUp 1;
BA_ "GenSigSendType" SG_ 945 MFS_Mode 1;
BA_ "GenSigSendType" SG_ 1149 IMMO_Teach 1;
BA_ "GenSigSendType" SG_ 1110 IMMO_Chall 1;
BA_ "GenSigSendType" SG_ 1248 IDCU_11_DrvAssiStylests 0;
BA_ "GenSigSendType" SG_ 1248 IDCU_11_DCLCONOFFsts 0;
BA_ "GenSigStartValue" SG_ 1251 FCM_FRM_5_DAIONOFFSts 1;
BA_ "GenSigSendType" SG_ 1251 FCM_FRM_5_DAIONOFFSts 0;
BA_ "GenSigStartValue" SG_ 1251 FCM_FRM_5_SCFONOFFSts 1;
BA_ "GenSigSendType" SG_ 1251 FCM_FRM_5_SCFONOFFSts 0;
BA_ "GenSigStartValue" SG_ 1251 FCM_FRM_5_FCWONOFFSts 1;
BA_ "GenSigSendType" SG_ 1251 FCM_FRM_5_FCWONOFFSts 0;
BA_ "GenSigStartValue" SG_ 1251 FCM_FRM_5_FCWSnvtySts 1;
BA_ "GenSigSendType" SG_ 1251 FCM_FRM_5_FCWSnvtySts 0;
BA_ "GenSigStartValue" SG_ 1251 FCM_FRM_5_AEBONOFFSts 1;
BA_ "GenSigSendType" SG_ 1251 FCM_FRM_5_AEBONOFFSts 0;
BA_ "GenSigStartValue" SG_ 1245 FCM_5_ELKONOFFSts 1;
BA_ "GenSigSendType" SG_ 1245 FCM_5_ELKONOFFSts 0;
BA_ "GenSigStartValue" SG_ 1245 FCM_5_LDWLDPSnvtySts 1;
BA_ "GenSigSendType" SG_ 1245 FCM_5_LDWLDPSnvtySts 0;
BA_ "GenSigStartValue" SG_ 1245 FCM_5_LDPONOFFSts 2;
BA_ "GenSigSendType" SG_ 1245 FCM_5_LDPONOFFSts 0;
BA_ "GenSigStartValue" SG_ 1245 FCM_5_WarnModSts 3;
BA_ "GenSigSendType" SG_ 1245 FCM_5_WarnModSts 0;
BA_ "GenSigStartValue" SG_ 1245 FCM_5_LDWONOFFSts 1;
BA_ "GenSigSendType" SG_ 1245 FCM_5_LDWONOFFSts 0;
BA_ "GenSigStartValue" SG_ 1245 FCM_5_TLIONOFFSts 1;
BA_ "GenSigSendType" SG_ 1245 FCM_5_TLIONOFFSts 0;
BA_ "GenSigStartValue" SG_ 1245 FCM_5_TSIONOFFSts 1;
BA_ "GenSigSendType" SG_ 1245 FCM_5_TSIONOFFSts 0;
BA_ "GenSigStartValue" SG_ 1245 FCM_5_HMAONOFFSts 1;
BA_ "GenSigSendType" SG_ 1245 FCM_5_HMAONOFFSts 0;
BA_ "GenSigStartValue" SG_ 1245 FCM_5_IESONOFFSts 1;
BA_ "GenSigSendType" SG_ 1245 FCM_5_IESONOFFSts 0;
BA_ "GenSigStartValue" SG_ 1245 FCM_5_SLAONOFFSts 1;
BA_ "GenSigSendType" SG_ 1245 FCM_5_SLAONOFFSts 0;
BA_ "GenSigStartValue" SG_ 1245 FCM_5_TJAICAExitTextInfoSts 1;
BA_ "GenSigSendType" SG_ 1245 FCM_5_TJAICAExitTextInfoSts 0;
BA_ "GenSigSendType" SG_ 1240 EMS_BoostP 0;
BA_ "GenSigSendType" SG_ 1057 LimitSpeedSts 0;
BA_ "GenSigSendType" SG_ 1057 CruiseLimitSpeedValue 0;
BA_ "GenSigSendType" SG_ 1057 BrakePedalSts 0;
BA_ "GenSigSendType" SG_ 1057 BrakePedalStsValidData 0;
BA_ "GenSigSendType" SG_ 1057 GasPedalPositionInvalidData 0;
BA_ "GenSigSendType" SG_ 1057 GasPedalPosition 0;
BA_ "GenSigSendType" SG_ 1277 CLM_10_SeRowDispSts 0;
BA_ "GenSigSendType" SG_ 1277 CLM_10_RfgtLkDispSts 0;
BA_ "GenSigSendType" SG_ 1277 CLM_10_ReRowDispSts 0;
BA_ "GenSigSendType" SG_ 1277 CLM_10_ReRowBlowSpdLvlSts 0;
BA_ "GenSigSendType" SG_ 1277 CLM_10_ReRowWorkSts 0;
BA_ "GenSigSendType" SG_ 1277 CLM_10_RmnDispSts 0;
BA_ "GenSigSendType" SG_ 1277 CLM_10_AQSDispSts 0;
BA_ "GenSigSendType" SG_ 1277 SelfTestResult2 1;
BA_ "GenSigSendType" SG_ 1277 IntelligentCustomSts 0;
BA_ "GenSigSendType" SG_ 1277 CLM_10_SeRowWorkSts 0;
BA_ "GenSigSendType" SG_ 1277 CLM_10_SeRowBlowSpdLvlDispSts 0;
BA_ "GenSigSendType" SG_ 1277 PtcHeatgSts 0;
BA_ "GenSigStartValue" SG_ 1334 FragranCeconsistenceLevelSts 1;
BA_ "GenSigSendType" SG_ 1334 FragranCeconsistenceLevelSts 0;
BA_ "GenSigSendType" SG_ 1334 Pos3_FragranceTypesSts 0;
BA_ "GenSigSendType" SG_ 1334 Pos2_FragranceTypesSts 0;
BA_ "GenSigSendType" SG_ 1334 PM2_5AutoRunSetSts 0;
BA_ "GenSigSendType" SG_ 1334 PM2_5_Incar_Level 0;
BA_ "GenSigSendType" SG_ 1334 PM2_5_Outcar_Level 0;
BA_ "GenSigSendType" SG_ 1334 FragranceDisplaysts 0;
BA_ "GenSigSendType" SG_ 1334 FragrancePositionSwt 0;
BA_ "GenSigSendType" SG_ 1334 ACModeCustomSts 0;
BA_ "GenSigSendType" SG_ 1334 FragranceWelcomeModeSts 0;
BA_ "GenSigStartValue" SG_ 1334 RefreshFunctionSts 1;
BA_ "GenSigSendType" SG_ 1334 RefreshFunctionSts 0;
BA_ "GenSigSendType" SG_ 1334 Pos1_FragranceTypesSts 0;
BA_ "GenSigStartValue" SG_ 1334 PM2_5AutoRunSts 1;
BA_ "GenSigSendType" SG_ 1334 PM2_5AutoRunSts 0;
BA_ "GenSigStartValue" SG_ 1334 FragranceSWSts 1;
BA_ "GenSigSendType" SG_ 1334 FragranceSWSts 0;
BA_ "GenSigSendType" SG_ 1334 AutoBltCalllowBlowSpeedSts 0;
BA_ "GenSigSendType" SG_ 1334 AutoParkInnerCirculationSts 0;
BA_ "GenSigSendType" SG_ 1334 PM2_5_IncarSts 0;
BA_ "GenSigSendType" SG_ 1334 PM2_5_ExtSts 0;
BA_ "GenSigSendType" SG_ 1334 PM2_5_ext 0;
BA_ "GenSigSendType" SG_ 1334 FragranceShortageWarning 0;
BA_ "GenSigSendType" SG_ 1334 ION_Function_Sts 0;
BA_ "GenSigSendType" SG_ 1334 PM2_5_incar 0;
BA_ "GenSigSendType" SG_ 1333 AUTODefrostDisplaySts 1;
BA_ "GenSigSendType" SG_ 1333 TempKnobRollingCounter 3;
BA_ "GenSigSendType" SG_ 1333 BlowSpeedLevelDisplaySts 3;
BA_ "GenSigSendType" SG_ 1333 AUTODefrostForceOpenSts 1;
BA_ "GenSigSendType" SG_ 1333 PM2_5Displaysts 1;
BA_ "GenSigSendType" SG_ 1333 PM2_5overproofDisplaySts 1;
BA_ "GenSigSendType" SG_ 1333 FiltertchangeDisplaySts 1;
BA_ "GenSigSendType" SG_ 1333 REARInhibitSts 1;
BA_ "GenSigSendType" SG_ 1333 AUTODefrostOnSts 0;
BA_ "GenSigStartValue" SG_ 1306 SetTemperature_R_F 17;
BA_ "GenSigSendType" SG_ 1306 SetTemperature_R_F 1;
BA_ "GenSigStartValue" SG_ 1306 SetTemperature_L_F 17;
BA_ "GenSigSendType" SG_ 1306 SetTemperature_L_F 1;
BA_ "GenSigSendType" SG_ 1306 SelfTestResult 1;
BA_ "GenSigSendType" SG_ 1306 TemperatureUnit 1;
BA_ "GenSigSendType" SG_ 1306 ZoneSelectionDisplaySts 1;
BA_ "GenSigStartValue" SG_ 1306 CirculationModeDisplaySts 1;
BA_ "GenSigSendType" SG_ 1306 CirculationModeDisplaySts 1;
BA_ "GenSigStartValue" SG_ 1306 SetTemperature_R_C 17;
BA_ "GenSigSendType" SG_ 1306 SetTemperature_R_C 1;
BA_ "GenSigStartValue" SG_ 1306 SetTemperature_L_C 17;
BA_ "GenSigSendType" SG_ 1306 SetTemperature_L_C 1;
BA_ "GenSigSendType" SG_ 1306 BlowDelayOffSts 0;
BA_ "GenSigSendType" SG_ 1306 BlowAdvanceOnSts 0;
BA_ "GenSigSendType" SG_ 1306 DisplayActive 1;
BA_ "GenSigSendType" SG_ 1306 SelfTestActive 1;
BA_ "GenSigSendType" SG_ 1306 PM2_5Sts 0;
BA_ "GenSigSendType" SG_ 1306 WorkingSts 1;
BA_ "GenSigStartValue" SG_ 1306 ModeAdjustDisplaySts 5;
BA_ "GenSigSendType" SG_ 1306 ModeAdjustDisplaySts 1;
BA_ "GenSigSendType" SG_ 1306 FrontDeforest_MaxDisplaySts 0;
BA_ "GenSigSendType" SG_ 1306 ACRequestDisplaySts 1;
BA_ "GenSigSendType" SG_ 1306 AutoDisplaySts 1;
BA_ "GenSigSendType" SG_ 1306 Reserved_AC_MaxSts 1;
BA_ "GenSigSendType" SG_ 1306 ExternalTemperatureFailSts 0;
BA_ "GenSigStartValue" SG_ 1306 ExternalTemperature_C 254;
BA_ "GenSigSendType" SG_ 1306 ExternalTemperature_C 0;
BA_ "GenSigStartValue" SG_ 1306 ExternalTemperature_F 254;
BA_ "GenSigSendType" SG_ 1306 ExternalTemperature_F 0;
BA_ "GenSigSendType" SG_ 1104 OBDDiagnosisReqInd 0;
BA_ "GenSigSendType" SG_ 1178 BDM_26_RRWinPosn 0;
BA_ "GenSigSendType" SG_ 1178 BDM_26_RLWinPosn 0;
BA_ "GenSigSendType" SG_ 1178 BDM_26_FRWinPosn 0;
BA_ "GenSigSendType" SG_ 1178 BDM_26_FLWinPosn 0;
BA_ "GenSigSendType" SG_ 1007 BDM_25_AmbBrightness 0;
BA_ "GenSigSendType" SG_ 1007 BDM_25_FWBrightness 0;
BA_ "GenSigSendType" SG_ 1287 BCM_22_WiprSnvtySetFb 0;
BA_ "GenSigSendType" SG_ 1287 PassSeatMsgStr_LvlSts 0;
BA_ "GenSigSendType" SG_ 1287 PassSeatMsg_ModeSts 0;
BA_ "GenSigSendType" SG_ 746 TotODOMtrBkp 0;
BA_ "GenSigSendType" SG_ 746 LbaLimits 0;
BA_ "GenSigSendType" SG_ 746 BDM_OTAPwrOnReqFb 0;
BA_ "GenSigSendType" SG_ 746 BDM_OTAPwrDwnReqFb 0;
BA_ "GenSigSendType" SG_ 746 BDM_OTAModStsFb 0;
BA_ "GenSigSendType" SG_ 746 SlaveVehMod 0;
BA_ "GenSigSendType" SG_ 746 VehPwrMod 0;
BA_ "GenSigSendType" SG_ 901 CTP_VolStepValForDVD 0;
BA_ "GenSigSendType" SG_ 901 CTP_VolPlusMinusForDVDSts 0;
BA_ "GenSigSendType" SG_ 901 CTP_HomeKeyForIHUSts 0;
BA_ "GenSigSendType" SG_ 901 CTP_PowerKeyForIHUSts 0;
BA_ "GenSigSendType" SG_ 901 CTP_TrackMod 0;
BA_ "GenSigSendType" SG_ 901 CTP_DriveModeSet 0;
BA_ "GenSigSendType" SG_ 901 CTP_NavKeyForIHUSts 0;
BA_ "GenSigSendType" SG_ 901 CTPKeyVoiceRemindReq 0;
BA_ "GenSigSendType" SG_ 901 IHUSetSwitch 0;
BA_ "GenSigSendType" SG_ 901 AVMSwitch 0;
BA_ "GenSigStartValue" SG_ 936 IBS_SOH 255;
BA_ "GenSigSendType" SG_ 936 IBS_SOH 0;
BA_ "GenSigStartValue" SG_ 936 IBS_SOC 255;
BA_ "GenSigSendType" SG_ 936 IBS_SOC 0;
BA_ "GenSigSendType" SG_ 934 IBS_Current 0;
BA_ "GenSigStartValue" SG_ 934 IBS_Voltage 16383;
BA_ "GenSigSendType" SG_ 934 IBS_Voltage 0;
BA_ "GenSigSendType" SG_ 1063 Lbatip 0;
BA_ "GenSigStartValue" SG_ 1063 TheaterDimmingColorFeedback_64 2;
BA_ "GenSigSendType" SG_ 1063 TheaterDimmingColorFeedback_64 0;
BA_ "GenSigSendType" SG_ 1063 Rainfall 0;
BA_ "GenSigSendType" SG_ 1063 HUDBriUnit 0;
BA_ "GenSigStartValue" SG_ 1063 HUDBriRawVal 127;
BA_ "GenSigSendType" SG_ 1063 HUDBriRawVal 0;
BA_ "GenSigStartValue" SG_ 1520 SN 1;
BA_ "GenSigSendType" SG_ 1077 RvsExtMirrFbSts 0;
BA_ "GenSigSendType" SG_ 1077 Reserved_RainingWarning 0;
BA_ "GenSigSendType" SG_ 1077 SRF_Hall2SensorError 0;
BA_ "GenSigSendType" SG_ 1077 SRF_Hall1SensorError 0;
BA_ "GenSigSendType" SG_ 1077 SRF_SunroofOverVolt 0;
BA_ "GenSigSendType" SG_ 1077 SRF_SunroofUnderVolt 0;
BA_ "GenSigSendType" SG_ 1077 SRF_LINCommunicationERROR 0;
BA_ "GenSigSendType" SG_ 1077 SRF_SwitchError 0;
BA_ "GenSigSendType" SG_ 1077 SRF_OverHeatProtect 0;
BA_ "GenSigSendType" SG_ 1077 SRF_MotorRelayError 0;
BA_ "GenSigSendType" SG_ 1077 AssociatedWithDriverModeFeedback 0;
BA_ "GenSigStartValue" SG_ 1077 TheaterDimmingBrightnessFeedback 2;
BA_ "GenSigSendType" SG_ 1077 TheaterDimmingBrightnessFeedback 0;
BA_ "GenSigStartValue" SG_ 1077 TheaterDimmingColorFeedback 5;
BA_ "GenSigSendType" SG_ 1077 TheaterDimmingColorFeedback 0;
BA_ "GenSigSendType" SG_ 1077 SRF_Sunshade_OperateSts 0;
BA_ "GenSigSendType" SG_ 1077 RRWindowSts 0;
BA_ "GenSigSendType" SG_ 1077 RLWindowSts 0;
BA_ "GenSigSendType" SG_ 1077 WindowInhibitSts 0;
BA_ "GenSigSendType" SG_ 1077 FRWindow_Sts 0;
BA_ "GenSigSendType" SG_ 1077 FLWindow_Sts 0;
BA_ "GenSigSendType" SG_ 1077 Window_OperateSts 0;
BA_ "GenSigSendType" SG_ 1077 Reserved_SRF_Error 0;
BA_ "GenSigSendType" SG_ 1077 SRF_InitStatus 0;
BA_ "GenSigSendType" SG_ 1077 AssociatedWithMusicModeFeedback 0;
BA_ "GenSigStartValue" SG_ 1077 TheaterDimmingStatusFeedback 1;
BA_ "GenSigSendType" SG_ 1077 TheaterDimmingStatusFeedback 0;
BA_ "GenSigSendType" SG_ 1077 SRF_PositionSts 0;
BA_ "GenSigSendType" SG_ 1077 SRF_OperateSts 0;
BA_ "GenSigSendType" SG_ 913 AutoHighSpeedRequest 0;
BA_ "GenSigSendType" SG_ 913 RainDetected 0;
BA_ "GenSigSendType" SG_ 913 WiperSts 0;
BA_ "GenSigSendType" SG_ 913 SteeringWheelheatingSts 0;
BA_ "GenSigSendType" SG_ 913 RARDfstCmd 0;
BA_ "GenSigSendType" SG_ 913 HazardLightSW 0;
BA_ "GenSigSendType" SG_ 1217 ASU_1_ASUSysFailrSts 0;
BA_ "GenSigSendType" SG_ 1217 ASU_1_SetModsts 0;
BA_ "GenSigSendType" SG_ 1217 ASU_1_AssocWithDrvrModFB 0;
BA_ "GenSigSendType" SG_ 554 ReasonForDVDnotDisplyAPA 0;
BA_ "GenSigSendType" SG_ 554 APAFailureSts 0;
BA_ "GenSigSendType" SG_ 554 APA_Active 0;
BA_ "GenSigSendType" SG_ 554 AVM_APA_SystemSts 0;
BA_ "GenSigSendType" SG_ 1267 AIPM_2_DriveModeSet 0;
BA_ "GenSigSendType" SG_ 1265 PanelKeyVoiceRemindReq 1;
BA_ "GenSigSendType" SG_ 932 ABSESP_8_Checksum 0;
BA_ "GenSigSendType" SG_ 932 ABSESP_8_MessageCounter 0;
BA_ "GenSigStartValue" SG_ 932 RHRWheelSpeedRawValidData 1;
BA_ "GenSigSendType" SG_ 932 RHRWheelSpeedRawValidData 0;
BA_ "GenSigSendType" SG_ 932 RHRWheelDriveDirection 0;
BA_ "GenSigSendType" SG_ 932 RHRWheelSpeedRaw 0;
BA_ "GenSigStartValue" SG_ 932 LHRWheelSpeedRawValidData 1;
BA_ "GenSigSendType" SG_ 932 LHRWheelSpeedRawValidData 0;
BA_ "GenSigSendType" SG_ 932 LHRWheelDriveDirection 0;
BA_ "GenSigSendType" SG_ 932 LHRWheelSpeedRaw 0;
BA_ "GenSigSendType" SG_ 931 ABSESP_7_Checksum 0;
BA_ "GenSigSendType" SG_ 931 ABSESP_7_MessageCounter 0;
BA_ "GenSigStartValue" SG_ 931 RHFWheelSpeedRawValidData 1;
BA_ "GenSigSendType" SG_ 931 RHFWheelSpeedRawValidData 0;
BA_ "GenSigSendType" SG_ 931 RHFWheelDriveDirection 0;
BA_ "GenSigSendType" SG_ 931 RHFWheelSpeedRaw 0;
BA_ "GenSigStartValue" SG_ 931 LHFWheelSpeedRawValidData 1;
BA_ "GenSigSendType" SG_ 931 LHFWheelSpeedRawValidData 0;
BA_ "GenSigSendType" SG_ 931 LHFWheelDriveDirection 0;
BA_ "GenSigSendType" SG_ 931 LHFWheelSpeedRaw 0;
BA_ "GenSigSendType" SG_ 793 LHFPulseCounter 0;
BA_ "GenSigSendType" SG_ 793 RHFPulseCounter 0;
BA_ "GenSigSendType" SG_ 793 RHRPulseCounterFailSts 0;
BA_ "GenSigSendType" SG_ 793 RHRPulseCounter 0;
BA_ "GenSigSendType" SG_ 793 LHFPulseCounterFailSts 0;
BA_ "GenSigSendType" SG_ 793 RHFPulseCounterFailSts 0;
BA_ "GenSigSendType" SG_ 793 LHRPulseCounterFailSts 0;
BA_ "GenSigSendType" SG_ 793 LHRPulseCounter 0;
BA_ "GenSigSendType" SG_ 787 ABS_ESP_3_AVHSts 0;
BA_ "GenSigSendType" SG_ 787 ABS_ESP_3_AVHFailSts 0;
BA_ "GenSigSendType" SG_ 1913 DMC_BCM_EBS_RES 1;
BA_ "GenSigSendType" SG_ 2041 DMC_ACU_RES_EDR 1;
BA_ "GenSigSendType" SG_ 2030 DMC_DCDC_RES 1;
BA_ "GenSigSendType" SG_ 2029 DMC_BMS_RES 1;
BA_ "GenSigSendType" SG_ 2027 DMC_BSG1_RES 1;
BA_ "GenSigSendType" SG_ 2025 DMC_OBD_RESP_TCU 1;
BA_ "GenSigSendType" SG_ 2024 DMC_OBD_EMS_RES 1;
BA_ "GenSigSendType" SG_ 2014 DMC_SHU3L_RES 1;
BA_ "GenSigSendType" SG_ 2009 DMC_SHU2R_RES 1;
BA_ "GenSigSendType" SG_ 2008 DMC_SHU2M_RES 1;
BA_ "GenSigSendType" SG_ 2007 DMC_SHU2L_RES 1;
BA_ "GenSigSendType" SG_ 2006 DMC_SHU3R_RES 1;
BA_ "GenSigSendType" SG_ 1982 DMC_SRFR_RES 1;
BA_ "GenSigSendType" SG_ 1981 DMC_SRFG_RES 1;
BA_ "GenSigSendType" SG_ 1980 DMC_SAUR_RES 1;
BA_ "GenSigSendType" SG_ 1979 DMC_RRPLM_RES 1;
BA_ "GenSigSendType" SG_ 1978 DMC_RRFLM_RES 1;
BA_ "GenSigSendType" SG_ 1977 DMC_RLPLM_RES 1;
BA_ "GenSigSendType" SG_ 1976 DMC_RLFLM_RES 1;
BA_ "GenSigSendType" SG_ 1975 DMC_SAUP_RES 1;
BA_ "GenSigSendType" SG_ 1974 DMC_SHU1P_RES 1;
BA_ "GenSigSendType" SG_ 1951 DMC_SAUD_RES 1;
BA_ "GenSigSendType" SG_ 1949 DMC_NFC_RES 1;
BA_ "GenSigSendType" SG_ 1946 DMC__AIPMR_RES 1;
BA_ "GenSigSendType" SG_ 1945 DMC__AIPM_RES 1;
BA_ "GenSigSendType" SG_ 1938 DMC_SHU1D_RES 1;
BA_ "GenSigSendType" SG_ 1936 DMC_SCU_RES 1;
BA_ "GenSigSendType" SG_ 1919 DMC_RHM_RES 1;
BA_ "GenSigSendType" SG_ 1918 DMC_LHM_RES 1;
BA_ "GenSigSendType" SG_ 1917 DMC_ESCL_RES 1;
BA_ "GenSigSendType" SG_ 1916 DMC_PLG_RES 1;
BA_ "GenSigSendType" SG_ 1910 DMC_AVM_RES 1;
BA_ "GenSigSendType" SG_ 1907 DMC_RADAR_RES 1;
BA_ "GenSigSendType" SG_ 1906 DMC_CGW_RES 1;
BA_ "GenSigSendType" SG_ 1904 DMC_BDM_RES 1;
BA_ "GenSigSendType" SG_ 1885 DMC_IMMO_RES 1;
BA_ "GenSigSendType" SG_ 1883 DMC_CLM_RES 1;
BA_ "GenSigSendType" SG_ 1880 DMC_DBL_RES 1;
BA_ "GenSigSendType" SG_ 1879 DMC_ICM_RES 1;
BA_ "GenSigSendType" SG_ 1878 DMC_ACU_RES 1;
BA_ "GenSigSendType" SG_ 1855 DMC_FRM_RES 1;
BA_ "GenSigSendType" SG_ 1854 DMC_FCM_RES 1;
BA_ "GenSigSendType" SG_ 1851 DMC_EGS_RES 1;
BA_ "GenSigSendType" SG_ 1848 DMC_TPMS_RES 1;
BA_ "GenSigSendType" SG_ 1844 DMC_EPS_RES 1;
BA_ "GenSigSendType" SG_ 1840 DMC_ESP_RES 1;
BA_ "GenSigSendType" SG_ 1823 DMC_GSI_RES 1;
BA_ "GenSigSendType" SG_ 1811 DMC_TCU_RES 1;
BA_ "GenSigSendType" SG_ 1810 DMC_AWD_RES 1;
BA_ "GenSigSendType" SG_ 1809 DMC_FPC_RES 1;
BA_ "GenSigSendType" SG_ 1808 DMC_EMS_RES 1;
BA_ "GenSigSendType" SG_ 2005 DMC_CVBOX_RES 1;
BA_ "GenSigSendType" SG_ 1948 DMC_HUD_RES 1;
BA_ "GenSigSendType" SG_ 1874 DMC_DCM_RES 1;
BA_ "GenSigSendType" SG_ 1843 DMC_PPMI_RES 1;
BA_ "GenSigSendType" SG_ 1905 DMC_SAM_RES 1;
BA_ "GenSigSendType" SG_ 2028 DMC_MCUR_RES 1;
BA_ "GenSigSendType" SG_ 2026 DMC_HCU_RES 1;
BA_ "GenSigSendType" SG_ 1847 DMC_ASU_RES 1;
BA_ "GenSigSendType" SG_ 2004 DMC_RRCR_RES 1;
BA_ "GenSigSendType" SG_ 2003 DMC_RLCR_RES 1;
BA_ "GenSigSendType" SG_ 2002 DMC_FRCR_RES 1;
BA_ "GenSigSendType" SG_ 2001 DMC_FLCR_RES 1;
BA_ "GenSigSendType" SG_ 2000 DMC_IDCU_RES 1;
BA_ "GenSigSendType" SG_ 1897 DMC_BCM_EBS_REQ 1;
BA_ "GenSigSendType" SG_ 1999 DMC_REQ_Broadcast 1;
BA_ "GenSigSendType" SG_ 2033 DMC_ACU_REQ_EDR 1;
BA_ "GenSigSendType" SG_ 2019 DMC_BSG1_REQ 1;
BA_ "GenSigSendType" SG_ 2017 DMC_OBD_REQ_TCU 1;
BA_ "GenSigSendType" SG_ 2016 DMC_OBD_EMS_REQ 1;
BA_ "GenSigSendType" SG_ 1998 DMC_SHU3L_REQ 1;
BA_ "GenSigSendType" SG_ 1993 DMC_SHU2R_REQ 1;
BA_ "GenSigSendType" SG_ 1992 DMC_SHU2M_REQ 1;
BA_ "GenSigSendType" SG_ 1991 DMC_SHU2L_REQ 1;
BA_ "GenSigSendType" SG_ 1990 DMC_SHU3R_REQ 1;
BA_ "GenSigSendType" SG_ 1966 DMC_SRFR_REQ 1;
BA_ "GenSigSendType" SG_ 1965 DMC_SRFG_REQ 1;
BA_ "GenSigSendType" SG_ 1964 DMC_SAUR_REQ 1;
BA_ "GenSigSendType" SG_ 1963 DMC_RRPLM_REQ 1;
BA_ "GenSigSendType" SG_ 1962 DMC_RRFLM_REQ 1;
BA_ "GenSigSendType" SG_ 1961 DMC_RLPLM_REQ 1;
BA_ "GenSigSendType" SG_ 1960 DMC_RLFLM_REQ 1;
BA_ "GenSigSendType" SG_ 1959 DMC_SAUP_REQ 1;
BA_ "GenSigSendType" SG_ 1958 DMC_SHU1P_REQ 1;
BA_ "GenSigSendType" SG_ 1943 DMC_EAMP_RES 1;
BA_ "GenSigSendType" SG_ 1942 DMC__ACP_RES 1;
BA_ "GenSigSendType" SG_ 1941 DMC_DVR_RES 1;
BA_ "GenSigSendType" SG_ 1939 DMC_CWC_RES 1;
BA_ "GenSigSendType" SG_ 1935 DMC_SAUD_REQ 1;
BA_ "GenSigSendType" SG_ 1933 DMC_NFC_REQ 1;
BA_ "GenSigSendType" SG_ 1930 DMC_AIPMR_REQ 1;
BA_ "GenSigSendType" SG_ 1929 DMC_AIPM_REQ 1;
BA_ "GenSigSendType" SG_ 1927 DMC_EAMP_REQ 1;
BA_ "GenSigSendType" SG_ 1926 DMC__ACP_REQ 1;
BA_ "GenSigSendType" SG_ 1925 DMC_DVR_REQ 1;
BA_ "GenSigSendType" SG_ 1923 DMC_CWC_REQ 1;
BA_ "GenSigSendType" SG_ 1922 DMC_SHU1D_REQ 1;
BA_ "GenSigSendType" SG_ 1920 DMC_SCU_REQ 1;
BA_ "GenSigSendType" SG_ 1903 DMC_RHM_REQ 1;
BA_ "GenSigSendType" SG_ 1902 DMC_LHM_REQ 1;
BA_ "GenSigSendType" SG_ 1901 DMC_ESCL_REQ 1;
BA_ "GenSigSendType" SG_ 1900 DMC_PLG_REQ 1;
BA_ "GenSigSendType" SG_ 1894 DMC_AVM_REQ 1;
BA_ "GenSigSendType" SG_ 1891 DMC_RADAR_REQ 1;
BA_ "GenSigSendType" SG_ 1890 DMC_CGW_REQ 1;
BA_ "GenSigSendType" SG_ 1888 DMC_BDM_REQ 1;
BA_ "GenSigSendType" SG_ 1869 DMC_IMMO_REQ 1;
BA_ "GenSigSendType" SG_ 1867 DMC_CLM_REQ 1;
BA_ "GenSigSendType" SG_ 1864 DMC_DBL_REQ 1;
BA_ "GenSigSendType" SG_ 1863 DMC_ICM_REQ 1;
BA_ "GenSigSendType" SG_ 1862 DMC_ACU_REQ 1;
BA_ "GenSigSendType" SG_ 1839 DMC_FRM_REQ 1;
BA_ "GenSigSendType" SG_ 1838 DMC_FCM_REQ 1;
BA_ "GenSigSendType" SG_ 1835 DMC_EGS_REQ 1;
BA_ "GenSigSendType" SG_ 1832 DMC_TPMS_REQ 1;
BA_ "GenSigSendType" SG_ 1828 DMC_EPS_REQ 1;
BA_ "GenSigSendType" SG_ 1824 DMC_ESP_REQ 1;
BA_ "GenSigSendType" SG_ 1807 DMC_GSI_REQ 1;
BA_ "GenSigSendType" SG_ 1795 DMC_TCU_REQ 1;
BA_ "GenSigSendType" SG_ 1794 DMC_AWD_REQ 1;
BA_ "GenSigSendType" SG_ 1793 DMC_FPC_REQ 1;
BA_ "GenSigSendType" SG_ 1792 DMC_EMS_REQ 1;
BA_ "GenSigSendType" SG_ 1989 DMC_CVBOX_REQ 1;
BA_ "GenSigSendType" SG_ 1932 DMC_HUD_REQ 1;
BA_ "GenSigSendType" SG_ 1858 DMC_DCM_REQ 1;
BA_ "GenSigSendType" SG_ 1827 DMC_PPMI_REQ 1;
BA_ "GenSigSendType" SG_ 1889 DMC_SAM_REQ 1;
BA_ "GenSigSendType" SG_ 2020 DMC_MCUR_REQ 1;
BA_ "GenSigSendType" SG_ 2022 DMC_DCDC_REQ 1;
BA_ "GenSigSendType" SG_ 2021 DMC_BMS_REQ 1;
BA_ "GenSigSendType" SG_ 2018 DMC_HCU_REQ 1;
BA_ "GenSigSendType" SG_ 1831 DMC_ASU_REQ 1;
BA_ "GenSigSendType" SG_ 1988 DMC_RRCR_REQ 1;
BA_ "GenSigSendType" SG_ 1987 DMC_RLCR_REQ 1;
BA_ "GenSigSendType" SG_ 1986 DMC_FRCR_REQ 1;
BA_ "GenSigSendType" SG_ 1985 DMC_FLCR_REQ 1;
BA_ "GenSigSendType" SG_ 1984 DMC_IDCU_REQ 1;
BA_ "GenSigSendType" SG_ 1560 WakeupSource_IHU 0;
BA_ "GenSigSendType" SG_ 1560 usrData4_IHU 0;
BA_ "GenSigSendType" SG_ 1560 usrData3_IHU 0;
BA_ "GenSigSendType" SG_ 1560 usrData2_IHU 0;
BA_ "GenSigSendType" SG_ 1560 ECUSPEC_AWAKE_IHU 0;
BA_ "GenSigSendType" SG_ 1560 DIAGNOSTIC_AWAKE_IHU 0;
BA_ "GenSigSendType" SG_ 1560 IGNITION_AWAKE_IHU 0;
BA_ "GenSigSendType" SG_ 1560 NETWORK_AWAKE_IHU 0;
BA_ "GenSigSendType" SG_ 1560 ECUSPEC_WAKEUP_IHU 0;
BA_ "GenSigSendType" SG_ 1560 NETWORK_WAKEUP_IHU 0;
BA_ "GenSigSendType" SG_ 1560 RESET_WAKEUP_IHU 0;
BA_ "GenSigSendType" SG_ 1560 IGNITION_WAKEUP_IHU 0;
BA_ "GenSigSendType" SG_ 1560 usrData0_IHU 0;
BA_ "GenSigSendType" SG_ 1560 NMm_IHU_Reserved1 0;
BA_ "GenSigSendType" SG_ 1560 RMR_IHU 0;
BA_ "GenSigStartValue" SG_ 1560 srcNodeID_IHU 24;
BA_ "GenSigSendType" SG_ 1560 srcNodeID_IHU 0;
BA_ "GenSigSendType" SG_ 1266 TBOX_SetAVMVeiw 2;
BA_ "GenSigSendType" SG_ 1266 TBOX_SetAVMOnReq 2;
BA_ "GenSigSendType" SG_ 1312 TBOX_1_RemDiagSts 0;
BA_ "GenSigSendType" SG_ 1243 HUD_1_Reserved 0;
BA_ "GenSigSendType" SG_ 1243 STAT_ADASDisplayPoision 0;
BA_ "GenSigSendType" SG_ 1243 STAT_NavigationDisplay 0;
BA_ "GenSigSendType" SG_ 1243 STAT_ADASDisplay 0;
BA_ "GenSigSendType" SG_ 1243 STAT_BluetoothDisplay 0;
BA_ "GenSigSendType" SG_ 1243 HUD_1_HUDHiTWarn 0;
BA_ "GenSigSendType" SG_ 1243 STAT_FaceIDOnOFF 0;
BA_ "GenSigSendType" SG_ 1243 STAT_HUDBrightness 0;
BA_ "GenSigSendType" SG_ 1243 STAT_HUD 0;
BA_ "GenSigSendType" SG_ 1243 STAT_HUDProfileID 0;
BA_ "GenSigSendType" SG_ 1243 STAT_HUDDisplayMod 0;
BA_ "GenSigSendType" SG_ 1243 STAT_HUDDisplayOnOff 0;
BA_ "GenSigSendType" SG_ 1243 STAT_HUDHeight 0;
BA_ "GenSigSendType" SG_ 1140 STAT_AMPESEVol 0;
BA_ "GenSigSendType" SG_ 1140 STAT_AMPWelVol 0;
BA_ "GenSigSendType" SG_ 1140 STAT_AMPBTMediVol 0;
BA_ "GenSigSendType" SG_ 1140 STAT_AMPTEMP 0;
BA_ "GenSigSendType" SG_ 1140 STAT_AMPMute 0;
BA_ "GenSigSendType" SG_ 1140 STAT_AMPSpeedVolume 0;
BA_ "GenSigSendType" SG_ 1140 EAMP_2_HdrestSpkrMod 0;
BA_ "GenSigSendType" SG_ 1121 STAT_AMPAlarmVolume 0;
BA_ "GenSigSendType" SG_ 1121 STAT_AMPLoudness 0;
BA_ "GenSigSendType" SG_ 1121 STAT_AMPLiveAcoustics 0;
BA_ "GenSigSendType" SG_ 1121 STAT_AMPSoundFieldFader 0;
BA_ "GenSigSendType" SG_ 1121 STAT_AMPSoundFieldBalance 0;
BA_ "GenSigSendType" SG_ 1121 STAT_AMPSoundEffectTreble 0;
BA_ "GenSigSendType" SG_ 1121 STAT_AMPSoundEffectMidrange 0;
BA_ "GenSigSendType" SG_ 1121 STAT_AMPSoundEffectBass 0;
BA_ "GenSigSendType" SG_ 1121 STAT_AMPSoundEffect 0;
BA_ "GenSigSendType" SG_ 1121 STAT_AMPRestoreDefaults 0;
BA_ "GenSigSendType" SG_ 1121 STAT_AMPDefaultVolume 0;
BA_ "GenSigSendType" SG_ 1121 STAT_AMPSoundFocus 0;
BA_ "GenSigSendType" SG_ 1121 STAT_AMPPhoneVolume 0;
BA_ "GenSigSendType" SG_ 1121 STAT_AMPMediaVolume 0;
BA_ "GenSigSendType" SG_ 1121 STAT_AMPKeyTone 0;
BA_ "GenSigSendType" SG_ 1121 STAT_AMPVRVolume 0;
BA_ "GenSigSendType" SG_ 1121 STAT_AMPNaviVolume 0;
BA_ "GenSigSendType" SG_ 1517 HUD_IHU_Interaction 1;
BA_ "GenSigSendType" SG_ 1515 IHU_HUD_Interaction 1;
BA_ "GenSigSendType" SG_ 1298 IHU_CVBOX_Interaction 1;
BA_ "GenSigSendType" SG_ 1289 CVBOX_IHU_Interaction 1;
BA_ "GenSigSendType" SG_ 759 DVR_TIHU_Interaction 1;
BA_ "GenSigSendType" SG_ 755 IHU_DVR_Interaction 1;
BA_ "GenSigSendType" SG_ 1151 TIHU_Teach_IMMO 1;
BA_ "GenSigSendType" SG_ 1116 TIHU_Auth 1;
BA_ "GenSigSendType" SG_ 1177 IHU_26_RRWinCmd 2;
BA_ "GenSigSendType" SG_ 1177 IHU_26_WiprSnvty 2;
BA_ "GenSigSendType" SG_ 1177 IHU_26_SeatLegSpprtPosnCmd 2;
BA_ "GenSigSendType" SG_ 1177 IHU_26_RLWinCmd 2;
BA_ "GenSigSendType" SG_ 1177 IHU_26_FRWinCmd 2;
BA_ "GenSigSendType" SG_ 1177 IHU_26_FLWinCmd 2;
BA_ "GenSigSendType" SG_ 1177 IHU_26_CenterLockSwt 2;
BA_ "GenSigSendType" SG_ 1177 IHU_26_SeatLvlPosnCmd 2;
BA_ "GenSigSendType" SG_ 1177 IHU_26_SeatHdrestHeiAdjmtCmd 2;
BA_ "GenSigSendType" SG_ 1177 IHU_26_WinInhbSwt 2;
BA_ "GenSigSendType" SG_ 1177 IHU_26_ReWinDefrstSwt 2;
BA_ "GenSigSendType" SG_ 1177 IHU_26_SteerWhlHeatgSwt 2;
BA_ "GenSigSendType" SG_ 1177 IHU_26_BackrAgPosnCmd 2;
BA_ "GenSigSendType" SG_ 1177 IHU_26_SeatCushPosnCmd 2;
BA_ "GenSigSendType" SG_ 1177 IHU_26_SeatHeiPosnCmd 2;
VAL_ 928 LongitudinalAccelerationSigValid 3 " Initialize" 2 " Invalid" 1 " Reserved" 0 " Valid" ;
VAL_ 926 YawrateSigValidData 3 " Initialize" 2 " Invalid" 1 " Reserved" 0 " Valid" ;
VAL_ 1206 SHU2R_RSeatVentnSts 7 " Reserved" 6 " Reserved" 5 " Reserved" 4 " Reserved" 3 " Seat Ventilation Level3" 2 " Seat Ventilation Level2" 1 " Seat Ventilation Level1" 0 " OFF" ;
VAL_ 1206 SHU2R_RSeatHeatSts 7 " Reserved" 6 " Reserved" 5 " Reserved" 4 " Reserved" 3 " Seat heating Level3" 2 " Seat heating Level2" 1 " Seat heating Level1" 0 " OFF" ;
VAL_ 1202 SHU2M_MSeatVentnSts 7 " Reserved" 6 " Reserved" 5 " Reserved" 4 " Reserved" 3 " Seat Ventilation Level3" 2 " Seat Ventilation Level2" 1 " Seat Ventilation Level1" 0 " OFF" ;
VAL_ 1202 SHU2M_MSeatHeatSts 7 " Reserved" 6 " Reserved" 5 " Reserved" 4 " Reserved" 3 " Seat heating Level3" 2 " Seat heating Level2" 1 " Seat heating Level1" 0 " OFF" ;
VAL_ 1194 SHU2L_LSeatVentnSts 7 " Reserved" 6 " Reserved" 5 " Reserved" 4 " Reserved" 3 " Seat Ventilation Level3" 2 " Seat Ventilation Level2" 1 " Seat Ventilation Level1" 0 " OFF" ;
VAL_ 1194 SHU2L_LSeatHeatSts 7 " Reserved" 6 " Reserved" 5 " Reserved" 4 " Reserved" 3 " Seat heating Level3" 2 " Seat heating Level2" 1 " Seat heating Level1" 0 " OFF" ;
VAL_ 1190 SHU1R_RSeatAutVentnSts 3 " Reserved" 2 " Reserved" 1 " ON" 0 " OFF" ;
VAL_ 1190 SHU1R_RSeatAutHeatSts 3 " Reserved" 2 " Reserved" 1 " ON" 0 " OFF" ;
VAL_ 1190 SHU1R_RSeatVentnSts 7 " Reserved" 6 " Reserved" 5 " Reserved" 4 " Reserved" 3 " Seat Ventilation Level3" 2 " Seat Ventilation Level2" 1 " Seat Ventilation Level1" 0 " OFF" ;
VAL_ 1190 SHU1R_RSeatHeatSts 7 " Reserved" 6 " Reserved" 5 " Reserved" 4 " Reserved" 3 " Seat heating Level3" 2 " Seat heating Level2" 1 " Seat heating Level1" 0 " OFF" ;
VAL_ 1186 SHU1L_LSeatAutVentnSts 3 " Reserved" 2 " Reserved" 1 " ON" 0 " OFF" ;
VAL_ 1186 SHU1L_LSeatAutHeatSts 3 " Reserved" 2 " Reserved" 1 " ON" 0 " OFF" ;
VAL_ 1186 SHU1L_LSeatVentnSts 7 " Reserved" 6 " Reserved" 5 " Reserved" 4 " Reserved" 3 " Seat Ventilation Level3" 2 " Seat Ventilation Level2" 1 " Seat Ventilation Level1" 0 " OFF" ;
VAL_ 1186 SHU1L_LSeatHeatSts 7 " Reserved" 6 " Reserved" 5 " Reserved" 4 " Reserved" 3 " Seat heating Level3" 2 " Seat heating Level2" 1 " Seat heating Level1" 0 " OFF" ;
VAL_ 1090 PsngrSeatVentilationFeedbackSts 3 " Seat Ventilation Level3" 2 " Seat Ventilation Level2" 1 " Seat Ventilation Level1" 0 " OFF" ;
VAL_ 1090 DriverSeatVentilationFeedbackSts 3 " Seat Ventilation Level3" 2 " Seat Ventilation Level2" 1 " Seat Ventilation Level1" 0 " OFF" ;
VAL_ 1090 Seat_ExtMirror_PositionInfo 31 " Not used" 30 " Not used" 29 " Not used" 28 " Not used" 27 " Not used" 26 " Not used" 25 " Not used" 24 " Not used" 23 " Not used" 22 " Not used" 21 " Not used" 20 " Not used" 19 " Not used" 18 " Not used" 17 " Not used" 16 " error" 15 " seat_ExtMirror_Pos2_Recall_ID5" 14 " seat_ExtMirror_Pos1_Recall_ID5" 13 " seat_ExtMirror_Pos0_Recall_ID5" 12 " seat_ExtMirror_Pos2_Recall_ID4" 11 " seat_ExtMirror_Pos1_Recall_ID4" 10 " seat_ExtMirror_Pos0_Recall_ID4" 9 " seat_ExtMirror_Pos2_Recall_ID3" 8 " seat_ExtMirror_Pos1_Recall_ID3" 7 " seat_ExtMirror_Pos0_Recall_ID3" 6 " seat_ExtMirror_Pos2_Recall_ID2" 5 " seat_ExtMirror_Pos1_Recall_ID2" 4 " seat_ExtMirror_Pos0_Recall_ID2" 3 " seat_ExtMirror_Pos2_Recall_ID1" 2 " seat_ExtMirror_Pos1_Recall_ID1" 1 " seat_ExtMirror_Pos0_Recall_ID1" 0 " Not active" ;
VAL_ 1090 SCURelateKeyOrFaceIDFeedbackSts 1 " Relate" 0 " Not Relate" ;
VAL_ 1090 Seat_ExtMirror_MemorySts 3 " Not Used" 2 " Failure" 1 " Success" 0 " Not Active" ;
VAL_ 1090 PsngrSeatHeatFeedbackSts 3 " Seat heating Level3" 2 " Seat heating Level2" 1 " Seat heating Level1" 0 " OFF" ;
VAL_ 1090 DriverSeatHeatFeedbackSts 3 " Seat heating Level3" 2 " Seat heating Level2" 1 " Seat heating Level1" 0 " OFF" ;
VAL_ 1090 ReverseExtMirrorFeedbackSts 3 " Both sides" 2 " Only left side" 1 " Only right side" 0 " OFF" ;
VAL_ 1090 EasyEntryFeedbackSts 1 " ON" 0 " OFF" ;
VAL_ 1090 Seat_ExtMirror_MemoryReq 1 " Request" 0 " No Request" ;
VAL_ 1090 Seat_ExtMirror_MemoryEnable 1 " Enable" 0 " Disable" ;
VAL_ 924 SteeringAngleSpeedValidData 1 " Not Valid" 0 " Valid" ;
VAL_ 924 SteeringAngleValidData 1 " Not Valid" 0 " Valid" ;
VAL_ 924 SASCalibrated 1 " Calibrated" 0 " Not calibrated" ;
VAL_ 924 AngleFailure 1 " Failure" 0 " No Failure" ;
VAL_ 498 RLCR_2_RCTBONOFFSts 3 " Reserved" 2 " OFF" 1 " ON" 0 " Not active" ;
VAL_ 498 RLCR_2_RAEBONOFFSts 3 " Reserved" 2 " OFF" 1 " ON" 0 " Not active" ;
VAL_ 1141 LHSFRadarSensorDistance 125 " Not used" 124 " Not used" 123 " Not used" 122 " Not used" 121 " Not used" 120 " Not used" 119 " Not used" 118 " Not used" 117 " Not used" 116 " Not used" 115 " Not used" 114 " Not used" 113 " Not used" 112 " Not used" 111 " Not used" 110 " Not used" 109 " Not used" 108 " Not used" 107 " Not used" 106 " Not used" 105 " Not used" 104 " Not used" 103 " Not used" 102 " Not used" 101 " Not used" 100 " Not used" 99 " Not used" 98 " Not used" 97 " Not used" 96 " Not used" 95 " Not used" ;
VAL_ 1141 RHSFRadarSensorDistance 125 " Not used" 124 " Not used" 123 " Not used" 122 " Not used" 121 " Not used" 120 " Not used" 119 " Not used" 118 " Not used" 117 " Not used" 116 " Not used" 115 " Not used" 114 " Not used" 113 " Not used" 112 " Not used" 111 " Not used" 110 " Not used" 109 " Not used" 108 " Not used" 107 " Not used" 106 " Not used" 105 " Not used" 104 " Not used" 103 " Not used" 102 " Not used" 101 " Not used" 100 " Not used" 99 " Not used" 98 " Not used" 97 " Not used" 96 " Not used" 95 " Not used" ;
VAL_ 1141 LHSRRadarSensorDistance 125 " Not used" 124 " Not used" 123 " Not used" 122 " Not used" 121 " Not used" 120 " Not used" 119 " Not used" 118 " Not used" 117 " Not used" 116 " Not used" 115 " Not used" 114 " Not used" 113 " Not used" 112 " Not used" 111 " Not used" 110 " Not used" 109 " Not used" 108 " Not used" 107 " Not used" 106 " Not used" 105 " Not used" 104 " Not used" 103 " Not used" 102 " Not used" 101 " Not used" 100 " Not used" 99 " Not used" 98 " Not used" 97 " Not used" 96 " Not used" 95 " Not used" ;
VAL_ 1141 RHSRRadarSensorDistance 125 " Not used" 124 " Not used" 123 " Not used" 122 " Not used" 121 " Not used" 120 " Not used" 119 " Not used" 118 " Not used" 117 " Not used" 116 " Not used" 115 " Not used" 114 " Not used" 113 " Not used" 112 " Not used" 111 " Not used" 110 " Not used" 109 " Not used" 108 " Not used" 107 " Not used" 106 " Not used" 105 " Not used" 104 " Not used" 103 " Not used" 102 " Not used" 101 " Not used" 100 " Not used" 99 " Not used" 98 " Not used" 97 " Not used" 96 " Not used" 95 " Not used" ;
VAL_ 1078 PLG_OperateSts 7 " Not used" 6 " Not used" 5 " Not used" 4 " Closing" 3 " Opening" 2 " Close" 1 " Open" 0 " Stop" ;
VAL_ 1042 PEPS_BLTKey_PESts 1 " ON" 0 " OFF                    " ;
VAL_ 1042 WelcomLightPollingSts 1 " Open" 0 " Close                       " ;
VAL_ 1042 PEPS_IntelligentOpenSts 1 " Open" 0 " Close                          " ;
VAL_ 1042 PEPSPollingSts 1 " Open" 0 " Close                           " ;
VAL_ 998 RemoteStartSts 2 " Remote start mode" 1 " Normal start mode" 0 " No start" ;
VAL_ 998 Start_StopRequest 6 " Reserved" 5 " Reserved" 4 " Remote stop request" 3 " Remote start request" 2 " Normal stop request" 1 " Normar start request" 0 " Not request" ;
VAL_ 998 IDInformation 7 " Transmitter BLT3" 6 " Transmitter BLT2" 5 " Transmitter BLT1" 4 " Transmitter 4" 3 " Transmitter 3" 2 " Transmitter 2" 1 " Transmitter 1" ;
VAL_ 1124 NFC_1_DispCardPosn 1 " active" 0 " not active" ;
VAL_ 1124 NFC_1_IDList 7 " NFC1&NFC2&NFC3" 6 " NFC2&NFC3    " 5 " NFC1&NFC3    " 4 " NFC1&NFC2    " 3 " NFC3" 2 " NFC2" 1 " NFC1" 0 "Not active" ;
VAL_ 1124 NFC_1_ID 3 "Transmitter NFC3 " 2 " Transmitter NFC2" 1 " Transmitter NFC1" 0 " No NFC" ;
VAL_ 864 MFS_ICM_Right 3 " invalid" 2 " Stuck" 1 " Pressed" 0 " Not action" ;
VAL_ 864 MFS_ICM_Left 3 " invalid" 2 " Stuck" 1 " Pressed" 0 " Not action" ;
VAL_ 864 MFS_ICM_Down 3 " invalid" 2 " Stuck" 1 " Pressed" 0 " Not action" ;
VAL_ 864 MFS_ICM_UP 3 " invalid" 2 " Stuck" 1 " Pressed" 0 " Not action" ;
VAL_ 864 MFS_Menu 3 " invalid" 2 " Stuck" 1 " Pressed" 0 " Not action" ;
VAL_ 945 MFS_Customize 3 " invalid" 2 "Stuck" 1 "Pressed" 0 " Not action" ;
VAL_ 945 MFS_WeChat 3 " invalid" 2 "Stuck" 1 "Pressed" 0 " Not action" ;
VAL_ 945 MFS_TJA_ICA_ON_OFF 3 " invalid" 2 " Stuck" 1 " Pressed" 0 " Not action" ;
VAL_ 945 MFS_Start_Pause 3 " invalid" 2 "Stuck" 1 "Pressed" 0 " Not action" ;
VAL_ 945 MFS_Mute 3 " invalid" 2 " Stuck" 1 " Pressed" 0 " Not action" ;
VAL_ 945 MFS_VoiceRecognition 3 " invalid" 2 " Stuck" 1 " Pressed" 0 " Not action" ;
VAL_ 945 MFS_PhoneHangUP 3 " invalid" 2 " Stuck" 1 " Pressed" 0 " Not action" ;
VAL_ 945 MFS_PhonePickUP 3 " invalid" 2 " Stuck" 1 " Pressed" 0 " Not action" ;
VAL_ 945 MFS_SeekDown 3 " invalid" 2 " Stuck" 1 " Pressed" 0 " Not action" ;
VAL_ 945 MFS_SeekUp 3 " invalid" 2 " Stuck" 1 " Pressed" 0 " Not action" ;
VAL_ 945 MFS_VolumeDown 3 " invalid" 2 " Stuck" 1 " Pressed" 0 " Not action" ;
VAL_ 945 MFS_VolumeUp 3 " invalid" 2 " Stuck" 1 " Pressed" 0 " Not action" ;
VAL_ 945 MFS_Mode 3 " invalid" 2 " Stuck" 1 " Pressed" 0 " Not action" ;
VAL_ 1248 IDCU_11_DrvAssiStylests 3 " self-defined" 2 " Old Driver" 1 " New Driver" 0 " Not active" ;
VAL_ 1248 IDCU_11_DCLCONOFFsts 3 " reserved" 2 " switch on" 1 " switch off" 0 " Not active" ;
VAL_ 1251 FCM_FRM_5_DAIONOFFSts 3 " Reserved" 2 " OFF" 1 " ON" 0 " Not active" ;
VAL_ 1251 FCM_FRM_5_SCFONOFFSts 3 " Reserved" 2 " OFF" 1 " ON" 0 " Not active" ;
VAL_ 1251 FCM_FRM_5_FCWONOFFSts 3 " Reserved" 2 " OFF" 1 " ON" 0 " Not active" ;
VAL_ 1251 FCM_FRM_5_FCWSnvtySts 3 " far" 2 " near" 1 " standard" 0 " Not active" ;
VAL_ 1251 FCM_FRM_5_AEBONOFFSts 3 " Reserved" 2 " OFF" 1 " ON" 0 " Not active" ;
VAL_ 1245 FCM_5_ELKONOFFSts 3 " Reserved" 2 " OFF" 1 " ON" 0 " Not active" ;
VAL_ 1245 FCM_5_LDWLDPSnvtySts 3 " Reserved" 2 " HighSensitivity" 1 " LowSensitivity" 0 " Not active" ;
VAL_ 1245 FCM_5_LDPONOFFSts 3 " Reserved" 2 " OFF" 1 " ON" 0 " Not active" ;
VAL_ 1245 FCM_5_WarnModSts 3 " voice and shock" 2 " only shock " 1 " only voice" 0 " Not active" ;
VAL_ 1245 FCM_5_LDWONOFFSts 3 " Reserved" 2 " OFF" 1 " ON" 0 " Not active" ;
VAL_ 1245 FCM_5_TLIONOFFSts 3 " Reserved" 2 " OFF" 1 " ON" 0 " Not active" ;
VAL_ 1245 FCM_5_TSIONOFFSts 3 " Reserved" 2 " OFF" 1 " ON" 0 " Not active" ;
VAL_ 1245 FCM_5_HMAONOFFSts 3 " Reserved" 2 " OFF" 1 " ON" 0 " Not active" ;
VAL_ 1245 FCM_5_IESONOFFSts 3 " Reserved" 2 " OFF" 1 " ON" 0 " Not active" ;
VAL_ 1245 FCM_5_SLAONOFFSts 3 " Reserved" 2 " OFF" 1 " ON" 0 " Not active" ;
VAL_ 1245 FCM_5_TJAICAExitTextInfoSts 3 " Reserved" 2 " OFF" 1 " ON" 0 " Not active" ;
VAL_ 1057 BrakePedalSts 0 " Not applied" 1 " Applied" ;
VAL_ 1057 BrakePedalStsValidData 0 " Valid" 1 " Not Valid" ;
VAL_ 1057 GasPedalPositionInvalidData 1 " Invalid" 0 " Valid" ;
VAL_ 1277 CLM_10_SeRowDispSts 1 " Active" 0 " Not active" ;
VAL_ 1277 CLM_10_RfgtLkDispSts 1 " Active" 0 " Not active" ;
VAL_ 1277 CLM_10_ReRowDispSts 1 " Active" 0 " Not active" ;
VAL_ 1277 CLM_10_ReRowBlowSpdLvlSts 7 " Level  7" 6 " Level  6" 5 " Level  5" 4 " Level  4" 3 " Level  3" 2 " Level  2" 1 " Level  1" 0 " Not Active" ;
VAL_ 1277 CLM_10_ReRowWorkSts 1 " Active" 0 " Not active" ;
VAL_ 1277 CLM_10_RmnDispSts 7 " Reserved" 6 " Reserved" 5 " Reserved" 4 " Reserved" 3 " Note3" 2 " Note2" 1 " Note1 " 0 " Not Active" ;
VAL_ 1277 CLM_10_AQSDispSts 1 " Active" 0 " Not active" ;
VAL_ 1277 SelfTestResult2 39 "Right temperature sensor fault" 38 "UV sterilization error (Reserved )" 37 "Fragrance communication error " 36 "Fragrance fan fault " 35 "Fragrance motor error" 34 "Right anion  error " 33 "Left anion  error " 32 "PTC  fault(Reserved)" 25 "Rear Booster error" 24 "External PM2.5  error " 23 "Incar PM2.5  error " 22 "Right mixture motor error" 15 "Left mixture motor error" 14 "Rear Booster Mode motor  error" 13 "Mode motor 1 error" 12 "Circulation motor error" 11 "Blower error" 10 "Left temperature sensor fault  " 9 "Frag motor error" 8 "Evaporator temperature sensor errorevaporator" 7 "AQS sensor error" 6 "Humidity sensor error" 5 "Right solar error" 4 "Left solar error" 3 "Frag Lost Communication With CLM" 2 "Left internal temperature error" 1 "External temperature error" 0 "No error,the system operates well" ;
VAL_ 1277 IntelligentCustomSts 1 " ON" 0 " Off" ;
VAL_ 1277 CLM_10_SeRowWorkSts 1 " Active" 0 " Not Active" ;
VAL_ 1277 CLM_10_SeRowBlowSpdLvlDispSts 7 " Level  7" 6 " Level  6" 5 " Level  5" 4 " Level  4" 3 " Level  3" 2 " Level  2" 1 " Level  1" 0 " Not Active" ;
VAL_ 1277 PtcHeatgSts 1 " ON" 0 " OFF" ;
VAL_ 1334 FragranCeconsistenceLevelSts 7 " Not used" 6 " Not used" 5 " Level5" 4 " Level4" 3 " Level3" 2 " Level2" 1 " Level1" 0 " Not used" ;
VAL_ 1334 Pos3_FragranceTypesSts 7 " Reserved" 6 " Unfilled                           " 5 " Reserved" 4 " Reserved                             " 3 " Type3" 2 " Type2                              " 1 " Type1  " 0 " Not active   " ;
VAL_ 1334 Pos2_FragranceTypesSts 7 " Reserved" 6 " Unfilled                           " 5 " Reserved" 4 " Reserved                             " 3 " Type3" 2 " Type2                              " 1 " Type1  " 0 " Not active   " ;
VAL_ 1334 PM2_5AutoRunSetSts 1 " Off" 0 " On " ;
VAL_ 1334 PM2_5_Incar_Level 7 " Reserved" 6 " Reserved" 5 " Serious pollution" 4 " High levels of pollution" 3 " Moderate pollution" 2 " Light pollution" 1 " Favorable pollution" 0 " Good" ;
VAL_ 1334 PM2_5_Outcar_Level 7 " Reserved" 6 " Reserved" 5 " Serious pollution" 4 " High levels of pollution" 3 " Moderate pollution" 2 " Light pollution" 1 " Favorable pollution" 0 " Good" ;
VAL_ 1334 FragranceDisplaysts 1 " Active" 0 " Not active" ;
VAL_ 1334 FragrancePositionSwt 3 " Position three  active" 2 " Position two  active" 1 " Position one active" 0 " Not active   " ;
VAL_ 1334 ACModeCustomSts 3 " Strong" 2 " Comfortable                                      " 1 " Save" 0 " Not active  " ;
VAL_ 1334 FragranceWelcomeModeSts 1 " Off" 0 " On " ;
VAL_ 1334 RefreshFunctionSts 1 " Off" 0 " On " ;
VAL_ 1334 Pos1_FragranceTypesSts 7 " Reserved" 6 " Unfilled                           " 5 " Reserved" 4 " Reserved                             " 3 " Type3" 2 " Type2                              " 1 " Type1  " 0 " Not active   " ;
VAL_ 1334 PM2_5AutoRunSts 1 " Off" 0 " On " ;
VAL_ 1334 FragranceSWSts 2 " Custom User-Defined" 1 " Off                                                                                                    " 0 " Auto" ;
VAL_ 1334 AutoBltCalllowBlowSpeedSts 1 " Off" 0 " On " ;
VAL_ 1334 AutoParkInnerCirculationSts 1 " Off" 0 " On " ;
VAL_ 1334 PM2_5_IncarSts 1 " failure" 0 " Normal" ;
VAL_ 1334 PM2_5_ExtSts 1 " failure" 0 " Normal" ;
VAL_ 1334 FragranceShortageWarning 7 " Position one and two and three shortage" 6 " Position two and three shortage " 5 " Position one and three shortage " 4 " Position three shortage " 3 " Position one and two shortage                             " 2 " Position two shortage" 1 " Position one shortage" 0 " No Warning" ;
VAL_ 1334 ION_Function_Sts 3 " Not used" 2 " Close " 1 " Open" 0 " No display" ;
VAL_ 1333 AUTODefrostDisplaySts 1 " Active" 0 " Not active" ;
VAL_ 1333 TempKnobRollingCounter 31 " 31(Reserved)" 30 " 30(Reserved)" 29 " 29(Reserved)" 28 " 28(Reserved)" 27 " 27(Reserved)" 26 " 26(Reserved)" 25 " 25(Reserved)" 24 " 24(Reserved)" 23 " 23(Reserved)" 22 " 22(Reserved)" 21 " 21(Reserved)" 20 " 20(Reserved)" 19 " 19(Reserved)" 18 " 18(Reserved)" 17 " 17(Reserved)" 16 " 16" 15 " 15" 14 " 14" 13 " 13" 12 " 12" 11 " 11" 10 " 10" 9 " 9" 8 " 8" 7 " 7" 6 " 6" 5 " 5" 4 " 4" 3 " 3" 2 " 2" 1 " 1" 0 " Not Active" ;
VAL_ 1333 BlowSpeedLevelDisplaySts 15 " Level  15" 14 " Level  14" 13 " Level  13" 12 " Level  12" 11 " Level  11" 10 " Level  10" 9 " Level  9" 8 " Level  8" 7 " Level  7" 6 " Level  6" 5 " Level  5" 4 " Level  4" 3 " Level  3" 2 " Level  2" 1 " Level  1" 0 " Not Active" ;
VAL_ 1333 AUTODefrostForceOpenSts 1 " Active" 0 " Not active" ;
VAL_ 1333 PM2_5Displaysts 1 " Active" 0 " Not active" ;
VAL_ 1333 PM2_5overproofDisplaySts 1 " Active" 0 " Not active" ;
VAL_ 1333 FiltertchangeDisplaySts 1 " Active" 0 " Not active" ;
VAL_ 1333 REARInhibitSts 1 " Inhibitt" 0 " permit" ;
VAL_ 1333 AUTODefrostOnSts 1 " On" 0 " Off" ;
VAL_ 1306 SelfTestResult 30 "Lost Communication With PEPS" 29 "Frag fan error" 28 "Right anion  error  " 27 "Left anion  error " 26 "PTC  fault(Reserved)" 25 "EAC fault(Reserved)" 24 "External PM2.5  error" 23 "Incar PM2.5  error " 22 "Lost Communication With IPM " 21 "Lost Communication With BCM " 20 "Lost Communication With RRM " 19 "Lost Communication With BSM " 18 "Lost Communication With EMS " 17 "Lost Communication With ICM " 16 "Right mixture motor error" 15 "Left mixture motor error" 14 "Mode motor 2 error" 13 "Mode motor 1 error" 12 "Circulation motor error" 11 "Blower error" 10 "AQM fault" 9 "Frag motor error" 8 "Evaporator temperature sensor errorevaporator" 7 "AQS sensor error" 6 "Humidity sensor error" 5 "Right solar error" 4 "Left solar error" 3 "Frag Lost Communication With CLM" 2 "Left internal temperature error" 1 "External temperature error" 0 "No error,the system operates well" ;
VAL_ 1306 TemperatureUnit 1 " Fahrenheit(℉)" 0 " Centigrade(℃)" ;
VAL_ 1306 ZoneSelectionDisplaySts 1 " Dual zone mode" 0 " Single zone mode" ;
VAL_ 1306 CirculationModeDisplaySts 1 " Air circulation mode" 0 " Recirculation mode" ;
VAL_ 1306 BlowDelayOffSts 1 " Not DelayOff" 0 " DelayOff" ;
VAL_ 1306 BlowAdvanceOnSts 1 " Not AdvanceOn" 0 " AdvanceOn" ;
VAL_ 1306 DisplayActive 1 " Active" 0 " Not Active" ;
VAL_ 1306 SelfTestActive 1 " Active" 0 " Not Active" ;
VAL_ 1306 PM2_5Sts 1 " Active" 0 " Not Active" ;
VAL_ 1306 WorkingSts 1 " Active" 0 " Not Active" ;
VAL_ 1306 ModeAdjustDisplaySts 7 "?BlowFace ?&?BlowFoot & Defrost" 6 "?BlowFace & Defrost " 5 "?Not?Active " 4 "?Defrost " 3 "?BlowFoot?&?Defrost " 2 "?BlowFoot " 1 "?BlowFace?&?BlowFoot " 0 "?BlowFace " ;
VAL_ 1306 FrontDeforest_MaxDisplaySts 1 " Active" 0 " Not Active" ;
VAL_ 1306 ACRequestDisplaySts 1 " Active" 0 " Not Active" ;
VAL_ 1306 AutoDisplaySts 1 " Auto Active" 0 " Auto Not Active" ;
VAL_ 1306 Reserved_AC_MaxSts 1 " Active" 0 " Not Active" ;
VAL_ 1306 ExternalTemperatureFailSts 1 " Fail Present" 0 " Fail Not Present" ;
VAL_ 1104 OBDDiagnosisReqInd 1 " Request" 0 " Not Request" ;
VAL_ 1287 BCM_22_WiprSnvtySetFb 7 " Reserved" 6 " Reserved" 5 " Reserved" 4 " Level4" 3 " Level3" 2 " Level2" 1 " Level1" 0 " Not Active" ;
VAL_ 1287 PassSeatMsgStr_LvlSts 3 "High" 2 "Middle" 1 "Low" 0 "OFF" ;
VAL_ 1287 PassSeatMsg_ModeSts 5 "Jump Mode" 4 "Relieve Mode" 3 "Cross Mode" 2 "Cat Paw Mode" 1 "Wave Mode" 0 "Initial" ;
VAL_ 746 BDM_OTAPwrOnReqFb 3 " Resrved" 2 " Fail" 1 " Success" 0 " No Command" ;
VAL_ 746 BDM_OTAPwrDwnReqFb 3 " Resrved" 2 " Fail" 1 " Success" 0 " No Command" ;
VAL_ 746 BDM_OTAModStsFb 1 " Active" 0 " InActive" ;
VAL_ 746 SlaveVehMod 7 "Reserved" 6 "Transport Paused" 5 "Factory Paused " 4 " Crash" 3 " Dyno " 2 " Normal" 1 " Transport" 0 " Factory " ;
VAL_ 746 VehPwrMod 4 " Running" 3 " Crank" 2 " ON " 1 " ACC" 0 " OFF" ;
VAL_ 901 CTP_VolPlusMinusForDVDSts 3 " Not Used" 2 " Plus" 1 " Minus" 0 " Not Active" ;
VAL_ 901 CTP_HomeKeyForIHUSts 3 " Not Used" 2 " Not Used" 1 " Active" 0 " Not active" ;
VAL_ 901 CTP_PowerKeyForIHUSts 3 " Not Used" 2 " Not Used" 1 " Active" 0 " Not active" ;
VAL_ 901 CTP_TrackMod 1 " Active" 0 " Not Active" ;
VAL_ 901 CTP_DriveModeSet 3 " Not Used" 2 " DOWN                                     " 1 " UP " 0 " Not Active                                   " ;
VAL_ 901 CTP_NavKeyForIHUSts 3 " Not Used" 2 " Not Used" 1 " Active" 0 " Not Active" ;
VAL_ 901 CTPKeyVoiceRemindReq 1 " Active" 0 " Not Active" ;
VAL_ 901 IHUSetSwitch 1 " Active" 0 " Not Active" ;
VAL_ 901 AVMSwitch 1 " Active" 0 " Not Active" ;
VAL_ 1063 TheaterDimmingColorFeedback_64 64 " Number 64??Snow??" 63 " Number 63" 62 " Number 62" 61 " Number 61" 60 " Number 60" 59 " Number 59" 58 " Number 58" 57 " Number 57" 56 " Number 56" 55 " Number 55" 54 " Number 54" 53 " Number 53" 52 " Number 52" 51 " Number 51" 50 " Number 50" 49 " Number 49" 48 " Number 48" 47 " Number 47" 46 " Number 46" 45 " Number 45" 44 " Number 44" 43 " Number 43" 42 " Number 42" 41 " Number 41" 40 " Number 40" 39 " Number 39" 38 " Number 38" 37 " Number 37" 36 " Number 36??Mud??" 35 " Number 35" 34 " Number 34" 33 " Number 33" 32 " Number 32" 31 " Number 31" 30 " Number 30" 29 " Number 29" 28 " Number 28" 27 " Number 27" 26 " Number 26" 25 " Number 25" 24 " Number 24" 23 " Number 23" 22 " Number 22" 21 " Number 21" 20 " Number 20" 19 " Number 19??Sand??" 18 " Number 18" 17 " Number 17" 16 " Number 16" 15 " Number 15" 14 " Number 14" 13 " Number 13" 12 " Number 12" 11 " Number 11" 10 " Number 10" 9 " Number 9" 8 " Number 8" 7 " Number 7" 6 " Number 6" 5 " Number 5" 4 " Number 4" 3 " Number 3(Sport)" 2 " Number 2(Normal)" 1 " Number 1(ECO)" 0 " Not Active" ;
VAL_ 1063 Rainfall 3 "Heavy Rain" 2 "Moderate Rain" 1 "Light Rain" 0 "No Rain" ;
VAL_ 1063 HUDBriUnit 3 " 1000 lux" 2 " 100 lux" 1 " 10 lux" 0 " 1 lux" ;
VAL_ 1520 MessageCounter8 3 "Startup" 1 "Range low" 0 "Range high" ;
VAL_ 1520 Secondintervalmaintainmileage3 3 "Reserved" 1 "10000" 0 "Not Present" ;
VAL_ 1520 MaintainMileage3 4 "Reserved" 3 "15000" 1 "10000" 0 "5000" ;
VAL_ 1520 Brand 3 "Reserved" 1 "Exeed" 0 "Chery" ;
VAL_ 1520 MessageCounter7 3 "Startup" 1 "Range low" 0 "Range high" ;
VAL_ 1520 InitialFuelConsumption2 4 "8.5" 3 "8.0" 1 "7.9" 0 "7.5" ;
VAL_ 1520 MessageCounter6 3 "Startup" 1 "Range low" 0 "Range high" ;
VAL_ 1520 RRCR 1 "Present" 0 "Not Present" ;
VAL_ 1520 RLCR 1 "Present" 0 "Not Present" ;
VAL_ 1520 TrafficJamAssist 1 "Present" 0 "Not Present" ;
VAL_ 1520 LaneDeparturePrevention 1 "Present" 0 "Not Present" ;
VAL_ 1520 EmergencyLaneKeeping 1 "Present" 0 "Not Present" ;
VAL_ 1520 fueltankcapacity 5 "Reserved" 4 "65L" 3 "57L" 1 "45L" 0 "51L" ;
VAL_ 1520 MessageCounter5 3 "Startup" 1 "Range low" 0 "Range high" ;
VAL_ 1520 ModelCode 9 "Reserved" 8 "T19C" 7 "T1C" 6 "M1E" 5 "T25" 4 "T1E" 3 "T22" 1 "T26" 0 "T1D" ;
VAL_ 1520 MessageCounter4 3 "Startup" 1 "Range low" 0 "Range high" ;
VAL_ 1520 NumberofDriveMode2_IHU_TIHU_ 6 "Reserved" 0 "Not Present" ;
VAL_ 1520 Facestyle 1 "configuration2" 0 "configuration1" ;
VAL_ 1520 SpeedLimit 1 "Present" 0 "Not Present" ;
VAL_ 1520 Secondintervalmaintainmileage2 4 "Not Present" 3 "configuration3" 1 "configuration2" 0 "configuration1" ;
VAL_ 1520 MaintainMileage2 4 "configuration4" 3 "configuration3" 1 "configuration2" 0 "configuration1" ;
VAL_ 1520 Defaultdrivemode 4 "Reserved" 3 "No-display" 1 "SPORT" 0 "ECO" ;
VAL_ 1520 NumberofDriveMode 4 "Not Present" ;
VAL_ 1520 ICMVehicleType 7 "Reserved" 6 "configuration 6" 5 "configuration 5" 4 "Configuration 4" 3 "Configuration 3" 1 "Configuration 2" 0 "Configuration 1" ;
VAL_ 1520 MessageCounter3 3 "Startup" 1 "Range low" 0 "Range high" ;
VAL_ 1520 RearRadarsNumber 2 "Reserved" 0 "4 " ;
VAL_ 1520 EPBWorkLogic 1 "State of the EPB" 0 "Red Yellow P Signal   " ;
VAL_ 1520 EGSType 1 "Rocker shift" 0 "Touch-tone" ;
VAL_ 1520 ThrdRowSBRandBucSwt 1 "Present" 0 "Not Present" ;
VAL_ 1520 SecRowSBRandBucSwt 1 "Present" 0 "Not Present" ;
VAL_ 1520 APA 1 "Present" 0 "Not Present" ;
VAL_ 1520 MessageCounter2 3 "Startup" 1 "Range low" 0 "Range high" ;
VAL_ 1520 LKA 1 "Present" 0 "Not Present" ;
VAL_ 1520 MessageCounter1 3 "Startup" 1 "Range low" 0 "Range high" ;
VAL_ 1520 EBS 1 "Present" 0 "Not Present" ;
VAL_ 1520 EGS 1 "Present" 0 "Not Present" ;
VAL_ 1520 SN 0 "Sequence Number" ;
VAL_ 1077 RvsExtMirrFbSts 3 " Both Sides" 2 " Only Left Side" 1 " Only Right Side" 0 " OFF" ;
VAL_ 1077 SRF_Hall2SensorError 1 " Error" 0 " Normal" ;
VAL_ 1077 SRF_Hall1SensorError 1 " Error" 0 " Normal" ;
VAL_ 1077 SRF_SunroofOverVolt 1 " OverVoltage" 0 " Normal" ;
VAL_ 1077 SRF_SunroofUnderVolt 1 " UnderVoltage" 0 " Normal" ;
VAL_ 1077 SRF_LINCommunicationERROR 1 " Error" 0 " Normal" ;
VAL_ 1077 SRF_SwitchError 1 " Error" 0 " Normal" ;
VAL_ 1077 SRF_OverHeatProtect 1 " Active" 0 " Not Active" ;
VAL_ 1077 SRF_MotorRelayError 1 " Error" 0 " Normal" ;
VAL_ 1077 AssociatedWithDriverModeFeedback 1 " ON" 0 " OFF" ;
VAL_ 1077 TheaterDimmingBrightnessFeedback 7 " Reserved" 6 " Reserved" 5 " Reserved" 4 " Level 5" 3 " Level 4" 2 " Level 3" 1 " Level 2" 0 " Level 1                  " ;
VAL_ 1077 TheaterDimmingColorFeedback 7 " Reserved" 6 " Purple" 5 " Blue" 4 " Cyan" 3 " Green" 2 " Yellow" 1 " Orange" 0 " Red                   " ;
VAL_ 1077 SRF_Sunshade_OperateSts 7 " Not Used" 6 " Half Open" 5 " Open" 4 " Closing" 3 " Stop" 2 " Opening" 1 " Close" 0 " Startup" ;
VAL_ 1077 RRWindowSts 7 " Reserved" 6 " Opening" 5 " Closing" 4 " Stop" 3 " Open" 2 " Close" 1 " Comfort" 0 " Startup" ;
VAL_ 1077 RLWindowSts 7 " Reserved" 6 " Opening" 5 " Closing" 4 " Stop" 3 " Open" 2 " Close" 1 " Comfort" 0 " Startup" ;
VAL_ 1077 WindowInhibitSts 1 " Inhibit" 0 " Permit" ;
VAL_ 1077 FRWindow_Sts 7 " Reserved" 6 " Opening" 5 " Closing" 4 " Stop" 3 " Open" 2 " Close" 1 " Comfort" 0 " Startup" ;
VAL_ 1077 FLWindow_Sts 7 " Reserved" 6 " Opening" 5 " Closing" 4 " Stop" 3 " Open" 2 " Close" 1 " Comfort" 0 " Startup" ;
VAL_ 1077 Window_OperateSts 3 " Reserved" 2 " Not active" 1 " Active" 0 " Startup" ;
VAL_ 1077 Reserved_SRF_Error 15 " Reserved" 14 " Reserved" 13 " Reserved" 12 " Reserved" 11 " Reserved" 10 " Reserved" 9 " Reserved" 8 " Hall2 Sensor Error" 7 " Hall1 Sensor Error" 6 " Sunroof Over Volt" 5 " Sunroof under volt" 4 " LIN Communication Error" 3 " Switch Error" 2 " OverHeat Protect" 1 " Motor relay Error" 0 " Start up" ;
VAL_ 1077 SRF_InitStatus 1 " Sunroof Init Complete" 0 " Sunroof Init Incomplete" ;
VAL_ 1077 AssociatedWithMusicModeFeedback 1 " ON" 0 " OFF" ;
VAL_ 1077 TheaterDimmingStatusFeedback 1 " ON" 0 " OFF" ;
VAL_ 1077 SRF_PositionSts 15 " Reserved" 14 " Reserved" 13 " Reserved" 12 " Tilt" 11 " 100%" 10 " 90%" 9 " 80%" 8 " 70%" 7 " 60%" 6 " 50%" 5 " 40%" 4 " 30%" 3 " 20%" 2 " 10%" 1 " 0" 0 " Startup" ;
VAL_ 1077 SRF_OperateSts 7 " Comfort open" 6 " Open" 5 " Closing" 4 " Stop" 3 " Opening" 2 " Close" 1 " Tilt" 0 " Startup" ;
VAL_ 1505 TCU3_CVT25_CVT18 1 " Present" 0 " Not Present" ;
VAL_ 1505 CGW 1 " Present" 0 " Not Present" ;
VAL_ 1505 MFS_LIN 1 " Present" 0 " Not Present" ;
VAL_ 1505 PLG 1 " Present" 0 " Not Present" ;
VAL_ 1505 FRM 1 " Present" 0 " Not Present" ;
VAL_ 1505 FCM 1 " Present" 0 " Not Present" ;
VAL_ 1505 TCU4_7DCT_DHT 1 " Present" 0 " Not Present" ;
VAL_ 1505 EIPM_ONCAN 1 " Present" 0 " Not Present" ;
VAL_ 1505 BSD 1 " Present" 0 " Not Present" ;
VAL_ 1505 EPB 1 " Present" 0 " Not Present" ;
VAL_ 1505 AVM 1 " Present" 0 " Not Present" ;
VAL_ 1505 RADAR 1 " Present" 0 " Not Present" ;
VAL_ 1505 SAS 1 " Present" 0 " Not Present" ;
VAL_ 1505 TPMS 1 " Present" 0 " Not Present" ;
VAL_ 1505 APM 1 " Present" 0 " Not Present" ;
VAL_ 1505 PEPS 1 " Present" 0 " Not Present" ;
VAL_ 1505 EPS 1 " Present" 0 " Not Present" ;
VAL_ 1505 CLM 1 " Present" 0 " Not Present" ;
VAL_ 1505 TCU2_6DCT 1 " Present" 0 " Not Present" ;
VAL_ 1505 TCU1_CVT19 1 " Present" 0 " Not Present" ;
VAL_ 1505 IMMO 3 "BDM integrated IMMO" 2 "PEPS integrated IMMO" 1 "Independent IMMO" 0 "Not Present" ;
VAL_ 1505 ESP 1 " Present" 0 " Not Present" ;
VAL_ 1505 ABS 1 " Present" 0 " Not Present" ;
VAL_ 1505 ABM 1 " Present" 0 " Not Present" ;
VAL_ 1505 ICM 1 " Present" 0 " Not Present" ;
VAL_ 1505 BCM 1 " Present" 0 " Not Present" ;
VAL_ 1505 EMS 1 " Present" 0 " Not Present" ;
VAL_ 913 AutoHighSpeedRequest 1 " True" 0 "False" ;
VAL_ 913 RainDetected 1 " True" 0 "False" ;
VAL_ 913 WiperSts 3 " ContinuousFast" 2 " ContinuousSlow" 1 " Auto or Intermittent" 0 " OFF" ;
VAL_ 913 SteeringWheelheatingSts 1 "Active" 0 "Not Active        " ;
VAL_ 913 RARDfstCmd 1 " Active" 0 " Off" ;
VAL_ 913 HazardLightSW 1 " Active" 0 " Not active" ;
VAL_ 554 APAFailureSts 1 " Failure" 0 " Not Failure" ;
VAL_ 554 APA_Active 1 " Active" 0 " Not active " ;
VAL_ 554 AVM_APA_SystemSts 7 " Invalid" 6 " Terminated" 5 " Failure" 4 " Completed" 3 " Guidance active" 2 " Searching" 1 " Standby" 0 " Off" ;
VAL_ 1267 AIPM_2_DriveModeSet 3 " Not Used" 2 " DOWN" 1 " UP" 0 " Not Active" ;
VAL_ 1265 PanelKeyVoiceRemindReq 1 " Request" 0 " Not active" ;
VAL_ 932 RHRWheelSpeedRawValidData 1 " Not Valid" 0 " Valid" ;
VAL_ 932 RHRWheelDriveDirection 7 " reserved" 6 " reserved" 5 " reserved" 4 " Invalid" 3 " Stop" 2 " Backward" 1 " Forward" 0 " Init" ;
VAL_ 932 LHRWheelSpeedRawValidData 1 " Not Valid" 0 " Valid" ;
VAL_ 932 LHRWheelDriveDirection 7 " reserved" 6 " reserved" 5 " reserved" 4 " Invalid" 3 " Stop" 2 " Backward" 1 " Forward" 0 " Init" ;
VAL_ 931 RHFWheelSpeedRawValidData 1 " Not Valid" 0 " Valid" ;
VAL_ 931 RHFWheelDriveDirection 7 " reserved" 6 " reserved" 5 " reserved" 4 " Invalid" 3 " Stop" 2 " Backward" 1 " Forward" 0 " Init" ;
VAL_ 931 LHFWheelSpeedRawValidData 1 " Not Valid" 0 " Valid" ;
VAL_ 931 LHFWheelDriveDirection 7 " reserved" 6 " reserved" 5 " reserved" 4 " Invalid" 3 " Stop" 2 " Backward" 1 " Forward" 0 " Init" ;
VAL_ 793 RHRPulseCounterFailSts 1 " Fail Present" 0 " Fail Not Present" ;
VAL_ 793 LHFPulseCounterFailSts 1 " Fail Present" 0 " Fail Not Present" ;
VAL_ 793 RHFPulseCounterFailSts 1 " Fail Present" 0 " Fail Not Present" ;
VAL_ 793 LHRPulseCounterFailSts 1 " Fail Present" 0 " Fail Not Present" ;
VAL_ 787 ABS_ESP_3_AVHSts 3 " Not used" 2 " Active" 1 " Standby" 0 " Off" ;
VAL_ 787 ABS_ESP_3_AVHFailSts 1 " Fail present (lamp on)" 0 " Not present" ;
VAL_ 1560 ECUSPEC_AWAKE_IHU 1 " Active" 0 " Inactive" ;
VAL_ 1560 DIAGNOSTIC_AWAKE_IHU 1 " Active" 0 " Inactive" ;
VAL_ 1560 IGNITION_AWAKE_IHU 1 " Active" 0 " Inactive" ;
VAL_ 1560 NETWORK_AWAKE_IHU 1 " Active" 0 " Inactive" ;
VAL_ 1560 ECUSPEC_WAKEUP_IHU 1 " Active" 0 " Inactive" ;
VAL_ 1560 NETWORK_WAKEUP_IHU 1 " Active" 0 " Inactive" ;
VAL_ 1560 RESET_WAKEUP_IHU 1 " Active" 0 " Inactive" ;
VAL_ 1560 IGNITION_WAKEUP_IHU 1 " Active" 0 " Inactive" ;
VAL_ 1560 usrData0_IHU 255 " User data not used" 0 " User data for current vehicle" ;
VAL_ 1560 RMR_IHU 1 " Active" 0 " Inactive" ;
VAL_ 1266 TBOX_SetAVMVeiw 7 " Not used" 6 " Not used" 5 " Not used" 4 " 2D right" 3 " 2D left" 2 " 2D Rear" 1 " 2D front" 0 " Not Active       " ;
VAL_ 1266 TBOX_SetAVMOnReq 3 " Not used" 2 " On                                                         " 1 " Off                                                   " 0 " Not Active   " ;
VAL_ 1312 TBOX_1_RemDiagSts 3 "End Read" 2 "Reading" 1 "Start Read" 0 "Not Read" ;
VAL_ 1243 STAT_ADASDisplayPoision 3 "Invalid" 2 "Ignore" 1 "ADAS right" 0 "ADAS left" ;
VAL_ 1243 STAT_NavigationDisplay 1 "Display" 0 "No Display" ;
VAL_ 1243 STAT_ADASDisplay 1 "Display" 0 "No Display" ;
VAL_ 1243 STAT_BluetoothDisplay 1 "Display" 0 "No Display" ;
VAL_ 1243 HUD_1_HUDHiTWarn 3 "Reserved" 2 "Reserved" 1 "warning" 0 "No warning" ;
VAL_ 1243 STAT_FaceIDOnOFF 1 "ON" 0 "OFF" ;
VAL_ 1243 STAT_HUDBrightness 9 "Level10" 8 "Level9" 7 "Level8" 6 "Level7" 5 "Level6" 4 "Level5" 3 "Level4" 2 "Level3" 1 "Level2" 0 "Level1" ;
VAL_ 1243 STAT_HUD 3 " Standby" 2 " Preparing" 1 " Error" 0 " Normal" ;
VAL_ 1243 STAT_HUDProfileID 7 "Ignore" 6 "Reserved" 5 "Reserved" 4 "ID5" 3 "ID4" 2 "ID3" 1 "ID2" 0 "ID1" ;
VAL_ 1243 STAT_HUDDisplayMod 2 "sport" 1 " Snowy" 0 " Normal" ;
VAL_ 1243 STAT_HUDDisplayOnOff 1 " ON" 0 " OFF" ;
VAL_ 1243 STAT_HUDHeight 15 "Reserved" 14 "Reserved" 13 "Reserved" 12 "Reserved" 11 "Reserved" 10 "Reserved" 9 "Level10" 8 "Level9" 7 "Level8" 6 "Level7" 5 "Level6" 4 "Level5" 3 "Level4" 2 "Level3" 1 "Level2" 0 "Level1" ;
VAL_ 1140 STAT_AMPESEVol 63 " Reserved" 62 " Reserved" 61 " Reserved" 60 " Reserved" 59 " Reserved" 58 " Reserved" 57 " Reserved" 56 " Reserved" 55 " Reserved" 54 " Reserved" 53 " Reserved" 52 " Reserved" 51 " Reserved" 50 " Reserved" 49 " Reserved" 48 " Reserved" 41 " Reserved" 40 " Reserved" 39 " Reserved" 38 " Reserved" 37 " Reserved" 36 " Reserved" 35 " Reserved" 34 " Reserved" 33 " Reserved" 32 " 31" 31 " 30" 30 " 29" 29 " 28" 28 " 27" 27 " 26" 26 " 25" 25 " 24" 24 " 23" 23 " 22" 22 " 21" 21 " 20" 20 " 19" 19 " 18" 18 " 17" 17 " 16" 16 " 15" 15 " 14" 14 " 13" 13 " 12" 12 " 11" 11 " 10" 10 " 9" 9 " 8" 8 " 7" 7 " 6" 6 " 5" 5 " 4" 4 " 3" 3 " 2" 2 " 1" 1 " 0 " 0 " Not Active" ;
VAL_ 1140 STAT_AMPWelVol 63 " Reserved" 62 " Reserved" 61 " Reserved" 60 " Reserved" 59 " Reserved" 58 " Reserved" 57 " Reserved" 56 " Reserved" 55 " Reserved" 54 " Reserved" 53 " Reserved" 52 " Reserved" 51 " Reserved" 50 " Reserved" 49 " Reserved" 48 " Reserved" 41 " Reserved" 40 " Reserved" 39 " Reserved" 38 " Reserved" 37 " Reserved" 36 " Reserved" 35 " Reserved" 34 " Reserved" 33 " Reserved" 32 " 31" 31 " 30" 30 " 29" 29 " 28" 28 " 27" 27 " 26" 26 " 25" 25 " 24" 24 " 23" 23 " 22" 22 " 21" 21 " 20" 20 " 19" 19 " 18" 18 " 17" 17 " 16" 16 " 15" 15 " 14" 14 " 13" 13 " 12" 12 " 11" 11 " 10" 10 " 9" 9 " 8" 8 " 7" 7 " 6" 6 " 5" 5 " 4" 4 " 3" 3 " 2" 2 " 1" 1 " 0 " 0 " Not Active" ;
VAL_ 1140 STAT_AMPBTMediVol 63 " Reserved" 62 " Reserved" 61 " Reserved" 60 " Reserved" 59 " Reserved" 58 " Reserved" 57 " Reserved" 56 " Reserved" 55 " Reserved" 54 " Reserved" 53 " Reserved" 52 " Reserved" 51 " Reserved" 50 " Reserved" 49 " Reserved" 48 " Reserved" 41 " Reserved" 40 " Reserved" 39 " Reserved" 38 " Reserved" 37 " Reserved" 36 " Reserved" 35 " Reserved" 34 " Reserved" 33 " Reserved" 32 " 31" 31 " 30" 30 " 29" 29 " 28" 28 " 27" 27 " 26" 26 " 25" 25 " 24" 24 " 23" 23 " 22" 22 " 21" 21 " 20" 20 " 19" 19 " 18" 18 " 17" 17 " 16" 16 " 15" 15 " 14" 14 " 13" 13 " 12" 12 " 11" 11 " 10" 10 " 9" 9 " 8" 8 " 7" 7 " 6" 6 " 5" 5 " 4" 4 " 3" 3 " 2" 2 " 1" 1 " 0 " 0 " Not Active" ;
VAL_ 1140 STAT_AMPTEMP 7 " Reserved" 6 " Reserved" 5 " Reserved" 4 " Reserved" 3 " 3" 2 " 2" 1 " 1" 0 " Not Active" ;
VAL_ 1140 STAT_AMPMute 3 " reserved" 2 " OFF" 1 " ON" 0 " Not Active" ;
VAL_ 1140 STAT_AMPSpeedVolume 7 " Reserved" 6 " Reserved" 5 " Reserved" 4 " High" 3 " Middle" 2 " Low" 1 " OFF" 0 " Not Active" ;
VAL_ 1140 EAMP_2_HdrestSpkrMod 7 "reserved" 6 "reserved " 5 "reserved" 4 "reserved" 3 "Private mode" 2 "Drive mode" 1 "Shared mode" 0 "Not Active" ;
VAL_ 1121 STAT_AMPAlarmVolume 15 " Reserved" 14 " Reserved" 13 " Reserved" 12 " Reserved" 11 " Reserved" 10 " 10" 9 " 9" 8 " 8" 7 " 7" 6 " 6" 5 " 5" 4 " 4" 3 " 3" 2 " 2" 1 " 1" 0 " Not Active" ;
VAL_ 1121 STAT_AMPLoudness 3 " reserved" 2 " OFF" 1 " ON" 0 " Not Active" ;
VAL_ 1121 STAT_AMPLiveAcoustics 3 " reserved" 2 " OFF" 1 " ON" 0 " Not Active" ;
VAL_ 1121 STAT_AMPSoundFieldFader 15 " 7" 14 " 6" 13 " 5" 12 " 4" 11 " 3" 10 " 2" 9 " 1" 8 " 0" 7 " -1" 6 " -2" 5 " -3" 4 " -4" 3 " -5" 2 " -6" 1 " -7" 0 " Not Active" ;
VAL_ 1121 STAT_AMPSoundFieldBalance 15 " 7" 14 " 6" 13 " 5" 12 " 4" 11 " 3" 10 " 2" 9 " 1" 8 " 0" 7 " -1" 6 " -2" 5 " -3" 4 " -4" 3 " -5" 2 " -6" 1 " -7" 0 " Not Active" ;
VAL_ 1121 STAT_AMPSoundEffectTreble 15 " 7" 14 " 6" 13 " 5" 12 " 4" 11 " 3" 10 " 2" 9 " 1" 8 " 0" 7 " -1" 6 " -2" 5 " -3" 4 " -4" 3 " -5" 2 " -6" 1 " -7" 0 " Not Active" ;
VAL_ 1121 STAT_AMPSoundEffectMidrange 15 " 7" 14 " 6" 13 " 5" 12 " 4" 11 " 3" 10 " 2" 9 " 1" 8 " 0" 7 " -1" 6 " -2" 5 " -3" 4 " -4" 3 " -5" 2 " -6" 1 " -7" 0 " Not Active" ;
VAL_ 1121 STAT_AMPSoundEffectBass 15 " 7" 14 " 6" 13 " 5" 12 " 4" 11 " 3" 10 " 2" 9 " 1" 8 " 0" 7 " -1" 6 " -2" 5 " -3" 4 " -4" 3 " -5" 2 " -6" 1 " -7" 0 " Not Active" ;
VAL_ 1121 STAT_AMPSoundEffect 15 " Reserved" 14 " Reserved" 13 " Reserved" 12 " Reserved" 11 " Reserved" 10 " Reserved" 9 "  Reserved" 8 " Rural model" 7 " Vocals mode" 6 " Rock mode" 5 " Classic mode" 4 " Jazz mode" 3 " Popular mode" 2 " Standard mode " 1 " Customer-defined mode" 0 " Not Active" ;
VAL_ 1121 STAT_AMPRestoreDefaults 3 " Reserved" 2 " OFF" 1 " ON" 0 " Not Active" ;
VAL_ 1121 STAT_AMPDefaultVolume 63 " Reserved" 62 " Reserved" 61 " Reserved" 60 " Reserved" 59 " Reserved" 58 " Reserved" 57 " Reserved" 56 " Reserved" 55 " Reserved" 54 " Reserved" 53 " Reserved" 52 " Reserved" 51 " Reserved" 50 " Reserved" 49 " Reserved" 48 " Reserved" 41 " Reserved" 40 " Reserved" 39 " Reserved" 38 " Reserved" 37 " Reserved" 36 " Reserved" 35 " Reserved" 34 " Reserved" 33 " Reserved" 32 " 31" 31 " 30" 30 " 29" 29 " 28" 28 " 27" 27 " 26" 26 " 25" 25 " 24" 24 " 23" 23 " 22" 22 " 21" 21 " 20" 20 " 19" 19 " 18" 18 " 17" 17 " 16" 16 " 15" 15 " 14" 14 " 13" 13 " 12" 12 " 11" 11 " 10" 10 " 9" 9 " 8" 8 " 7" 7 " 6" 6 " 5" 5 " 4" 4 " 3" 3 " 2" 2 " 1" 1 " 0 " 0 " Not Active" ;
VAL_ 1121 STAT_AMPSoundFocus 0 " Not Active" ;
VAL_ 1121 STAT_AMPPhoneVolume 31 " Reserved" 30 " Reserved" 29 " Reserved" 28 " Reserved" 27 " Reserved" 26 " 25" 25 " 24" 24 " 23" 23 " 22" 22 " 21" 21 " 20" 20 " 19" 19 " 18" 18 " 17" 17 " 16" 16 " 15" 15 " 14" 14 " 13" 13 " 12" 12 " 11" 11 " 10" 10 " 9" 9 " 8" 8 " 7" 7 " 6" 6 " 5" 5 " 4" 4 " 3" 3 " 2" 2 " 1" 1 " 0 " 0 " Not Active" ;
VAL_ 1121 STAT_AMPMediaVolume 63 " Reserved" 62 " Reserved" 61 " Reserved" 60 " Reserved" 59 " Reserved" 58 " Reserved" 57 " Reserved" 56 " Reserved" 55 " Reserved" 54 " Reserved" 53 " Reserved" 52 " Reserved" 51 " Reserved" 50 " Reserved" 49 " Reserved" 48 " Reserved" 41 " Reserved" 40 " Reserved" 39 " Reserved" 38 " Reserved" 37 " Reserved" 36 " Reserved" 35 " Reserved" 34 " Reserved" 33 " Reserved" 32 " 31" 31 " 30" 30 " 29" 29 " 28" 28 " 27" 27 " 26" 26 " 25" 25 " 24" 24 " 23" 23 " 22" 22 " 21" 21 " 20" 20 " 19" 19 " 18" 18 " 17" 17 " 16" 16 " 15" 15 " 14" 14 " 13" 13 " 12" 12 " 11" 11 " 10" 10 " 9" 9 " 8" 8 " 7" 7 " 6" 6 " 5" 5 " 4" 4 " 3" 3 " 2" 2 " 1" 1 " 0 " 0 " Not Active" ;
VAL_ 1121 STAT_AMPKeyTone 3 " reserved" 2 " OFF" 1 " ON" 0 " Not Active" ;
VAL_ 1121 STAT_AMPVRVolume 15 " Reserved" 14 " Reserved" 13 " Reserved" 12 " Reserved" 11 " 10" 10 " 9" 9 " 8" 8 " 7" 7 " 6" 6 " 5" 5 " 4" 4 " 3" 3 " 2" 2 " 1" 1 " 0 " 0 " Not Active" ;
VAL_ 1121 STAT_AMPNaviVolume 15 " Reserved" 14 " Reserved" 13 " Reserved" 12 " Reserved" 11 " 10" 10 " 9" 9 " 8" 8 " 7" 7 " 6" 6 " 5" 5 " 4" 4 " 3" 3 " 2" 2 " 1" 1 " 0 " 0 " Not Active" ;
VAL_ 1177 IHU_26_RRWinCmd 127 "Reserved" 126 "Reserved" 125 "Reserved" 124 "Reserved" 123 "Reserved" 122 "Reserved" 121 "Reserved" 120 "Reserved" 119 "Reserved" 118 "Reserved" 117 "Reserved" 116 "Reserved" 115 "Reserved" 114 "Reserved" 113 "Reserved" 112 "Reserved" 111 "Reserved" 110 "Reserved" 109 "Reserved" 108 "Reserved" 107 "Reserved" 106 "Reserved" 105 "Reserved" 104 "Reserved" 103 "Reserved" 102 "Reserved" 101 "Reserved" 100 "100%" 99 "99%" 98 "98%" 97 "97%" 96 "96%" 95 "95%" 94 "94%" 93 "93%" 92 "92%" 91 "91%" 90 "90%" 89 "89%" 88 "88%" 87 "87%" 86 "86%" 85 "85%" 84 "84%" 83 "83%" 82 "82%" 81 "81%" 80 "80%" 79 "79%" 78 "78%" 77 "77%" 76 "76%" 75 "75%" 74 "74%" 73 "73%" 72 "72%" 71 "71%" 70 "70%" 69 "69%" 68 "68%" 67 "67%" 66 "66%" 65 "65%" 64 "64%" 63 "63%" 62 "62%" 61 "61%" 60 "60%" 59 "59%" 58 "58%" 57 "57%" 56 "56%" 55 "55%" 54 "54%" 53 "53%" 52 "52%" 51 "51%" 50 "50%" 49 "49%" 48 "48%" 47 "47%" 46 "46%" 45 "45%" 44 "44%" 43 "43%" 42 "42%" 41 "41%" 40 "40%" 39 "39%" 38 "38%" 37 "37%" 36 "36%" 35 "35%" 34 "34%" 33 "33%" 32 "32%" 31 "31%" 30 "30%" 29 "29%" 28 "28%" 27 "27%" 26 "26%" 25 "25%" 24 "24%" 23 "23%" 22 "22%" 21 "21%" 20 "20%" 19 "19%" 18 "18%" 17 "17%" 16 "16%" 15 "15%" 14 "14%" 13 "13%" 12 "12%" 11 "11%" 10 "10%" 9 "9%" 8 "8%" 7 "7%" 6 "6%" 5 "5%" 4 "4%" 3 "3%" 2 "2%" 1 "1%" 0 "Not active" ;
VAL_ 1177 IHU_26_WiprSnvty 6 "Reserved" 5 "Reserved" 4 "Level4" 3 "Level3" 2 "Level2" 1 "Level1" 0 "Not Active" ;
VAL_ 1177 IHU_26_SeatLegSpprtPosnCmd 15 "Reserved" 14 "Reserved" 13 "Reserved" 12 "Reserved" 11 "100%" 10 "90% " 9 "80% " 8 "70% " 7 "60% " 6 "50% " 5 "40% " 4 "30% " 3 "20% " 2 "10% " 1 "0% " 0 "Not active " ;
VAL_ 1177 IHU_26_RLWinCmd 127 "Reserved" 126 "Reserved" 125 "Reserved" 124 "Reserved" 123 "Reserved" 122 "Reserved" 121 "Reserved" 120 "Reserved" 119 "Reserved" 118 "Reserved" 117 "Reserved" 116 "Reserved" 115 "Reserved" 114 "Reserved" 113 "Reserved" 112 "Reserved" 111 "Reserved" 110 "Reserved" 109 "Reserved" 108 "Reserved" 107 "Reserved" 106 "Reserved" 105 "Reserved" 104 "Reserved" 103 "Reserved" 102 "Reserved" 101 "Reserved" 100 "100%" 99 "99%" 98 "98%" 97 "97%" 96 "96%" 95 "95%" 94 "94%" 93 "93%" 92 "92%" 91 "91%" 90 "90%" 89 "89%" 88 "88%" 87 "87%" 86 "86%" 85 "85%" 84 "84%" 83 "83%" 82 "82%" 81 "81%" 80 "80%" 79 "79%" 78 "78%" 77 "77%" 76 "76%" 75 "75%" 74 "74%" 73 "73%" 72 "72%" 71 "71%" 70 "70%" 69 "69%" 68 "68%" 67 "67%" 66 "66%" 65 "65%" 64 "64%" 63 "63%" 62 "62%" 61 "61%" 60 "60%" 59 "59%" 58 "58%" 57 "57%" 56 "56%" 55 "55%" 54 "54%" 53 "53%" 52 "52%" 51 "51%" 50 "50%" 49 "49%" 48 "48%" 47 "47%" 46 "46%" 45 "45%" 44 "44%" 43 "43%" 42 "42%" 41 "41%" 40 "40%" 39 "39%" 38 "38%" 37 "37%" 36 "36%" 35 "35%" 34 "34%" 33 "33%" 32 "32%" 31 "31%" 30 "30%" 29 "29%" 28 "28%" 27 "27%" 26 "26%" 25 "25%" 24 "24%" 23 "23%" 22 "22%" 21 "21%" 20 "20%" 19 "19%" 18 "18%" 17 "17%" 16 "16%" 15 "15%" 14 "14%" 13 "13%" 12 "12%" 11 "11%" 10 "10%" 9 "9%" 8 "8%" 7 "7%" 6 "6%" 5 "5%" 4 "4%" 3 "3%" 2 "2%" 1 "1%" 0 "Not active" ;
VAL_ 1177 IHU_26_FRWinCmd 127 "Reserved" 126 "Reserved" 125 "Reserved" 124 "Reserved" 123 "Reserved" 122 "Reserved" 121 "Reserved" 120 "Reserved" 119 "Reserved" 118 "Reserved" 117 "Reserved" 116 "Reserved" 115 "Reserved" 114 "Reserved" 113 "Reserved" 112 "Reserved" 111 "Reserved" 110 "Reserved" 109 "Reserved" 108 "Reserved" 107 "Reserved" 106 "Reserved" 105 "Reserved" 104 "Reserved" 103 "Reserved" 102 "Reserved" 101 "Reserved" 100 "100%" 99 "99%" 98 "98%" 97 "97%" 96 "96%" 95 "95%" 94 "94%" 93 "93%" 92 "92%" 91 "91%" 90 "90%" 89 "89%" 88 "88%" 87 "87%" 86 "86%" 85 "85%" 84 "84%" 83 "83%" 82 "82%" 81 "81%" 80 "80%" 79 "79%" 78 "78%" 77 "77%" 76 "76%" 75 "75%" 74 "74%" 73 "73%" 72 "72%" 71 "71%" 70 "70%" 69 "69%" 68 "68%" 67 "67%" 66 "66%" 65 "65%" 64 "64%" 63 "63%" 62 "62%" 61 "61%" 60 "60%" 59 "59%" 58 "58%" 57 "57%" 56 "56%" 55 "55%" 54 "54%" 53 "53%" 52 "52%" 51 "51%" 50 "50%" 49 "49%" 48 "48%" 47 "47%" 46 "46%" 45 "45%" 44 "44%" 43 "43%" 42 "42%" 41 "41%" 40 "40%" 39 "39%" 38 "38%" 37 "37%" 36 "36%" 35 "35%" 34 "34%" 33 "33%" 32 "32%" 31 "31%" 30 "30%" 29 "29%" 28 "28%" 27 "27%" 26 "26%" 25 "25%" 24 "24%" 23 "23%" 22 "22%" 21 "21%" 20 "20%" 19 "19%" 18 "18%" 17 "17%" 16 "16%" 15 "15%" 14 "14%" 13 "13%" 12 "12%" 11 "11%" 10 "10%" 9 "9%" 8 "8%" 7 "7%" 6 "6%" 5 "5%" 4 "4%" 3 "3%" 2 "2%" 1 "1%" 0 "Not active" ;
VAL_ 1177 IHU_26_FLWinCmd 127 "Reserved" 126 "Reserved" 125 "Reserved" 124 "Reserved" 123 "Reserved" 122 "Reserved" 121 "Reserved" 120 "Reserved" 119 "Reserved" 118 "Reserved" 117 "Reserved" 116 "Reserved" 115 "Reserved" 114 "Reserved" 113 "Reserved" 112 "Reserved" 111 "Reserved" 110 "Reserved" 109 "Reserved" 108 "Reserved" 107 "Reserved" 106 "Reserved" 105 "Reserved" 104 "Reserved" 103 "Reserved" 102 "Reserved" 101 "Reserved" 100 "100%" 99 "99%" 98 "98%" 97 "97%" 96 "96%" 95 "95%" 94 "94%" 93 "93%" 92 "92%" 91 "91%" 90 "90%" 89 "89%" 88 "88%" 87 "87%" 86 "86%" 85 "85%" 84 "84%" 83 "83%" 82 "82%" 81 "81%" 80 "80%" 79 "79%" 78 "78%" 77 "77%" 76 "76%" 75 "75%" 74 "74%" 73 "73%" 72 "72%" 71 "71%" 70 "70%" 69 "69%" 68 "68%" 67 "67%" 66 "66%" 65 "65%" 64 "64%" 63 "63%" 62 "62%" 61 "61%" 60 "60%" 59 "59%" 58 "58%" 57 "57%" 56 "56%" 55 "55%" 54 "54%" 53 "53%" 52 "52%" 51 "51%" 50 "50%" 49 "49%" 48 "48%" 47 "47%" 46 "46%" 45 "45%" 44 "44%" 43 "43%" 42 "42%" 41 "41%" 40 "40%" 39 "39%" 38 "38%" 37 "37%" 36 "36%" 35 "35%" 34 "34%" 33 "33%" 32 "32%" 31 "31%" 30 "30%" 29 "29%" 28 "28%" 27 "27%" 26 "26%" 25 "25%" 24 "24%" 23 "23%" 22 "22%" 21 "21%" 20 "20%" 19 "19%" 18 "18%" 17 "17%" 16 "16%" 15 "15%" 14 "14%" 13 "13%" 12 "12%" 11 "11%" 10 "10%" 9 "9%" 8 "8%" 7 "7%" 6 "6%" 5 "5%" 4 "4%" 3 "3%" 2 "2%" 1 "1%" 0 "Not active" ;
VAL_ 1177 IHU_26_CenterLockSwt 3 " Reserved" 2 " LOCK" 1 " UNLOCK" 0 " Not Active" ;
VAL_ 1177 IHU_26_SeatLvlPosnCmd 15 "Reserved" 14 "Reserved" 13 "Reserved" 12 "Reserved" 11 "100%" 10 "90% " 9 "80% " 8 "70% " 7 "60% " 6 "50% " 5 "40% " 4 "30% " 3 "20% " 2 "10% " 1 "0% " 0 "Not active " ;
VAL_ 1177 IHU_26_SeatHdrestHeiAdjmtCmd 15 "Reserved" 14 "Reserved" 13 "Reserved" 12 "Reserved" 11 "Reserved" 10 "100%" 9 "90%" 8 "80%" 7 "70%" 6 "60%" 5 "50%" 4 "40%" 3 "30%" 2 "20%" 1 "10%" 0 "Not active" ;
VAL_ 1177 IHU_26_WinInhbSwt 1 " Active" 0 " Not active" ;
VAL_ 1177 IHU_26_ReWinDefrstSwt 1 " Active" 0 " Not active" ;
VAL_ 1177 IHU_26_SteerWhlHeatgSwt 1 " Active" 0 " Not active" ;
VAL_ 1177 IHU_26_BackrAgPosnCmd 31 "Reserved" 30 "Reserved" 29 "Reserved" 28 "Reserved" 27 "Reserved" 26 "Reserved" 25 "Reserved" 24 "Reserved" 23 "Reserved" 22 "Reserved" 21 "100%" 20 "95%" 19 "90%" 18 "85%" 17 "80%" 16 "75%" 15 "70%" 14 "65%" 13 "60%" 12 "55%" 11 "50%" 10 "45% " 9 "40% " 8 "35% " 7 "30% " 6 "25% " 5 "20% " 4 "15% " 3 "10% " 2 "5% " 1 "0% " 0 "Not active " ;
VAL_ 1177 IHU_26_SeatCushPosnCmd 15 "Reserved" 14 "Reserved" 13 "Reserved" 12 "Reserved" 11 "Reserved" 10 "100%" 9 "90%" 8 "80%" 7 "70%" 6 "60%" 5 "50%" 4 "40%" 3 "30%" 2 "20%" 1 "10%" 0 "Not active" ;
VAL_ 1177 IHU_26_SeatHeiPosnCmd 15 "Reserved" 14 "Reserved" 13 "Reserved" 12 "Reserved" 11 "100%" 10 "90% " 9 "80% " 8 "70% " 7 "60% " 6 "50% " 5 "40% " 4 "30% " 3 "20% " 2 "10% " 1 "0% " 0 "Not active " ;
